VERSION "Version"

NS_ :

BS_:

BU_: Tester CCU ADC CCU_CCURT1 CCU_CCURT2 RLR RRR ZCUF ZCUL ZCUR ZCUT EMS IDM DCDC IPS NIDU DCUR OBC OPC LPC CPC EMCM GCU DCUF IPU BMS EOPR EVCC DCDC2 EDL SRS ECS EPS EPB RBM IBCS ICM IID IDC PHUDD AMP WHUD IMR INU IFC FAPA PAS PCS SCMR SCMRL SCMRR SCMRM MFS WSM DRM IDU FCP LBMSAD AVAS ATSS DLPFL FBLCM FLISD FLLCM FRLCM RLLCMA RLLCMB RRLCMA RRLCMB RLISD DLPML DLPMR TRM PSDL PSDR HVSPRL HVSPRR RFR SBM WCM ETC TBOX2 TBOX IDUR CBM PLGM TMC LPC2 SCMT RCP RRISD LBMS RLBMS CCURT1 CCURT2 RT1_C1 RT2_C3 RT1_C0 OTAWL RAS EBB RCICP WCMFR WCMRL SAS CD

BO_ 947 ADC_8: 64 ADC
 SG_ ADC_8_CRC : 7|16@0+ (1,0) [0|65535] ""  CCU,CCURT1,CCURT2,RT1_C1,RT2_C3,FAPA
 SG_ ADC_8_Counter : 23|8@0+ (1,0) [0|255] ""  CCU,CCURT1,CCURT2,RT1_C1,RT2_C3,FAPA
 SG_ ADC_LowBeamReq : 31|2@0+ (1,0) [0|3] ""  CCU,CCURT1,CCURT2,RT1_C1,RT2_C3,FAPA
 SG_ ADC_IHBC_HighBeamReq : 29|1@0+ (1,0) [0|1] ""  CCU,CCURT1,CCURT2,RT1_C1,RT2_C3,FAPA
 SG_ ADC_FlashReq : 28|2@0+ (1,0) [0|3] ""  CCU,CCURT1,CCURT2,RT1_C1,RT2_C3,FAPA
 SG_ ADC_PositionLampReq : 26|2@0+ (1,0) [0|3] ""  CCU,CCURT1,CCURT2,RT1_C1,RT2_C3,FAPA
 SG_ ADC_SunroofOpenCloseReq : 121|2@0+ (1,0) [0|3] ""  CCU
 SG_ ADC_SOCWakeupHVReq : 24|1@0+ (1,0) [0|1] ""  CCU,CCURT1,RT1_C1
 SG_ ADC_HVACCtrlReq : 39|1@0+ (1,0) [0|1] ""  CCU,CCURT1,RT1_C1,FAPA
 SG_ ADC_FFogLightReq : 38|2@0+ (1,0) [0|3] ""  CCU,CCURT1,CCURT2,RT1_C1,RT2_C3,FAPA
 SG_ ADC_RFogLightReq : 36|2@0+ (1,0) [0|3] ""  CCU,CCURT1,CCURT2,RT1_C1,RT2_C3,FAPA
 SG_ ADC_HornReq : 34|3@0+ (1,0) [0|7] ""  CCU,CCURT1,CCURT2,RT1_C1,RT2_C3,FAPA
 SG_ ADC_FWiperReq : 47|3@0+ (1,0) [0|7] ""  CCU,CCURT1,CCURT2,RT1_C0,RT1_C1,RT2_C3,FAPA
 SG_ ADC_RWiperReq : 44|3@0+ (1,0) [0|7] ""  CCU,CCURT1,CCURT2,RT1_C0,RT1_C1,RT2_C3,FAPA
 SG_ ADC_FWaterSprayReq : 41|2@0+ (1,0) [0|3] ""  CCU,CCURT1,CCURT2,RT1_C0,RT1_C1,RT2_C3,FAPA
 SG_ ADC_RWaterSprayReq : 55|2@0+ (1,0) [0|3] ""  CCU,CCURT1,CCURT2,RT1_C0,RT1_C1,RT2_C3,FAPA
 SG_ ADC_CCUReqVD : 53|1@0+ (1,0) [0|1] ""  CCU,CCURT1,CCURT2,RT1_C1,RT2_C3,FAPA
 SG_ ADC_WindowOpenReq : 50|1@0+ (1,0) [0|1] ""  CCU,CCURT1,CCURT2,RT1_C1,RT2_C3,FAPA
 SG_ ADC_WindowCloseReq : 49|1@0+ (1,0) [0|1] ""  CCU,CCURT1,CCURT2,RT1_C1,RT2_C3,FAPA
 SG_ ADC_PLGMOpenReq : 48|1@0+ (1,0) [0|1] ""  CCU,CCURT1,CCURT2,RT1_C1,RT2_C3,FAPA
 SG_ ADC_PLGMCloseReq : 63|1@0+ (1,0) [0|1] ""  CCU,CCURT1,CCURT2,RT1_C1,RT2_C3,FAPA
 SG_ ADC_FDemistReq : 60|2@0+ (1,0) [0|3] ""  CCU,CCURT1,RT1_C1,FAPA
 SG_ ADC_RDemistReq : 58|2@0+ (1,0) [0|3] ""  CCU,CCURT1,RT1_C1,FAPA
 SG_ ADC_ThmPostRun : 56|1@0+ (1,0) [0|1] ""  CCU,CCURT1,RT1_C1,FAPA
 SG_ ADC_DriverFaceWindReq : 71|2@0+ (1,0) [0|3] ""  CCU,CCURT1,RT1_C1,FAPA
 SG_ ADC_EcallReq : 69|1@0+ (1,0) [0|1] ""  CCU,CCURT1,RT1_C1,FAPA,TBOX
 SG_ ADC_FlowReq : 68|5@0+ (0.25,0) [0|7.75] "L/min"  CCU,CCURT1,RT1_C1,FAPA
 SG_ ADC_DriverSeatBeltPretightenReq : 79|1@0+ (1,0) [0|1] ""  CCU,CCURT1,RT1_C1,FAPA
 SG_ ADC_LockReq : 78|3@0+ (1,0) [0|7] ""  CCU,CCURT1,CCURT2,RT1_C1,RT2_C3,FAPA
 SG_ ADC_HoldLockReq : 75|2@0+ (1,0) [0|3] ""  CCU,CCURT1,CCURT2,RT1_C1,RT2_C3,FAPA
 SG_ ADC_RearMirrorReq : 73|2@0+ (1,0) [0|3] ""  CCU,CCURT1,CCURT2,RT1_C1,RT2_C3,FAPA
 SG_ ADC_HoldRearMirrorReq : 87|2@0+ (1,0) [0|3] ""  CCU,CCURT1,CCURT2,RT1_C1,RT2_C3,FAPA
 SG_ ADC_ADSLightReq : 90|3@0+ (1,0) [0|7] ""  CCU,CCURT1,CCURT2,RT1_C1,RT2_C3,FAPA
 SG_ ADC_DriverSeatBeltVibrWarnReq : 83|3@0+ (1,0) [0|7] ""  CCU,CCURT1,RT1_C1,FAPA
 SG_ ADC_FrtWindshildHeatReq : 92|2@0+ (1,0) [0|3] ""  CCU,CCURT1,RT1_C1,FAPA
 SG_ ADC_BeamSwReq : 94|2@0+ (1,0) [0|3] ""  CCU,CCURT1,CCURT2,RT1_C1,RT2_C3,FAPA
 SG_ IFC_SysCalibrationSt : 80|2@0+ (1,0) [0|3] ""  CCU,CCURT1,RT1_C1,FAPA
 SG_ ADC_ADBIHBCEnableReq : 99|2@0+ (1,0) [0|3] ""  CCU,CCURT1,CCURT2,RT1_C1,RT2_C3,FAPA
 SG_ ADC_LowPowerReqVD_A : 107|1@0+ (1,0) [0|1] ""  CCU,CCURT1,RT1_C1,INU,FAPA
 SG_ ADC_LowPowerReq_A : 106|2@0+ (1,0) [0|3] ""  CCU,CCURT1,RT1_C1,INU,FAPA
 SG_ ADC_MachineStatus : 124|3@0+ (1,0) [0|7] ""  CCU,CCURT1,RT1_C1,FAPA
 SG_ ADC_LowPowerFailReason : 127|3@0+ (1,0) [0|7] ""  CCU,CCURT1,RT1_C1,FAPA
 SG_ ADC_LightbarReq : 135|4@0+ (1,0) [0|15] "/"  CCU,CCURT1,RT1_C1,FAPA
 SG_ ADC_ChgPortControlReq : 129|2@0+ (1,0) [0|3] ""  CCU,CCURT1,RT1_C1,FAPA
 SG_ ADC_ChgPortHoldControlReq : 131|2@0+ (1,0) [0|3] ""  CCU,CCURT1,RT1_C1,FAPA
 SG_ ADC_ChargHoldReq : 137|2@0+ (1,0) [0|3] ""  CCU,CCURT1,RT1_C1,FAPA
 SG_ ADC_ChargReq : 139|2@0+ (1,0) [0|3] ""  CCU,CCURT1,RT1_C1,FAPA
 SG_ ADC_ChargGunHoldReq : 141|2@0+ (1,0) [0|3] ""  CCU,CCURT1,RT1_C1,FAPA
 SG_ ADC_ChargGunReq : 143|2@0+ (1,0) [0|3] ""  CCU,CCURT1,RT1_C1,FAPA
 SG_ ADC_MCURTTemp : 151|8@0+ (1,-40) [-40|215] "℃"  CCU,CCURT1,RT1_C1,FAPA
 SG_ ADC_SOCRTtemp : 159|8@0+ (1,-40) [-40|215] "℃"  CCU,CCURT1,RT1_C1,FAPA
 SG_ ADC_InteractLightReq : 167|5@0+ (1,0) [0|31] ""  CCU,CCURT1,RT1_C1,FAPA
 SG_ Reserved1 : 440|1@0+ (1,0) [0|1] ""  CCU,FAPA

BO_ 175 ADC_9: 64 ADC
 SG_ ADC_9_CRC : 7|16@0+ (1,0) [0|65535] ""  CCU
 SG_ ADC_9_Counter : 23|8@0+ (1,0) [0|255] ""  CCU
 SG_ ADC_PAAChallengeReceive : 29|1@0+ (1,0) [0|1] ""  CCU
 SG_ PAA_TimeStampYear : 28|5@0+ (1,2020) [2020|2051] "y"  CCU
 SG_ ADC_PAAChallenge1SBM : 39|8@0+ (1,0) [0|255] ""  CCU
 SG_ ADC_PAAChallenge2SBM : 47|8@0+ (1,0) [0|255] ""  CCU
 SG_ ADC_PAAChallenge1TEL : 55|8@0+ (1,0) [0|255] ""  CCU
 SG_ ADC_PAAChallenge2TEL : 63|8@0+ (1,0) [0|255] ""  CCU
 SG_ PAA_TimeStampMonth : 71|4@0+ (1,0) [1|12] "m"  CCU
 SG_ PAA_TimeStampDay : 67|5@0+ (1,0) [1|31] "h"  CCU
 SG_ PAA_TimeStampHour : 78|5@0+ (1,0) [0|23] "d"  CCU
 SG_ PAA_TimeStampMin : 73|6@0+ (1,0) [0|59] "min"  CCU
 SG_ PAA_TimeStampSec : 83|6@0+ (1,0) [0|59] "s"  CCU
 SG_ PAA_TimeStampMilliSec : 93|4@0+ (100,0) [0|900] "ms"  CCU
 SG_ ADC_APAActPushSt : 97|2@0+ (1,0) [0|3] ""  CCU
 SG_ PAA_DVRTriggerId : 89|5@0+ (1,0) [0|31] ""  CCU
 SG_ PAA_DVRTrigger : 100|1@0+ (1,0) [0|1] ""  CCU
 SG_ ADC_LCAEnableSt : 99|2@0+ (1,0) [0|3] ""  CCU
 SG_ ADC_HPALearningPathUniqueID : 111|64@0+ (1,0) [0|0] ""  CCU

BO_ 135 ADC_VIMCode: 16 ADC
 SG_ ADC_VIMCode : 7|128@0+ (1,0) [0|3.40282366920938E+38] ""  CCU,CCURT1,RT1_C0

BO_ 1234 RLR_DiagCode: 64 ADC
 SG_ RLR_DTCCode : 7|512@0+ (1,0) [0|0] ""  CCU

BO_ 1235 RRR_DiagCode: 64 ADC
 SG_ RRR_DTCCode : 7|512@0+ (1,0) [0|0] ""  CCU

BO_ 1785 ADC_MCU_Diag_Response: 64 ADC
 SG_ ADC_MCU_Diag_Response : 7|64@0+ (1,0) [0|0] ""  Tester

BO_ 127 ADC_IMMO: 1 ADC
 SG_ ADC_IMMO : 7|8@0+ (1,0) [0|255] ""  CCU,CCURT1,RT1_C0

BO_ 1934 ADC_Diag_Tx: 64 ADC
 SG_ ADC_Diag_Response : 7|512@0+ (1,0) [0|0] ""  Vector__XXX

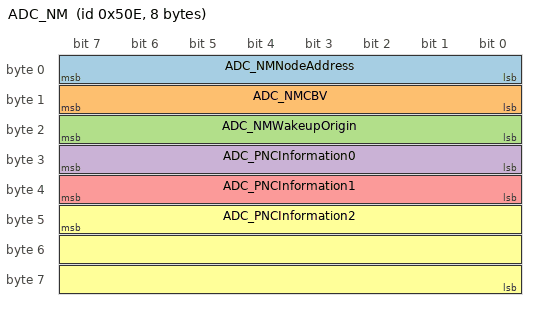
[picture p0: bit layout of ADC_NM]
BO_ 1294 ADC_NM: 8 ADC
 SG_ ADC_NMNodeAddress : 7|8@0+ (1,0) [0|255] ""  CCU,CCURT1
 SG_ ADC_NMCBV : 15|8@0+ (1,0) [0|0] ""  CCU,CCURT1
 SG_ ADC_NMWakeupOrigin : 23|8@0+ (1,0) [0|255] ""  CCU,CCURT1
 SG_ ADC_PNCInformation0 : 31|8@0+ (1,0) [0|255] ""  CCU,CCURT1
 SG_ ADC_PNCInformation1 : 39|8@0+ (1,0) [0|255] ""  CCU,CCURT1
 SG_ ADC_PNCInformation2 : 47|24@0+ (1,0) [0|0] ""  CCU,CCURT1

BO_ 1188 ADC_BigDataDTC: 64 ADC
 SG_ ADC_DTC : 7|512@0+ (1,0) [0|0] ""  CCU

BO_ 969 ADC_14: 64 ADC
 SG_ ADAS_RemoterParkingOnlineOrNot : 31|8@0+ (1,0) [0|255] ""  CCU,CCURT1,RT1_C0,RT1_C1
 SG_ ADC_RpaParkAuthn : 33|2@0+ (1,0) [0|3] ""  CCU,CCURT1,RT1_C1
 SG_ ADC_RemParkPatSel : 35|2@0+ (1,0) [0|2] ""  CCU,CCURT1,RT1_C1
 SG_ ADC_ParkDirCfm : 39|4@0+ (1,0) [0|8] ""  CCU,CCURT1,RT1_C1
 SG_ ADC_ParkStMac : 44|5@0+ (1,0) [0|31] ""  CCU,CCURT1,RT1_C1
 SG_ ADC_PwrOnOffReq : 47|3@0+ (1,0) [0|7] ""  CCU,CCURT1,RT1_C0,RT1_C1
 SG_ ADC_ParkOutDir_ParaLe : 48|1@0+ (1,0) [0|1] ""  CCU
 SG_ ADC_ParkOutDir_ParaRi : 49|1@0+ (1,0) [0|1] ""  CCU
 SG_ ADC_ParkOutDir_PerpFwd : 50|1@0+ (1,0) [0|1] ""  CCU
 SG_ ADC_ParkOutDir_PerpLeFwd : 51|1@0+ (1,0) [0|1] ""  CCU
 SG_ ADC_ParkOutDir_PerpRiFwd : 52|1@0+ (1,0) [0|1] ""  CCU
 SG_ ADC_ParkOutDir_PerpLeBack : 53|1@0+ (1,0) [0|1] ""  CCU
 SG_ ADC_ParkOutDir_PerpRiBack : 54|1@0+ (1,0) [0|1] ""  CCU
 SG_ ADC_ParkOutDir_PerpBack : 55|1@0+ (1,0) [0|1] ""  CCU
 SG_ ADC_APA_RPAFctUnavlMsg1 : 56|1@0+ (1,0) [0|1] ""  CCU
 SG_ ADC_APA_RPAFctUnavlMsg2 : 57|1@0+ (1,0) [0|1] ""  CCU
 SG_ ADC_APA_RPAFctUnavlMsg3 : 58|1@0+ (1,0) [0|1] ""  CCU
 SG_ ADC_APA_RPAFctUnavlMsg4 : 59|1@0+ (1,0) [0|1] ""  CCU
 SG_ ADC_APA_RPAFctUnavlMsg5 : 60|1@0+ (1,0) [0|1] ""  CCU
 SG_ ADC_APA_RPAFctUnavlMsg6 : 61|1@0+ (1,0) [0|1] ""  CCU
 SG_ ADC_APA_RPAFctUnavlMsg7 : 62|1@0+ (1,0) [0|1] ""  CCU
 SG_ ADC_APA_RPAFctUnavlMsg8 : 63|1@0+ (1,0) [0|1] ""  CCU
 SG_ ADC_APA_RPAFctUnavlMsg9 : 64|1@0+ (1,0) [0|1] ""  CCU
 SG_ ADC_APA_RPAFctUnavlMsg10 : 65|1@0+ (1,0) [0|1] ""  CCU
 SG_ ADC_APA_RPAFctUnavlMsg11 : 66|1@0+ (1,0) [0|1] ""  CCU
 SG_ ADC_APA_RPAFctUnavlMsg12 : 67|1@0+ (1,0) [0|1] ""  CCU
 SG_ ADC_APA_RPAFctUnavlMsg13 : 68|1@0+ (1,0) [0|1] ""  CCU
 SG_ ADC_APA_RPAFctUnavlMsg14 : 69|1@0+ (1,0) [0|1] ""  CCU
 SG_ ADC_APA_RPAFctUnavlMsg15 : 70|1@0+ (1,0) [0|1] ""  CCU
 SG_ ADC_APA_RPAFctUnavlMsg16 : 71|1@0+ (1,0) [0|1] ""  CCU
 SG_ ADC_APA_RPAFctUnavlMsg17 : 72|1@0+ (1,0) [0|1] ""  CCU
 SG_ ADC_APA_RPAFctUnavlMsg18 : 73|1@0+ (1,0) [0|1] ""  CCU
 SG_ ADC_APA_RPAFctUnavlMsg19 : 74|1@0+ (1,0) [0|1] ""  CCU
 SG_ ADC_APA_RPAFctUnavlMsg20 : 75|1@0+ (1,0) [0|1] ""  CCU
 SG_ ADC_APA_RPAFctUnavlMsg21 : 76|1@0+ (1,0) [0|1] ""  CCU
 SG_ ADC_APA_RPAFctUnavlMsg22 : 77|1@0+ (1,0) [0|1] ""  CCU
 SG_ ADC_APA_RPAFctUnavlMsg23 : 78|1@0+ (1,0) [0|1] ""  CCU
 SG_ ADC_APA_RPAFctUnavlMsg24 : 79|1@0+ (1,0) [0|1] ""  CCU
 SG_ ADC_APA_RPAFctUnavlMsg25 : 80|1@0+ (1,0) [0|1] ""  CCU
 SG_ ADC_APA_RPACnclMsg1 : 81|1@0+ (1,0) [0|1] ""  CCU
 SG_ ADC_APA_RPACnclMsg2 : 82|1@0+ (1,0) [0|1] ""  CCU
 SG_ ADC_APA_RPACnclMsg3 : 83|1@0+ (1,0) [0|1] ""  CCU
 SG_ ADC_APA_RPACnclMsg4 : 84|1@0+ (1,0) [0|1] ""  CCU
 SG_ ADC_APA_RPACnclMsg5 : 85|1@0+ (1,0) [0|1] ""  CCU
 SG_ ADC_APA_RPACnclMsg6 : 86|1@0+ (1,0) [0|1] ""  CCU
 SG_ ADC_APA_RPACnclMsg7 : 87|1@0+ (1,0) [0|1] ""  CCU
 SG_ ADC_APA_RPACnclMsg8 : 88|1@0+ (1,0) [0|1] ""  CCU
 SG_ ADC_APA_RPACnclMsg9 : 89|1@0+ (1,0) [0|1] ""  CCU
 SG_ ADC_APA_RPACnclMsg10 : 90|1@0+ (1,0) [0|1] ""  CCU
 SG_ ADC_APA_RPACnclMsg11 : 91|1@0+ (1,0) [0|1] ""  CCU
 SG_ ADC_APA_RPACnclMsg12 : 92|1@0+ (1,0) [0|1] ""  CCU
 SG_ ADC_APA_RPACnclMsg13 : 93|1@0+ (1,0) [0|1] ""  CCU
 SG_ ADC_APA_RPACnclMsg14 : 94|1@0+ (1,0) [0|1] ""  CCU
 SG_ ADC_APA_RPACnclMsg15 : 95|1@0+ (1,0) [0|1] ""  CCU
 SG_ ADC_APA_RPACnclMsg16 : 96|1@0+ (1,0) [0|1] ""  CCU
 SG_ ADC_APA_RPACnclMsg17 : 97|1@0+ (1,0) [0|1] ""  CCU
 SG_ ADC_APA_RPACnclMsg18 : 98|1@0+ (1,0) [0|1] ""  CCU
 SG_ ADC_APA_RPACnclMsg19 : 99|1@0+ (1,0) [0|1] ""  CCU
 SG_ ADC_APA_RPACnclMsg20 : 100|1@0+ (1,0) [0|1] ""  CCU
 SG_ ADC_APA_RPAPauseMsg1 : 101|1@0+ (1,0) [0|1] ""  CCU
 SG_ ADC_APA_RPAPauseMsg2 : 102|1@0+ (1,0) [0|1] ""  CCU
 SG_ ADC_APA_RPAPauseMsg3 : 103|1@0+ (1,0) [0|1] ""  CCU
 SG_ ADC_APA_RPAPauseMsg4 : 104|1@0+ (1,0) [0|1] ""  CCU
 SG_ ADC_APA_RPAPauseMsg5 : 105|1@0+ (1,0) [0|1] ""  CCU
 SG_ ADC_APA_RPAPauseMsg6 : 106|1@0+ (1,0) [0|1] ""  CCU
 SG_ ADC_APA_RPAPauseMsg7 : 107|1@0+ (1,0) [0|1] ""  CCU
 SG_ ADC_APA_RPAPauseMsg8 : 108|1@0+ (1,0) [0|1] ""  CCU
 SG_ ADC_APA_RPAPauseMsg9 : 109|1@0+ (1,0) [0|1] ""  CCU
 SG_ ADC_APA_RPAPauseMsg10 : 110|1@0+ (1,0) [0|1] ""  CCU
 SG_ ADC_PathPlanPos1X : 119|10@0+ (0.1,-50) [-50|50] "m"  CCU
 SG_ ADC_PathPlanPos1Y : 125|10@0+ (0.1,-50) [-50|50] "m"  CCU
 SG_ ADC_PathPlanPos2X : 131|10@0+ (0.1,-50) [-50|50] "m"  CCU
 SG_ ADC_PathPlanPos2Y : 137|10@0+ (0.1,-50) [-50|50] "m"  CCU
 SG_ ADC_PathPlanPos3X : 159|10@0+ (0.1,-50) [-50|50] "m"  CCU
 SG_ ADC_PathPlanPos3Y : 165|10@0+ (0.1,-50) [-50|50] "m"  CCU
 SG_ ADC_PathPlanPos4X : 171|10@0+ (0.1,-50) [-50|50] "m"  CCU
 SG_ ADC_PathPlanPos4Y : 177|10@0+ (0.1,-50) [-50|50] "m"  CCU
 SG_ ADC_PathPlanPos5X : 199|10@0+ (0.1,-50) [-50|50] "m"  CCU
 SG_ ADC_PathPlanPos5Y : 205|10@0+ (0.1,-50) [-50|50] "m"  CCU
 SG_ ADC_PathPlanPos6X : 211|10@0+ (0.1,-50) [-50|50] "m"  CCU
 SG_ ADC_PathPlanPos6Y : 217|10@0+ (0.1,-50) [-50|50] "m"  CCU
 SG_ ADC_PathPlanPos7X : 239|10@0+ (0.1,-50) [-50|50] "m"  CCU
 SG_ ADC_PathPlanPos7Y : 245|10@0+ (0.1,-50) [-50|50] "m"  CCU
 SG_ ADC_PathPlanPos8X : 251|10@0+ (0.1,-50) [-50|50] "m"  CCU
 SG_ ADC_PathPlanPos8Y : 257|10@0+ (0.1,-50) [-50|50] "m"  CCU
 SG_ ADC_PathPlanPos9X : 279|10@0+ (0.1,-50) [-50|50] "m"  CCU
 SG_ ADC_PathPlanPos9Y : 285|10@0+ (0.1,-50) [-50|50] "m"  CCU
 SG_ ADC_PathPlanPos10X : 291|10@0+ (0.1,-50) [-50|50] "m"  CCU
 SG_ ADC_PathPlanPos10Y : 297|10@0+ (0.1,-50) [-50|50] "m"  CCU
 SG_ ADC_PathPlanPos11X : 319|10@0+ (0.1,-50) [-50|50] "m"  CCU
 SG_ ADC_PathPlanPos11Y : 325|10@0+ (0.1,-50) [-50|50] "m"  CCU
 SG_ ADC_PathPlanPos12X : 331|10@0+ (0.1,-50) [-50|50] "m"  CCU
 SG_ ADC_PathPlanPos12Y : 337|10@0+ (0.1,-50) [-50|50] "m"  CCU
 SG_ ADC_PathPlanPos13X : 359|10@0+ (0.1,-50) [-50|50] "m"  CCU
 SG_ ADC_PathPlanPos13Y : 365|10@0+ (0.1,-50) [-50|50] "m"  CCU
 SG_ ADC_PathPlanPos14X : 371|10@0+ (0.1,-50) [-50|50] "m"  CCU
 SG_ ADC_PathPlanPos14Y : 377|10@0+ (0.1,-50) [-50|50] "m"  CCU
 SG_ ADC_PathPlanPos15X : 399|10@0+ (0.1,-50) [-50|50] "m"  CCU
 SG_ ADC_PathPlanPos15Y : 405|10@0+ (0.1,-50) [-50|50] "m"  CCU
 SG_ ADC_PathPlanPos16X : 411|10@0+ (0.1,-50) [-50|50] "m"  CCU
 SG_ ADC_PathPlanPos16Y : 417|10@0+ (0.1,-50) [-50|50] "m"  CCU
 SG_ ADC_PathPlanPos17X : 439|10@0+ (0.1,-50) [-50|50] "m"  CCU
 SG_ ADC_PathPlanPos17Y : 445|10@0+ (0.1,-50) [-50|50] "m"  CCU
 SG_ ADC_PathPlanPos18X : 451|10@0+ (0.1,-50) [-50|50] "m"  CCU
 SG_ ADC_PathPlanPos18Y : 457|10@0+ (0.1,-50) [-50|50] "m"  CCU
 SG_ ADC_PathPlanPos19X : 479|10@0+ (0.1,-50) [-50|50] "m"  CCU
 SG_ ADC_PathPlanPos19Y : 485|10@0+ (0.1,-50) [-50|50] "m"  CCU
 SG_ ADC_PathPlanPos20X : 491|10@0+ (0.1,-50) [-50|50] "m"  CCU
 SG_ ADC_PathPlanPos20Y : 497|10@0+ (0.1,-50) [-50|50] "m"  CCU

BO_ 970 ADC_15: 64 ADC
 SG_ ADC_AutEve : 27|4@0+ (1,0) [0|15] ""  CCU
 SG_ ADC_SeldParkID : 31|4@0+ (1,0) [0|10] ""  CCU
 SG_ ADC_VehParkMod : 39|3@0+ (1,0) [0|2] ""  CCU
 SG_ ADC_ParkProgs : 36|7@0+ (1,0) [0|100] "%"  CCU
 SG_ ADC_ParkRmngDst : 479|9@0+ (0.1,0) [0|50] "m"  CCU
 SG_ ADC_ObstclDst : 55|5@0+ (1,0) [0|31] ""  CCU
 SG_ ADC_parkInterruptDuration : 50|8@0+ (1,0) [0|255] "s"  CCU
 SG_ ADC_EPS_SteeringAngle : 58|16@0+ (0.1,-780) [-780|780] "deg"  CCU,CCURT2,RT2_C3
 SG_ ADC_FrontEndParkInAvl : 45|2@0+ (1,0) [0|3] ""  CCU
 SG_ ADC_RPAobscancelCfm : 96|1@0+ (1,0) [0|1] ""  CCU

CM_ SG_ 947 ADC_8_CRC "E2E Profile 5 CRC";
CM_ SG_ 947 ADC_8_Counter "E2E Profile 5 Counter";
CM_ SG_ 947 ADC_LowBeamReq "Low Beam Request?";
CM_ SG_ 947 ADC_IHBC_HighBeamReq "IHBC High Beam Request?";
CM_ SG_ 947 ADC_FlashReq "Flash High Beam Request?";
CM_ SG_ 947 ADC_PositionLampReq "Position Lamp Request?";
CM_ SG_ 947 ADC_SunroofOpenCloseReq "Sunroof control";
CM_ SG_ 947 ADC_SOCWakeupHVReq "ADC sends the signal to VCU when IGN is off, in order to request VCU to provide the DCDC for pre-start and post-run of ADC.";
CM_ SG_ 947 ADC_HVACCtrlReq "Air conditioner request";
CM_ SG_ 947 ADC_FFogLightReq "Front Fog Light Request?";
CM_ SG_ 947 ADC_RFogLightReq "Rear Fog Light Request?";
CM_ SG_ 947 ADC_HornReq "Horn Request";
CM_ SG_ 947 ADC_FWiperReq "Front Wiper Request";
CM_ SG_ 947 ADC_RWiperReq "Rear Wiper Request";
CM_ SG_ 947 ADC_FWaterSprayReq "Front Water Spray Request";
CM_ SG_ 947 ADC_RWaterSprayReq "Rear Water Spray Request";
CM_ SG_ 947 ADC_CCUReqVD "CCU Request valid";
CM_ SG_ 947 ADC_WindowOpenReq "Window Open Request";
CM_ SG_ 947 ADC_WindowCloseReq "Window Close Request";
CM_ SG_ 947 ADC_PLGMOpenReq "PLGM Open Request";
CM_ SG_ 947 ADC_PLGMCloseReq "PLGM Close Request";
CM_ SG_ 947 ADC_FDemistReq "Front window Demist Active Request";
CM_ SG_ 947 ADC_RDemistReq "Rear window Demist Active Request";
CM_ SG_ 947 ADC_ThmPostRun "ADC cooling demand flag request";
CM_ SG_ 947 ADC_DriverFaceWindReq "Driver Face Wind Request";
CM_ SG_ 947 ADC_EcallReq "ADAS E-call Request";
CM_ SG_ 947 ADC_FlowReq "ADC cooling liquid flow rate request";
CM_ SG_ 947 ADC_DriverSeatBeltPretightenReq "Driver Seat Belt Pretighten Request";
CM_ SG_ 947 ADC_LockReq "Doors Lock/Unlock Request";
CM_ SG_ 947 ADC_HoldLockReq "Hold Doors Lock/Unlock Request";
CM_ SG_ 947 ADC_RearMirrorReq "Rear Mirror Fold/Unfold Request";
CM_ SG_ 947 ADC_HoldRearMirrorReq "Hold Rear Mirror Fold/Unfold Request";
CM_ SG_ 947 ADC_ADSLightReq "ADS light request";
CM_ SG_ 947 ADC_DriverSeatBeltVibrWarnReq "ADAS active driver seat belt vibration warning request";
CM_ SG_ 947 ADC_FrtWindshildHeatReq "Front windshield heating wire control request";
CM_ SG_ 947 ADC_BeamSwReq "Head light switch control request（turn on automatic light）";
CM_ SG_ 947 IFC_SysCalibrationSt "IFC(Intelligent Front Camera) system calibration ststus";
CM_ SG_ 947 ADC_ADBIHBCEnableReq "ADB and IHBC enable request";
CM_ SG_ 947 ADC_MachineStatus "ADC Machine Status";
CM_ SG_ 947 ADC_LowPowerFailReason "The Reason why ADC  cannot change to LowPowerMode";
CM_ SG_ 947 ADC_LightbarReq "ADC’s Light bar request";
CM_ SG_ 947 ADC_ChgPortControlReq "Charging Port Close/Open Request";
CM_ SG_ 947 ADC_ChgPortHoldControlReq "Hold Charging Port Close/Open Request";
CM_ SG_ 947 ADC_ChargHoldReq "Hold Charging  Start/Stop Request";
CM_ SG_ 947 ADC_ChargReq "Charging  Start/Stop Request";
CM_ SG_ 947 ADC_ChargGunHoldReq "Hold Charging  Gun Close/Open Request";
CM_ SG_ 947 ADC_ChargGunReq "Charging  Gun Close/Open Request";
CM_ SG_ 947 ADC_MCURTTemp "Real-time Temperature of ADC MCU";
CM_ SG_ 947 ADC_SOCRTtemp "Real-time Temperature of ADC SOC";
CM_ SG_ 947 ADC_InteractLightReq "Interact light request";
CM_ SG_ 175 ADC_9_CRC "E2E Profile 5 CRC";
CM_ SG_ 175 ADC_9_Counter "E2E Profile 5 Counter";
CM_ SG_ 175 ADC_PAAChallengeReceive "PAA Receive Challenge Singal";
CM_ SG_ 175 PAA_TimeStampYear "Time Stamp Year number";
CM_ SG_ 175 ADC_PAAChallenge1SBM "RPA Challenge SBM Singal1";
CM_ SG_ 175 ADC_PAAChallenge2SBM "RPA Challenge SBM Singal2";
CM_ SG_ 175 ADC_PAAChallenge1TEL "Challenge SBM Singal1";
CM_ SG_ 175 ADC_PAAChallenge2TEL "Challenge SBM Singal2";
CM_ SG_ 175 PAA_TimeStampMonth "Time Stamp Month number";
CM_ SG_ 175 PAA_TimeStampDay "Time Stamp Day number";
CM_ SG_ 175 PAA_TimeStampHour "Time Stamp Hour number";
CM_ SG_ 175 PAA_TimeStampMin "Time Stamp Minute number";
CM_ SG_ 175 PAA_TimeStampSec "Time Stamp Second number";
CM_ SG_ 175 PAA_TimeStampMilliSec "Time Stamp Millisecond number";
CM_ SG_ 175 ADC_APAActPushSt "Push APA sensless entry parking";
CM_ SG_ 175 PAA_DVRTriggerId "Indicate PAA DVR  event type";
CM_ SG_ 175 PAA_DVRTrigger "PAA DVR Trigger Status";
CM_ SG_ 175 ADC_LCAEnableSt "LCA button Status";
CM_ SG_ 175 ADC_HPALearningPathUniqueID "The unique ID of the learning path";
CM_ SG_ 135 ADC_VIMCode "ADC Code return to VIM";
CM_ SG_ 1234 RLR_DTCCode "RLR DTC code and status";
CM_ SG_ 1235 RRR_DTCCode "RRR DTC code and status";
CM_ SG_ 1785 ADC_MCU_Diag_Response "Diagnostic physical of ADC_MCU request";
CM_ SG_ 127 ADC_IMMO "ADC feedback anti-theft results";
CM_ SG_ 1934 ADC_Diag_Response "ADC diagnostic response";
CM_ SG_ 1294 ADC_NMNodeAddress "ADC node address";
CM_ SG_ 1294 ADC_NMCBV "ADC Network management control bit vector";
CM_ SG_ 1294 ADC_NMWakeupOrigin "Origin of the wake up";
CM_ SG_ 1294 ADC_PNCInformation0 "PNC Information";
CM_ SG_ 1294 ADC_PNCInformation1 "PNC Information";
CM_ SG_ 1294 ADC_PNCInformation2 "PNC Information";
CM_ SG_ 1188 ADC_DTC "信号用于上报ADC的故障信息，信号长度64个字节，存储16个故障码?每个故障码由4个字节构成：DTCHighByte(Hex)DTCMiddleByte(Hex)DTCLowByte(Hex)StatusOfDTC";
CM_ SG_ 969 ADAS_RemoterParkingOnlineOrNot "Indicate RemoterParkingOnline Or Not";
CM_ SG_ 969 ADC_RpaParkAuthn "RPA phone authorized_confirm state";
CM_ SG_ 969 ADC_RemParkPatSel "Parkin or Parkout";
CM_ SG_ 969 ADC_ParkDirCfm "Parkout direction";
CM_ SG_ 969 ADC_ParkStMac "APA state machine";
CM_ SG_ 969 ADC_PwrOnOffReq "Vehicle power-on and power-off control request";
CM_ SG_ 969 ADC_ParkOutDir_ParaLe "Parallel Left parkout direction";
CM_ SG_ 969 ADC_ParkOutDir_ParaRi "Parallel right parkout direction";
CM_ SG_ 969 ADC_ParkOutDir_PerpFwd "Perpendicular Forward parkout direction";
CM_ SG_ 969 ADC_ParkOutDir_PerpLeFwd "Perpendicular left Forward parkout direction";
CM_ SG_ 969 ADC_ParkOutDir_PerpRiFwd "Perpendicular right Forward parkout direction";
CM_ SG_ 969 ADC_ParkOutDir_PerpLeBack "Perpendicular left backward parkout direction";
CM_ SG_ 969 ADC_ParkOutDir_PerpRiBack "Perpendicular right backward parkout direction";
CM_ SG_ 969 ADC_ParkOutDir_PerpBack "Perpendicular backward parkout direction";
CM_ SG_ 969 ADC_APA_RPAFctUnavlMsg1 "RPA unavailable reason 1";
CM_ SG_ 969 ADC_APA_RPAFctUnavlMsg2 "RPA unavailable reason 2";
CM_ SG_ 969 ADC_APA_RPAFctUnavlMsg3 "RPA unavailable reason 3";
CM_ SG_ 969 ADC_APA_RPAFctUnavlMsg4 "RPA unavailable reason 4";
CM_ SG_ 969 ADC_APA_RPAFctUnavlMsg5 "RPA unavailable reason 5";
CM_ SG_ 969 ADC_APA_RPAFctUnavlMsg6 "RPA unavailable reason 6";
CM_ SG_ 969 ADC_APA_RPAFctUnavlMsg7 "RPA unavailable reason 7";
CM_ SG_ 969 ADC_APA_RPAFctUnavlMsg8 "RPA unavailable reason 8";
CM_ SG_ 969 ADC_APA_RPAFctUnavlMsg9 "RPA unavailable reason 9";
CM_ SG_ 969 ADC_APA_RPAFctUnavlMsg10 "RPA unavailable reason 10";
CM_ SG_ 969 ADC_APA_RPAFctUnavlMsg11 "RPA unavailable reason 11";
CM_ SG_ 969 ADC_APA_RPAFctUnavlMsg12 "RPA unavailable reason 12";
CM_ SG_ 969 ADC_APA_RPAFctUnavlMsg13 "RPA unavailable reason 13";
CM_ SG_ 969 ADC_APA_RPAFctUnavlMsg14 "RPA unavailable reason 14";
CM_ SG_ 969 ADC_APA_RPAFctUnavlMsg15 "RPA unavailable reason 15";
CM_ SG_ 969 ADC_APA_RPAFctUnavlMsg16 "RPA unavailable reason 16";
CM_ SG_ 969 ADC_APA_RPAFctUnavlMsg17 "RPA unavailable reason 17";
CM_ SG_ 969 ADC_APA_RPAFctUnavlMsg18 "RPA unavailable reason 18";
CM_ SG_ 969 ADC_APA_RPAFctUnavlMsg19 "RPA unavailable reason 19";
CM_ SG_ 969 ADC_APA_RPAFctUnavlMsg20 "RPA unavailable reason 20";
CM_ SG_ 969 ADC_APA_RPAFctUnavlMsg21 "RPA unavailable reason 21";
CM_ SG_ 969 ADC_APA_RPAFctUnavlMsg22 "RPA unavailable reason 22";
CM_ SG_ 969 ADC_APA_RPAFctUnavlMsg23 "RPA unavailable reason 23";
CM_ SG_ 969 ADC_APA_RPAFctUnavlMsg24 "RPA unavailable reason 24";
CM_ SG_ 969 ADC_APA_RPAFctUnavlMsg25 "RPA unavailable reason 25";
CM_ SG_ 969 ADC_APA_RPACnclMsg1 "RPA cancel reason 1";
CM_ SG_ 969 ADC_APA_RPACnclMsg2 "RPA cancel reason 2";
CM_ SG_ 969 ADC_APA_RPACnclMsg3 "RPA cancel reason 3";
CM_ SG_ 969 ADC_APA_RPACnclMsg4 "RPA cancel reason 4";
CM_ SG_ 969 ADC_APA_RPACnclMsg5 "RPA cancel reason 5";
CM_ SG_ 969 ADC_APA_RPACnclMsg6 "RPA cancel reason 6";
CM_ SG_ 969 ADC_APA_RPACnclMsg7 "RPA cancel reason 7";
CM_ SG_ 969 ADC_APA_RPACnclMsg8 "RPA cancel reason 8";
CM_ SG_ 969 ADC_APA_RPACnclMsg9 "RPA cancel reason 9";
CM_ SG_ 969 ADC_APA_RPACnclMsg10 "RPA cancel reason 10";
CM_ SG_ 969 ADC_APA_RPACnclMsg11 "RPA cancel reason 11";
CM_ SG_ 969 ADC_APA_RPACnclMsg12 "RPA cancel reason 12";
CM_ SG_ 969 ADC_APA_RPACnclMsg13 "RPA cancel reason 13";
CM_ SG_ 969 ADC_APA_RPACnclMsg14 "RPA cancel reason 14";
CM_ SG_ 969 ADC_APA_RPACnclMsg15 "RPA cancel reason 15";
CM_ SG_ 969 ADC_APA_RPACnclMsg16 "RPA cancel reason 16";
CM_ SG_ 969 ADC_APA_RPACnclMsg17 "RPA cancel reason 17";
CM_ SG_ 969 ADC_APA_RPACnclMsg18 "RPA cancel reason 18";
CM_ SG_ 969 ADC_APA_RPACnclMsg19 "RPA cancel reason 19";
CM_ SG_ 969 ADC_APA_RPACnclMsg20 "RPA cancel reason 20";
CM_ SG_ 969 ADC_APA_RPAPauseMsg1 "RPA pause reason 1";
CM_ SG_ 969 ADC_APA_RPAPauseMsg2 "RPA pause reason 2";
CM_ SG_ 969 ADC_APA_RPAPauseMsg3 "RPA pause reason 3";
CM_ SG_ 969 ADC_APA_RPAPauseMsg4 "RPA pause reason 4";
CM_ SG_ 969 ADC_APA_RPAPauseMsg5 "RPA pause reason 5";
CM_ SG_ 969 ADC_APA_RPAPauseMsg6 "RPA pause reason 6";
CM_ SG_ 969 ADC_APA_RPAPauseMsg7 "RPA pause reason 7";
CM_ SG_ 969 ADC_APA_RPAPauseMsg8 "RPA pause reason 8";
CM_ SG_ 969 ADC_APA_RPAPauseMsg9 "RPA pause reason 9";
CM_ SG_ 969 ADC_APA_RPAPauseMsg10 "RPA pause reason 10";
CM_ SG_ 969 ADC_PathPlanPos1X "ADC_PathPlanPos1_x";
CM_ SG_ 969 ADC_PathPlanPos1Y "ADC_PathPlanPos1_y";
CM_ SG_ 969 ADC_PathPlanPos2X "ADC_PathPlanPos2_x";
CM_ SG_ 969 ADC_PathPlanPos2Y "ADC_PathPlanPos2_y";
CM_ SG_ 969 ADC_PathPlanPos3X "ADC_PathPlanPos3_x";
CM_ SG_ 969 ADC_PathPlanPos3Y "ADC_PathPlanPos3_y";
CM_ SG_ 969 ADC_PathPlanPos4X "ADC_PathPlanPos4_x";
CM_ SG_ 969 ADC_PathPlanPos4Y "ADC_PathPlanPos4_y";
CM_ SG_ 969 ADC_PathPlanPos5X "ADC_PathPlanPos5_x";
CM_ SG_ 969 ADC_PathPlanPos5Y "ADC_PathPlanPos5_y";
CM_ SG_ 969 ADC_PathPlanPos6X "ADC_PathPlanPos6_x";
CM_ SG_ 969 ADC_PathPlanPos6Y "ADC_PathPlanPos6_y";
CM_ SG_ 969 ADC_PathPlanPos7X "ADC_PathPlanPos7_x";
CM_ SG_ 969 ADC_PathPlanPos7Y "ADC_PathPlanPos7_y";
CM_ SG_ 969 ADC_PathPlanPos8X "ADC_PathPlanPos8_x";
CM_ SG_ 969 ADC_PathPlanPos8Y "ADC_PathPlanPos8_y";
CM_ SG_ 969 ADC_PathPlanPos9X "ADC_PathPlanPos9_x";
CM_ SG_ 969 ADC_PathPlanPos9Y "ADC_PathPlanPos9_y";
CM_ SG_ 969 ADC_PathPlanPos10X "ADC_PathPlanPos10_x";
CM_ SG_ 969 ADC_PathPlanPos10Y "ADC_PathPlanPos10_y";
CM_ SG_ 969 ADC_PathPlanPos11X "ADC_PathPlanPos11_x";
CM_ SG_ 969 ADC_PathPlanPos11Y "ADC_PathPlanPos11_y";
CM_ SG_ 969 ADC_PathPlanPos12X "ADC_PathPlanPos12_x";
CM_ SG_ 969 ADC_PathPlanPos12Y "ADC_PathPlanPos12_y";
CM_ SG_ 969 ADC_PathPlanPos13X "ADC_PathPlanPos13_x";
CM_ SG_ 969 ADC_PathPlanPos13Y "ADC_PathPlanPos13_y";
CM_ SG_ 969 ADC_PathPlanPos14X "ADC_PathPlanPos14_x";
CM_ SG_ 969 ADC_PathPlanPos14Y "ADC_PathPlanPos14_y";
CM_ SG_ 969 ADC_PathPlanPos15X "ADC_PathPlanPos15_x";
CM_ SG_ 969 ADC_PathPlanPos15Y "ADC_PathPlanPos15_y";
CM_ SG_ 969 ADC_PathPlanPos16X "ADC_PathPlanPos16_x";
CM_ SG_ 969 ADC_PathPlanPos16Y "ADC_PathPlanPos16_y";
CM_ SG_ 969 ADC_PathPlanPos17X "ADC_PathPlanPos17_x";
CM_ SG_ 969 ADC_PathPlanPos17Y "ADC_PathPlanPos17_y";
CM_ SG_ 969 ADC_PathPlanPos18X "ADC_PathPlanPos18_x";
CM_ SG_ 969 ADC_PathPlanPos18Y "ADC_PathPlanPos18_y";
CM_ SG_ 969 ADC_PathPlanPos19X "ADC_PathPlanPos19_x";
CM_ SG_ 969 ADC_PathPlanPos19Y "ADC_PathPlanPos19_y";
CM_ SG_ 969 ADC_PathPlanPos20X "ADC_PathPlanPos20_x";
CM_ SG_ 969 ADC_PathPlanPos20Y "ADC_PathPlanPos20_y";
CM_ SG_ 970 ADC_AutEve "Intelligent Driving Events (RPA indicators)";
CM_ SG_ 970 ADC_SeldParkID "RPA select Park ID";
CM_ SG_ 970 ADC_VehParkMod "Parkinin mode";
CM_ SG_ 970 ADC_ParkProgs "the progress of parking";
CM_ SG_ 970 ADC_ParkRmngDst "the remain distance of parking";
CM_ SG_ 970 ADC_ObstclDst "obstacle distance";
CM_ SG_ 970 ADC_parkInterruptDuration "the park Interrupt Duration";
CM_ SG_ 970 ADC_EPS_SteeringAngle "the vehicle steer angle";
CM_ SG_ 970 ADC_FrontEndParkInAvl "ADC_FrontEndParkInAvl";
CM_ SG_ 970 ADC_RPAobscancelCfm "ADS RPA obs cancel confirmstatus";

BA_DEF_ BO_  "GenMsgCycleTime" INT 0 0;
BA_DEF_ BO_  "GenMsgCycleTimeFast" INT 0 0;
BA_DEF_ BO_  "GenMsgSendType" ENUM  "Periodic","Event","IfActive","POE","PA","FixedPeriodic","Event","EnabledPeriodic","NotUsed","NotUsed","EventPeriodic","NotUsed","NotUsed","NoMsgSendType";
BA_DEF_ BO_  "VFrameFormat" ENUM  "StandardCAN","ExtendedCAN","reserved","reserved","reserved","reserved","reserved","reserved","reserved","reserved","reserved","reserved","reserved","reserved","StandardCAN_FD","ExtendedCAN_FD";
BA_DEF_ BO_  "CANFD_BRS" ENUM  "0","1";
BA_DEF_ SG_  "EventCommandSignal" ENUM  "No","Yes";
BA_DEF_ SG_  "GatewayedSignals" ENUM  "No","Yes";
BA_DEF_ SG_  "GenSigInactiveValue" HEX 0 0;
BA_DEF_ SG_  "GenSigInvalidValue" HEX 0 0;
BA_DEF_ SG_  "GenSigSendType" ENUM  "Trigger","Passive","Cyclic","OnWrite","OnWriteWithRepetition","OnChange","OnChangeWithRepetition","IfActive","IfActiveWithRepetition","NoSigSendType";
BA_DEF_ SG_  "GenSigStartValue" HEX 0 0;
BA_DEF_ SG_  "GenSigTimeoutValue" HEX 0 0;
BA_DEF_ SG_  "Remark" STRING ;
BA_ "GenMsgCycleTime" BO_ 947 100;
BA_ "GenMsgCycleTimeFast" BO_ 947 0;
BA_ "GenMsgSendType" BO_ 947 0;
BA_ "VFrameFormat" BO_ 947 14;
BA_ "CANFD_BRS" BO_ 947 1;
BA_ "GenMsgCycleTime" BO_ 947 100;
BA_ "GenMsgCycleTimeFast" BO_ 947 0;
BA_ "GenMsgSendType" BO_ 947 0;
BA_ "VFrameFormat" BO_ 947 14;
BA_ "CANFD_BRS" BO_ 947 1;
BA_ "GenMsgCycleTime" BO_ 947 100;
BA_ "GenMsgCycleTimeFast" BO_ 947 0;
BA_ "GenMsgSendType" BO_ 947 0;
BA_ "VFrameFormat" BO_ 947 14;
BA_ "CANFD_BRS" BO_ 947 1;
BA_ "GenMsgCycleTime" BO_ 947 100;
BA_ "GenMsgCycleTimeFast" BO_ 947 0;
BA_ "GenMsgSendType" BO_ 947 0;
BA_ "VFrameFormat" BO_ 947 14;
BA_ "CANFD_BRS" BO_ 947 1;
BA_ "GenMsgCycleTime" BO_ 947 100;
BA_ "GenMsgCycleTimeFast" BO_ 947 0;
BA_ "GenMsgSendType" BO_ 947 0;
BA_ "VFrameFormat" BO_ 947 14;
BA_ "CANFD_BRS" BO_ 947 1;
BA_ "GenMsgCycleTime" BO_ 947 100;
BA_ "GenMsgCycleTimeFast" BO_ 947 0;
BA_ "GenMsgSendType" BO_ 947 0;
BA_ "VFrameFormat" BO_ 947 14;
BA_ "CANFD_BRS" BO_ 947 1;
BA_ "GenMsgCycleTime" BO_ 947 100;
BA_ "GenMsgCycleTimeFast" BO_ 947 0;
BA_ "GenMsgSendType" BO_ 947 0;
BA_ "VFrameFormat" BO_ 947 14;
BA_ "CANFD_BRS" BO_ 947 1;
BA_ "GenMsgCycleTime" BO_ 947 100;
BA_ "GenMsgCycleTimeFast" BO_ 947 0;
BA_ "GenMsgSendType" BO_ 947 0;
BA_ "VFrameFormat" BO_ 947 14;
BA_ "CANFD_BRS" BO_ 947 1;
BA_ "GenMsgCycleTime" BO_ 947 100;
BA_ "GenMsgCycleTimeFast" BO_ 947 0;
BA_ "GenMsgSendType" BO_ 947 0;
BA_ "VFrameFormat" BO_ 947 14;
BA_ "CANFD_BRS" BO_ 947 1;
BA_ "GenMsgCycleTime" BO_ 947 100;
BA_ "GenMsgCycleTimeFast" BO_ 947 0;
BA_ "GenMsgSendType" BO_ 947 0;
BA_ "VFrameFormat" BO_ 947 14;
BA_ "CANFD_BRS" BO_ 947 1;
BA_ "GenMsgCycleTime" BO_ 947 100;
BA_ "GenMsgCycleTimeFast" BO_ 947 0;
BA_ "GenMsgSendType" BO_ 947 0;
BA_ "VFrameFormat" BO_ 947 14;
BA_ "CANFD_BRS" BO_ 947 1;
BA_ "GenMsgCycleTime" BO_ 947 100;
BA_ "GenMsgCycleTimeFast" BO_ 947 0;
BA_ "GenMsgSendType" BO_ 947 0;
BA_ "VFrameFormat" BO_ 947 14;
BA_ "CANFD_BRS" BO_ 947 1;
BA_ "GenMsgCycleTime" BO_ 947 100;
BA_ "GenMsgCycleTimeFast" BO_ 947 0;
BA_ "GenMsgSendType" BO_ 947 0;
BA_ "VFrameFormat" BO_ 947 14;
BA_ "CANFD_BRS" BO_ 947 1;
BA_ "GenMsgCycleTime" BO_ 947 100;
BA_ "GenMsgCycleTimeFast" BO_ 947 0;
BA_ "GenMsgSendType" BO_ 947 0;
BA_ "VFrameFormat" BO_ 947 14;
BA_ "CANFD_BRS" BO_ 947 1;
BA_ "GenMsgCycleTime" BO_ 947 100;
BA_ "GenMsgCycleTimeFast" BO_ 947 0;
BA_ "GenMsgSendType" BO_ 947 0;
BA_ "VFrameFormat" BO_ 947 14;
BA_ "CANFD_BRS" BO_ 947 1;
BA_ "GenMsgCycleTime" BO_ 947 100;
BA_ "GenMsgCycleTimeFast" BO_ 947 0;
BA_ "GenMsgSendType" BO_ 947 0;
BA_ "VFrameFormat" BO_ 947 14;
BA_ "CANFD_BRS" BO_ 947 1;
BA_ "GenMsgCycleTime" BO_ 947 100;
BA_ "GenMsgCycleTimeFast" BO_ 947 0;
BA_ "GenMsgSendType" BO_ 947 0;
BA_ "VFrameFormat" BO_ 947 14;
BA_ "CANFD_BRS" BO_ 947 1;
BA_ "GenMsgCycleTime" BO_ 947 100;
BA_ "GenMsgCycleTimeFast" BO_ 947 0;
BA_ "GenMsgSendType" BO_ 947 0;
BA_ "VFrameFormat" BO_ 947 14;
BA_ "CANFD_BRS" BO_ 947 1;
BA_ "GenMsgCycleTime" BO_ 947 100;
BA_ "GenMsgCycleTimeFast" BO_ 947 0;
BA_ "GenMsgSendType" BO_ 947 0;
BA_ "VFrameFormat" BO_ 947 14;
BA_ "CANFD_BRS" BO_ 947 1;
BA_ "GenMsgCycleTime" BO_ 947 100;
BA_ "GenMsgCycleTimeFast" BO_ 947 0;
BA_ "GenMsgSendType" BO_ 947 0;
BA_ "VFrameFormat" BO_ 947 14;
BA_ "CANFD_BRS" BO_ 947 1;
BA_ "GenMsgCycleTime" BO_ 947 100;
BA_ "GenMsgCycleTimeFast" BO_ 947 0;
BA_ "GenMsgSendType" BO_ 947 0;
BA_ "VFrameFormat" BO_ 947 14;
BA_ "CANFD_BRS" BO_ 947 1;
BA_ "GenMsgCycleTime" BO_ 947 100;
BA_ "GenMsgCycleTimeFast" BO_ 947 0;
BA_ "GenMsgSendType" BO_ 947 0;
BA_ "VFrameFormat" BO_ 947 14;
BA_ "CANFD_BRS" BO_ 947 1;
BA_ "GenMsgCycleTime" BO_ 947 100;
BA_ "GenMsgCycleTimeFast" BO_ 947 0;
BA_ "GenMsgSendType" BO_ 947 0;
BA_ "VFrameFormat" BO_ 947 14;
BA_ "CANFD_BRS" BO_ 947 1;
BA_ "GenMsgCycleTime" BO_ 947 100;
BA_ "GenMsgCycleTimeFast" BO_ 947 0;
BA_ "GenMsgSendType" BO_ 947 0;
BA_ "VFrameFormat" BO_ 947 14;
BA_ "CANFD_BRS" BO_ 947 1;
BA_ "GenMsgCycleTime" BO_ 947 100;
BA_ "GenMsgCycleTimeFast" BO_ 947 0;
BA_ "GenMsgSendType" BO_ 947 0;
BA_ "VFrameFormat" BO_ 947 14;
BA_ "CANFD_BRS" BO_ 947 1;
BA_ "GenMsgCycleTime" BO_ 947 100;
BA_ "GenMsgCycleTimeFast" BO_ 947 0;
BA_ "GenMsgSendType" BO_ 947 0;
BA_ "VFrameFormat" BO_ 947 14;
BA_ "CANFD_BRS" BO_ 947 1;
BA_ "GenMsgCycleTime" BO_ 947 100;
BA_ "GenMsgCycleTimeFast" BO_ 947 0;
BA_ "GenMsgSendType" BO_ 947 0;
BA_ "VFrameFormat" BO_ 947 14;
BA_ "CANFD_BRS" BO_ 947 1;
BA_ "GenMsgCycleTime" BO_ 947 100;
BA_ "GenMsgCycleTimeFast" BO_ 947 0;
BA_ "GenMsgSendType" BO_ 947 0;
BA_ "VFrameFormat" BO_ 947 14;
BA_ "CANFD_BRS" BO_ 947 1;
BA_ "GenMsgCycleTime" BO_ 947 100;
BA_ "GenMsgCycleTimeFast" BO_ 947 0;
BA_ "GenMsgSendType" BO_ 947 0;
BA_ "VFrameFormat" BO_ 947 14;
BA_ "CANFD_BRS" BO_ 947 1;
BA_ "GenMsgCycleTime" BO_ 947 100;
BA_ "GenMsgCycleTimeFast" BO_ 947 0;
BA_ "GenMsgSendType" BO_ 947 0;
BA_ "VFrameFormat" BO_ 947 14;
BA_ "CANFD_BRS" BO_ 947 1;
BA_ "GenMsgCycleTime" BO_ 947 100;
BA_ "GenMsgCycleTimeFast" BO_ 947 0;
BA_ "GenMsgSendType" BO_ 947 0;
BA_ "VFrameFormat" BO_ 947 14;
BA_ "CANFD_BRS" BO_ 947 1;
BA_ "GenMsgCycleTime" BO_ 947 100;
BA_ "GenMsgCycleTimeFast" BO_ 947 0;
BA_ "GenMsgSendType" BO_ 947 0;
BA_ "VFrameFormat" BO_ 947 14;
BA_ "CANFD_BRS" BO_ 947 1;
BA_ "GenMsgCycleTime" BO_ 947 100;
BA_ "GenMsgCycleTimeFast" BO_ 947 0;
BA_ "GenMsgSendType" BO_ 947 0;
BA_ "VFrameFormat" BO_ 947 14;
BA_ "CANFD_BRS" BO_ 947 1;
BA_ "GenMsgCycleTime" BO_ 947 100;
BA_ "GenMsgCycleTimeFast" BO_ 947 0;
BA_ "GenMsgSendType" BO_ 947 0;
BA_ "VFrameFormat" BO_ 947 14;
BA_ "CANFD_BRS" BO_ 947 1;
BA_ "GenMsgCycleTime" BO_ 947 100;
BA_ "GenMsgCycleTimeFast" BO_ 947 0;
BA_ "GenMsgSendType" BO_ 947 0;
BA_ "VFrameFormat" BO_ 947 14;
BA_ "CANFD_BRS" BO_ 947 1;
BA_ "GenMsgCycleTime" BO_ 947 100;
BA_ "GenMsgCycleTimeFast" BO_ 947 0;
BA_ "GenMsgSendType" BO_ 947 0;
BA_ "VFrameFormat" BO_ 947 14;
BA_ "CANFD_BRS" BO_ 947 1;
BA_ "GenMsgCycleTime" BO_ 947 100;
BA_ "GenMsgCycleTimeFast" BO_ 947 0;
BA_ "GenMsgSendType" BO_ 947 0;
BA_ "VFrameFormat" BO_ 947 14;
BA_ "CANFD_BRS" BO_ 947 1;
BA_ "GenMsgCycleTime" BO_ 947 100;
BA_ "GenMsgCycleTimeFast" BO_ 947 0;
BA_ "GenMsgSendType" BO_ 947 0;
BA_ "VFrameFormat" BO_ 947 14;
BA_ "CANFD_BRS" BO_ 947 1;
BA_ "GenMsgCycleTime" BO_ 947 100;
BA_ "GenMsgCycleTimeFast" BO_ 947 0;
BA_ "GenMsgSendType" BO_ 947 0;
BA_ "VFrameFormat" BO_ 947 14;
BA_ "CANFD_BRS" BO_ 947 1;
BA_ "GenMsgCycleTime" BO_ 947 100;
BA_ "GenMsgCycleTimeFast" BO_ 947 0;
BA_ "GenMsgSendType" BO_ 947 0;
BA_ "VFrameFormat" BO_ 947 14;
BA_ "CANFD_BRS" BO_ 947 1;
BA_ "GenMsgCycleTime" BO_ 947 100;
BA_ "GenMsgCycleTimeFast" BO_ 947 0;
BA_ "GenMsgSendType" BO_ 947 0;
BA_ "VFrameFormat" BO_ 947 14;
BA_ "CANFD_BRS" BO_ 947 1;
BA_ "GenMsgCycleTime" BO_ 947 100;
BA_ "GenMsgCycleTimeFast" BO_ 947 0;
BA_ "GenMsgSendType" BO_ 947 0;
BA_ "VFrameFormat" BO_ 947 14;
BA_ "CANFD_BRS" BO_ 947 1;
BA_ "GenMsgCycleTime" BO_ 947 100;
BA_ "GenMsgCycleTimeFast" BO_ 947 0;
BA_ "GenMsgSendType" BO_ 947 0;
BA_ "VFrameFormat" BO_ 947 14;
BA_ "CANFD_BRS" BO_ 947 1;
BA_ "GenMsgCycleTime" BO_ 947 100;
BA_ "GenMsgCycleTimeFast" BO_ 947 0;
BA_ "GenMsgSendType" BO_ 947 0;
BA_ "VFrameFormat" BO_ 947 14;
BA_ "CANFD_BRS" BO_ 947 1;
BA_ "GenMsgCycleTime" BO_ 947 100;
BA_ "GenMsgCycleTimeFast" BO_ 947 0;
BA_ "GenMsgSendType" BO_ 947 0;
BA_ "VFrameFormat" BO_ 947 14;
BA_ "CANFD_BRS" BO_ 947 1;
BA_ "GenMsgCycleTime" BO_ 947 100;
BA_ "GenMsgCycleTimeFast" BO_ 947 0;
BA_ "GenMsgSendType" BO_ 947 0;
BA_ "VFrameFormat" BO_ 947 14;
BA_ "CANFD_BRS" BO_ 947 1;
BA_ "GenMsgCycleTime" BO_ 947 100;
BA_ "GenMsgCycleTimeFast" BO_ 947 0;
BA_ "GenMsgSendType" BO_ 947 0;
BA_ "VFrameFormat" BO_ 947 14;
BA_ "CANFD_BRS" BO_ 947 1;
BA_ "GenMsgCycleTime" BO_ 947 100;
BA_ "GenMsgCycleTimeFast" BO_ 947 0;
BA_ "GenMsgSendType" BO_ 947 0;
BA_ "VFrameFormat" BO_ 947 14;
BA_ "CANFD_BRS" BO_ 947 1;
BA_ "GenMsgCycleTime" BO_ 947 100;
BA_ "GenMsgCycleTimeFast" BO_ 947 0;
BA_ "GenMsgSendType" BO_ 947 0;
BA_ "VFrameFormat" BO_ 947 14;
BA_ "CANFD_BRS" BO_ 947 1;
BA_ "GenMsgCycleTime" BO_ 947 100;
BA_ "GenMsgCycleTimeFast" BO_ 947 0;
BA_ "GenMsgSendType" BO_ 947 0;
BA_ "VFrameFormat" BO_ 947 14;
BA_ "CANFD_BRS" BO_ 947 1;
BA_ "GenMsgCycleTime" BO_ 947 100;
BA_ "GenMsgCycleTimeFast" BO_ 947 0;
BA_ "GenMsgSendType" BO_ 947 0;
BA_ "VFrameFormat" BO_ 947 14;
BA_ "CANFD_BRS" BO_ 947 1;
BA_ "GenMsgCycleTime" BO_ 947 100;
BA_ "GenMsgCycleTimeFast" BO_ 947 0;
BA_ "GenMsgSendType" BO_ 947 0;
BA_ "VFrameFormat" BO_ 947 14;
BA_ "CANFD_BRS" BO_ 947 1;
BA_ "GenMsgCycleTime" BO_ 947 100;
BA_ "GenMsgCycleTimeFast" BO_ 947 0;
BA_ "GenMsgSendType" BO_ 947 0;
BA_ "VFrameFormat" BO_ 947 14;
BA_ "CANFD_BRS" BO_ 947 1;
BA_ "GenMsgCycleTime" BO_ 175 0;
BA_ "GenMsgCycleTimeFast" BO_ 175 0;
BA_ "GenMsgSendType" BO_ 175 1;
BA_ "VFrameFormat" BO_ 175 14;
BA_ "CANFD_BRS" BO_ 175 1;
BA_ "GenMsgCycleTime" BO_ 175 0;
BA_ "GenMsgCycleTimeFast" BO_ 175 0;
BA_ "GenMsgSendType" BO_ 175 1;
BA_ "VFrameFormat" BO_ 175 14;
BA_ "CANFD_BRS" BO_ 175 1;
BA_ "GenMsgCycleTime" BO_ 175 0;
BA_ "GenMsgCycleTimeFast" BO_ 175 0;
BA_ "GenMsgSendType" BO_ 175 1;
BA_ "VFrameFormat" BO_ 175 14;
BA_ "CANFD_BRS" BO_ 175 1;
BA_ "GenMsgCycleTime" BO_ 175 0;
BA_ "GenMsgCycleTimeFast" BO_ 175 0;
BA_ "GenMsgSendType" BO_ 175 1;
BA_ "VFrameFormat" BO_ 175 14;
BA_ "CANFD_BRS" BO_ 175 1;
BA_ "GenMsgCycleTime" BO_ 175 0;
BA_ "GenMsgCycleTimeFast" BO_ 175 0;
BA_ "GenMsgSendType" BO_ 175 1;
BA_ "VFrameFormat" BO_ 175 14;
BA_ "CANFD_BRS" BO_ 175 1;
BA_ "GenMsgCycleTime" BO_ 175 0;
BA_ "GenMsgCycleTimeFast" BO_ 175 0;
BA_ "GenMsgSendType" BO_ 175 1;
BA_ "VFrameFormat" BO_ 175 14;
BA_ "CANFD_BRS" BO_ 175 1;
BA_ "GenMsgCycleTime" BO_ 175 0;
BA_ "GenMsgCycleTimeFast" BO_ 175 0;
BA_ "GenMsgSendType" BO_ 175 1;
BA_ "VFrameFormat" BO_ 175 14;
BA_ "CANFD_BRS" BO_ 175 1;
BA_ "GenMsgCycleTime" BO_ 175 0;
BA_ "GenMsgCycleTimeFast" BO_ 175 0;
BA_ "GenMsgSendType" BO_ 175 1;
BA_ "VFrameFormat" BO_ 175 14;
BA_ "CANFD_BRS" BO_ 175 1;
BA_ "GenMsgCycleTime" BO_ 175 0;
BA_ "GenMsgCycleTimeFast" BO_ 175 0;
BA_ "GenMsgSendType" BO_ 175 1;
BA_ "VFrameFormat" BO_ 175 14;
BA_ "CANFD_BRS" BO_ 175 1;
BA_ "GenMsgCycleTime" BO_ 175 0;
BA_ "GenMsgCycleTimeFast" BO_ 175 0;
BA_ "GenMsgSendType" BO_ 175 1;
BA_ "VFrameFormat" BO_ 175 14;
BA_ "CANFD_BRS" BO_ 175 1;
BA_ "GenMsgCycleTime" BO_ 175 0;
BA_ "GenMsgCycleTimeFast" BO_ 175 0;
BA_ "GenMsgSendType" BO_ 175 1;
BA_ "VFrameFormat" BO_ 175 14;
BA_ "CANFD_BRS" BO_ 175 1;
BA_ "GenMsgCycleTime" BO_ 175 0;
BA_ "GenMsgCycleTimeFast" BO_ 175 0;
BA_ "GenMsgSendType" BO_ 175 1;
BA_ "VFrameFormat" BO_ 175 14;
BA_ "CANFD_BRS" BO_ 175 1;
BA_ "GenMsgCycleTime" BO_ 175 0;
BA_ "GenMsgCycleTimeFast" BO_ 175 0;
BA_ "GenMsgSendType" BO_ 175 1;
BA_ "VFrameFormat" BO_ 175 14;
BA_ "CANFD_BRS" BO_ 175 1;
BA_ "GenMsgCycleTime" BO_ 175 0;
BA_ "GenMsgCycleTimeFast" BO_ 175 0;
BA_ "GenMsgSendType" BO_ 175 1;
BA_ "VFrameFormat" BO_ 175 14;
BA_ "CANFD_BRS" BO_ 175 1;
BA_ "GenMsgCycleTime" BO_ 175 0;
BA_ "GenMsgCycleTimeFast" BO_ 175 0;
BA_ "GenMsgSendType" BO_ 175 1;
BA_ "VFrameFormat" BO_ 175 14;
BA_ "CANFD_BRS" BO_ 175 1;
BA_ "GenMsgCycleTime" BO_ 175 0;
BA_ "GenMsgCycleTimeFast" BO_ 175 0;
BA_ "GenMsgSendType" BO_ 175 1;
BA_ "VFrameFormat" BO_ 175 14;
BA_ "CANFD_BRS" BO_ 175 1;
BA_ "GenMsgCycleTime" BO_ 175 0;
BA_ "GenMsgCycleTimeFast" BO_ 175 0;
BA_ "GenMsgSendType" BO_ 175 1;
BA_ "VFrameFormat" BO_ 175 14;
BA_ "CANFD_BRS" BO_ 175 1;
BA_ "GenMsgCycleTime" BO_ 175 0;
BA_ "GenMsgCycleTimeFast" BO_ 175 0;
BA_ "GenMsgSendType" BO_ 175 1;
BA_ "VFrameFormat" BO_ 175 14;
BA_ "CANFD_BRS" BO_ 175 1;
BA_ "GenMsgCycleTime" BO_ 175 0;
BA_ "GenMsgCycleTimeFast" BO_ 175 0;
BA_ "GenMsgSendType" BO_ 175 1;
BA_ "VFrameFormat" BO_ 175 14;
BA_ "CANFD_BRS" BO_ 175 1;
BA_ "GenMsgCycleTime" BO_ 135 0;
BA_ "GenMsgCycleTimeFast" BO_ 135 0;
BA_ "GenMsgSendType" BO_ 135 1;
BA_ "VFrameFormat" BO_ 135 14;
BA_ "CANFD_BRS" BO_ 135 1;
BA_ "GenMsgCycleTime" BO_ 1234 0;
BA_ "GenMsgCycleTimeFast" BO_ 1234 0;
BA_ "GenMsgSendType" BO_ 1234 1;
BA_ "VFrameFormat" BO_ 1234 14;
BA_ "CANFD_BRS" BO_ 1234 1;
BA_ "GenMsgCycleTime" BO_ 1235 0;
BA_ "GenMsgCycleTimeFast" BO_ 1235 0;
BA_ "GenMsgSendType" BO_ 1235 1;
BA_ "VFrameFormat" BO_ 1235 14;
BA_ "CANFD_BRS" BO_ 1235 1;
BA_ "GenMsgCycleTime" BO_ 1785 0;
BA_ "GenMsgCycleTimeFast" BO_ 1785 0;
BA_ "GenMsgSendType" BO_ 1785 1;
BA_ "VFrameFormat" BO_ 1785 14;
BA_ "CANFD_BRS" BO_ 1785 1;
BA_ "GenMsgCycleTime" BO_ 127 0;
BA_ "GenMsgCycleTimeFast" BO_ 127 0;
BA_ "GenMsgSendType" BO_ 127 1;
BA_ "VFrameFormat" BO_ 127 14;
BA_ "CANFD_BRS" BO_ 127 1;
BA_ "GenMsgCycleTime" BO_ 1934 0;
BA_ "GenMsgCycleTimeFast" BO_ 1934 0;
BA_ "GenMsgSendType" BO_ 1934 1;
BA_ "VFrameFormat" BO_ 1934 14;
BA_ "CANFD_BRS" BO_ 1934 1;
BA_ "GenMsgCycleTime" BO_ 1294 200;
BA_ "GenMsgCycleTimeFast" BO_ 1294 0;
BA_ "GenMsgSendType" BO_ 1294 0;
BA_ "VFrameFormat" BO_ 1294 0;
BA_ "CANFD_BRS" BO_ 1294 1;
BA_ "GenMsgCycleTime" BO_ 1294 200;
BA_ "GenMsgCycleTimeFast" BO_ 1294 0;
BA_ "GenMsgSendType" BO_ 1294 0;
BA_ "VFrameFormat" BO_ 1294 0;
BA_ "CANFD_BRS" BO_ 1294 1;
BA_ "GenMsgCycleTime" BO_ 1294 200;
BA_ "GenMsgCycleTimeFast" BO_ 1294 0;
BA_ "GenMsgSendType" BO_ 1294 0;
BA_ "VFrameFormat" BO_ 1294 0;
BA_ "CANFD_BRS" BO_ 1294 1;
BA_ "GenMsgCycleTime" BO_ 1294 200;
BA_ "GenMsgCycleTimeFast" BO_ 1294 0;
BA_ "GenMsgSendType" BO_ 1294 0;
BA_ "VFrameFormat" BO_ 1294 0;
BA_ "CANFD_BRS" BO_ 1294 1;
BA_ "GenMsgCycleTime" BO_ 1294 200;
BA_ "GenMsgCycleTimeFast" BO_ 1294 0;
BA_ "GenMsgSendType" BO_ 1294 0;
BA_ "VFrameFormat" BO_ 1294 0;
BA_ "CANFD_BRS" BO_ 1294 1;
BA_ "GenMsgCycleTime" BO_ 1294 200;
BA_ "GenMsgCycleTimeFast" BO_ 1294 0;
BA_ "GenMsgSendType" BO_ 1294 0;
BA_ "VFrameFormat" BO_ 1294 0;
BA_ "CANFD_BRS" BO_ 1294 1;
BA_ "GenMsgCycleTime" BO_ 1188 0;
BA_ "GenMsgCycleTimeFast" BO_ 1188 0;
BA_ "GenMsgSendType" BO_ 1188 1;
BA_ "VFrameFormat" BO_ 1188 14;
BA_ "CANFD_BRS" BO_ 1188 1;
BA_ "GenMsgCycleTime" BO_ 969 100;
BA_ "GenMsgCycleTimeFast" BO_ 969 0;
BA_ "GenMsgSendType" BO_ 969 0;
BA_ "VFrameFormat" BO_ 969 14;
BA_ "CANFD_BRS" BO_ 969 1;
BA_ "GenMsgCycleTime" BO_ 969 100;
BA_ "GenMsgCycleTimeFast" BO_ 969 0;
BA_ "GenMsgSendType" BO_ 969 0;
BA_ "VFrameFormat" BO_ 969 14;
BA_ "CANFD_BRS" BO_ 969 1;
BA_ "GenMsgCycleTime" BO_ 969 100;
BA_ "GenMsgCycleTimeFast" BO_ 969 0;
BA_ "GenMsgSendType" BO_ 969 0;
BA_ "VFrameFormat" BO_ 969 14;
BA_ "CANFD_BRS" BO_ 969 1;
BA_ "GenMsgCycleTime" BO_ 969 100;
BA_ "GenMsgCycleTimeFast" BO_ 969 0;
BA_ "GenMsgSendType" BO_ 969 0;
BA_ "VFrameFormat" BO_ 969 14;
BA_ "CANFD_BRS" BO_ 969 1;
BA_ "GenMsgCycleTime" BO_ 969 100;
BA_ "GenMsgCycleTimeFast" BO_ 969 0;
BA_ "GenMsgSendType" BO_ 969 0;
BA_ "VFrameFormat" BO_ 969 14;
BA_ "CANFD_BRS" BO_ 969 1;
BA_ "GenMsgCycleTime" BO_ 969 100;
BA_ "GenMsgCycleTimeFast" BO_ 969 0;
BA_ "GenMsgSendType" BO_ 969 0;
BA_ "VFrameFormat" BO_ 969 14;
BA_ "CANFD_BRS" BO_ 969 1;
BA_ "GenMsgCycleTime" BO_ 969 100;
BA_ "GenMsgCycleTimeFast" BO_ 969 0;
BA_ "GenMsgSendType" BO_ 969 0;
BA_ "VFrameFormat" BO_ 969 14;
BA_ "CANFD_BRS" BO_ 969 1;
BA_ "GenMsgCycleTime" BO_ 969 100;
BA_ "GenMsgCycleTimeFast" BO_ 969 0;
BA_ "GenMsgSendType" BO_ 969 0;
BA_ "VFrameFormat" BO_ 969 14;
BA_ "CANFD_BRS" BO_ 969 1;
BA_ "GenMsgCycleTime" BO_ 969 100;
BA_ "GenMsgCycleTimeFast" BO_ 969 0;
BA_ "GenMsgSendType" BO_ 969 0;
BA_ "VFrameFormat" BO_ 969 14;
BA_ "CANFD_BRS" BO_ 969 1;
BA_ "GenMsgCycleTime" BO_ 969 100;
BA_ "GenMsgCycleTimeFast" BO_ 969 0;
BA_ "GenMsgSendType" BO_ 969 0;
BA_ "VFrameFormat" BO_ 969 14;
BA_ "CANFD_BRS" BO_ 969 1;
BA_ "GenMsgCycleTime" BO_ 969 100;
BA_ "GenMsgCycleTimeFast" BO_ 969 0;
BA_ "GenMsgSendType" BO_ 969 0;
BA_ "VFrameFormat" BO_ 969 14;
BA_ "CANFD_BRS" BO_ 969 1;
BA_ "GenMsgCycleTime" BO_ 969 100;
BA_ "GenMsgCycleTimeFast" BO_ 969 0;
BA_ "GenMsgSendType" BO_ 969 0;
BA_ "VFrameFormat" BO_ 969 14;
BA_ "CANFD_BRS" BO_ 969 1;
BA_ "GenMsgCycleTime" BO_ 969 100;
BA_ "GenMsgCycleTimeFast" BO_ 969 0;
BA_ "GenMsgSendType" BO_ 969 0;
BA_ "VFrameFormat" BO_ 969 14;
BA_ "CANFD_BRS" BO_ 969 1;
BA_ "GenMsgCycleTime" BO_ 969 100;
BA_ "GenMsgCycleTimeFast" BO_ 969 0;
BA_ "GenMsgSendType" BO_ 969 0;
BA_ "VFrameFormat" BO_ 969 14;
BA_ "CANFD_BRS" BO_ 969 1;
BA_ "GenMsgCycleTime" BO_ 969 100;
BA_ "GenMsgCycleTimeFast" BO_ 969 0;
BA_ "GenMsgSendType" BO_ 969 0;
BA_ "VFrameFormat" BO_ 969 14;
BA_ "CANFD_BRS" BO_ 969 1;
BA_ "GenMsgCycleTime" BO_ 969 100;
BA_ "GenMsgCycleTimeFast" BO_ 969 0;
BA_ "GenMsgSendType" BO_ 969 0;
BA_ "VFrameFormat" BO_ 969 14;
BA_ "CANFD_BRS" BO_ 969 1;
BA_ "GenMsgCycleTime" BO_ 969 100;
BA_ "GenMsgCycleTimeFast" BO_ 969 0;
BA_ "GenMsgSendType" BO_ 969 0;
BA_ "VFrameFormat" BO_ 969 14;
BA_ "CANFD_BRS" BO_ 969 1;
BA_ "GenMsgCycleTime" BO_ 969 100;
BA_ "GenMsgCycleTimeFast" BO_ 969 0;
BA_ "GenMsgSendType" BO_ 969 0;
BA_ "VFrameFormat" BO_ 969 14;
BA_ "CANFD_BRS" BO_ 969 1;
BA_ "GenMsgCycleTime" BO_ 969 100;
BA_ "GenMsgCycleTimeFast" BO_ 969 0;
BA_ "GenMsgSendType" BO_ 969 0;
BA_ "VFrameFormat" BO_ 969 14;
BA_ "CANFD_BRS" BO_ 969 1;
BA_ "GenMsgCycleTime" BO_ 969 100;
BA_ "GenMsgCycleTimeFast" BO_ 969 0;
BA_ "GenMsgSendType" BO_ 969 0;
BA_ "VFrameFormat" BO_ 969 14;
BA_ "CANFD_BRS" BO_ 969 1;
BA_ "GenMsgCycleTime" BO_ 969 100;
BA_ "GenMsgCycleTimeFast" BO_ 969 0;
BA_ "GenMsgSendType" BO_ 969 0;
BA_ "VFrameFormat" BO_ 969 14;
BA_ "CANFD_BRS" BO_ 969 1;
BA_ "GenMsgCycleTime" BO_ 969 100;
BA_ "GenMsgCycleTimeFast" BO_ 969 0;
BA_ "GenMsgSendType" BO_ 969 0;
BA_ "VFrameFormat" BO_ 969 14;
BA_ "CANFD_BRS" BO_ 969 1;
BA_ "GenMsgCycleTime" BO_ 969 100;
BA_ "GenMsgCycleTimeFast" BO_ 969 0;
BA_ "GenMsgSendType" BO_ 969 0;
BA_ "VFrameFormat" BO_ 969 14;
BA_ "CANFD_BRS" BO_ 969 1;
BA_ "GenMsgCycleTime" BO_ 969 100;
BA_ "GenMsgCycleTimeFast" BO_ 969 0;
BA_ "GenMsgSendType" BO_ 969 0;
BA_ "VFrameFormat" BO_ 969 14;
BA_ "CANFD_BRS" BO_ 969 1;
BA_ "GenMsgCycleTime" BO_ 969 100;
BA_ "GenMsgCycleTimeFast" BO_ 969 0;
BA_ "GenMsgSendType" BO_ 969 0;
BA_ "VFrameFormat" BO_ 969 14;
BA_ "CANFD_BRS" BO_ 969 1;
BA_ "GenMsgCycleTime" BO_ 969 100;
BA_ "GenMsgCycleTimeFast" BO_ 969 0;
BA_ "GenMsgSendType" BO_ 969 0;
BA_ "VFrameFormat" BO_ 969 14;
BA_ "CANFD_BRS" BO_ 969 1;
BA_ "GenMsgCycleTime" BO_ 969 100;
BA_ "GenMsgCycleTimeFast" BO_ 969 0;
BA_ "GenMsgSendType" BO_ 969 0;
BA_ "VFrameFormat" BO_ 969 14;
BA_ "CANFD_BRS" BO_ 969 1;
BA_ "GenMsgCycleTime" BO_ 969 100;
BA_ "GenMsgCycleTimeFast" BO_ 969 0;
BA_ "GenMsgSendType" BO_ 969 0;
BA_ "VFrameFormat" BO_ 969 14;
BA_ "CANFD_BRS" BO_ 969 1;
BA_ "GenMsgCycleTime" BO_ 969 100;
BA_ "GenMsgCycleTimeFast" BO_ 969 0;
BA_ "GenMsgSendType" BO_ 969 0;
BA_ "VFrameFormat" BO_ 969 14;
BA_ "CANFD_BRS" BO_ 969 1;
BA_ "GenMsgCycleTime" BO_ 969 100;
BA_ "GenMsgCycleTimeFast" BO_ 969 0;
BA_ "GenMsgSendType" BO_ 969 0;
BA_ "VFrameFormat" BO_ 969 14;
BA_ "CANFD_BRS" BO_ 969 1;
BA_ "GenMsgCycleTime" BO_ 969 100;
BA_ "GenMsgCycleTimeFast" BO_ 969 0;
BA_ "GenMsgSendType" BO_ 969 0;
BA_ "VFrameFormat" BO_ 969 14;
BA_ "CANFD_BRS" BO_ 969 1;
BA_ "GenMsgCycleTime" BO_ 969 100;
BA_ "GenMsgCycleTimeFast" BO_ 969 0;
BA_ "GenMsgSendType" BO_ 969 0;
BA_ "VFrameFormat" BO_ 969 14;
BA_ "CANFD_BRS" BO_ 969 1;
BA_ "GenMsgCycleTime" BO_ 969 100;
BA_ "GenMsgCycleTimeFast" BO_ 969 0;
BA_ "GenMsgSendType" BO_ 969 0;
BA_ "VFrameFormat" BO_ 969 14;
BA_ "CANFD_BRS" BO_ 969 1;
BA_ "GenMsgCycleTime" BO_ 969 100;
BA_ "GenMsgCycleTimeFast" BO_ 969 0;
BA_ "GenMsgSendType" BO_ 969 0;
BA_ "VFrameFormat" BO_ 969 14;
BA_ "CANFD_BRS" BO_ 969 1;
BA_ "GenMsgCycleTime" BO_ 969 100;
BA_ "GenMsgCycleTimeFast" BO_ 969 0;
BA_ "GenMsgSendType" BO_ 969 0;
BA_ "VFrameFormat" BO_ 969 14;
BA_ "CANFD_BRS" BO_ 969 1;
BA_ "GenMsgCycleTime" BO_ 969 100;
BA_ "GenMsgCycleTimeFast" BO_ 969 0;
BA_ "GenMsgSendType" BO_ 969 0;
BA_ "VFrameFormat" BO_ 969 14;
BA_ "CANFD_BRS" BO_ 969 1;
BA_ "GenMsgCycleTime" BO_ 969 100;
BA_ "GenMsgCycleTimeFast" BO_ 969 0;
BA_ "GenMsgSendType" BO_ 969 0;
BA_ "VFrameFormat" BO_ 969 14;
BA_ "CANFD_BRS" BO_ 969 1;
BA_ "GenMsgCycleTime" BO_ 969 100;
BA_ "GenMsgCycleTimeFast" BO_ 969 0;
BA_ "GenMsgSendType" BO_ 969 0;
BA_ "VFrameFormat" BO_ 969 14;
BA_ "CANFD_BRS" BO_ 969 1;
BA_ "GenMsgCycleTime" BO_ 969 100;
BA_ "GenMsgCycleTimeFast" BO_ 969 0;
BA_ "GenMsgSendType" BO_ 969 0;
BA_ "VFrameFormat" BO_ 969 14;
BA_ "CANFD_BRS" BO_ 969 1;
BA_ "GenMsgCycleTime" BO_ 969 100;
BA_ "GenMsgCycleTimeFast" BO_ 969 0;
BA_ "GenMsgSendType" BO_ 969 0;
BA_ "VFrameFormat" BO_ 969 14;
BA_ "CANFD_BRS" BO_ 969 1;
BA_ "GenMsgCycleTime" BO_ 969 100;
BA_ "GenMsgCycleTimeFast" BO_ 969 0;
BA_ "GenMsgSendType" BO_ 969 0;
BA_ "VFrameFormat" BO_ 969 14;
BA_ "CANFD_BRS" BO_ 969 1;
BA_ "GenMsgCycleTime" BO_ 969 100;
BA_ "GenMsgCycleTimeFast" BO_ 969 0;
BA_ "GenMsgSendType" BO_ 969 0;
BA_ "VFrameFormat" BO_ 969 14;
BA_ "CANFD_BRS" BO_ 969 1;
BA_ "GenMsgCycleTime" BO_ 969 100;
BA_ "GenMsgCycleTimeFast" BO_ 969 0;
BA_ "GenMsgSendType" BO_ 969 0;
BA_ "VFrameFormat" BO_ 969 14;
BA_ "CANFD_BRS" BO_ 969 1;
BA_ "GenMsgCycleTime" BO_ 969 100;
BA_ "GenMsgCycleTimeFast" BO_ 969 0;
BA_ "GenMsgSendType" BO_ 969 0;
BA_ "VFrameFormat" BO_ 969 14;
BA_ "CANFD_BRS" BO_ 969 1;
BA_ "GenMsgCycleTime" BO_ 969 100;
BA_ "GenMsgCycleTimeFast" BO_ 969 0;
BA_ "GenMsgSendType" BO_ 969 0;
BA_ "VFrameFormat" BO_ 969 14;
BA_ "CANFD_BRS" BO_ 969 1;
BA_ "GenMsgCycleTime" BO_ 969 100;
BA_ "GenMsgCycleTimeFast" BO_ 969 0;
BA_ "GenMsgSendType" BO_ 969 0;
BA_ "VFrameFormat" BO_ 969 14;
BA_ "CANFD_BRS" BO_ 969 1;
BA_ "GenMsgCycleTime" BO_ 969 100;
BA_ "GenMsgCycleTimeFast" BO_ 969 0;
BA_ "GenMsgSendType" BO_ 969 0;
BA_ "VFrameFormat" BO_ 969 14;
BA_ "CANFD_BRS" BO_ 969 1;
BA_ "GenMsgCycleTime" BO_ 969 100;
BA_ "GenMsgCycleTimeFast" BO_ 969 0;
BA_ "GenMsgSendType" BO_ 969 0;
BA_ "VFrameFormat" BO_ 969 14;
BA_ "CANFD_BRS" BO_ 969 1;
BA_ "GenMsgCycleTime" BO_ 969 100;
BA_ "GenMsgCycleTimeFast" BO_ 969 0;
BA_ "GenMsgSendType" BO_ 969 0;
BA_ "VFrameFormat" BO_ 969 14;
BA_ "CANFD_BRS" BO_ 969 1;
BA_ "GenMsgCycleTime" BO_ 969 100;
BA_ "GenMsgCycleTimeFast" BO_ 969 0;
BA_ "GenMsgSendType" BO_ 969 0;
BA_ "VFrameFormat" BO_ 969 14;
BA_ "CANFD_BRS" BO_ 969 1;
BA_ "GenMsgCycleTime" BO_ 969 100;
BA_ "GenMsgCycleTimeFast" BO_ 969 0;
BA_ "GenMsgSendType" BO_ 969 0;
BA_ "VFrameFormat" BO_ 969 14;
BA_ "CANFD_BRS" BO_ 969 1;
BA_ "GenMsgCycleTime" BO_ 969 100;
BA_ "GenMsgCycleTimeFast" BO_ 969 0;
BA_ "GenMsgSendType" BO_ 969 0;
BA_ "VFrameFormat" BO_ 969 14;
BA_ "CANFD_BRS" BO_ 969 1;
BA_ "GenMsgCycleTime" BO_ 969 100;
BA_ "GenMsgCycleTimeFast" BO_ 969 0;
BA_ "GenMsgSendType" BO_ 969 0;
BA_ "VFrameFormat" BO_ 969 14;
BA_ "CANFD_BRS" BO_ 969 1;
BA_ "GenMsgCycleTime" BO_ 969 100;
BA_ "GenMsgCycleTimeFast" BO_ 969 0;
BA_ "GenMsgSendType" BO_ 969 0;
BA_ "VFrameFormat" BO_ 969 14;
BA_ "CANFD_BRS" BO_ 969 1;
BA_ "GenMsgCycleTime" BO_ 969 100;
BA_ "GenMsgCycleTimeFast" BO_ 969 0;
BA_ "GenMsgSendType" BO_ 969 0;
BA_ "VFrameFormat" BO_ 969 14;
BA_ "CANFD_BRS" BO_ 969 1;
BA_ "GenMsgCycleTime" BO_ 969 100;
BA_ "GenMsgCycleTimeFast" BO_ 969 0;
BA_ "GenMsgSendType" BO_ 969 0;
BA_ "VFrameFormat" BO_ 969 14;
BA_ "CANFD_BRS" BO_ 969 1;
BA_ "GenMsgCycleTime" BO_ 969 100;
BA_ "GenMsgCycleTimeFast" BO_ 969 0;
BA_ "GenMsgSendType" BO_ 969 0;
BA_ "VFrameFormat" BO_ 969 14;
BA_ "CANFD_BRS" BO_ 969 1;
BA_ "GenMsgCycleTime" BO_ 969 100;
BA_ "GenMsgCycleTimeFast" BO_ 969 0;
BA_ "GenMsgSendType" BO_ 969 0;
BA_ "VFrameFormat" BO_ 969 14;
BA_ "CANFD_BRS" BO_ 969 1;
BA_ "GenMsgCycleTime" BO_ 969 100;
BA_ "GenMsgCycleTimeFast" BO_ 969 0;
BA_ "GenMsgSendType" BO_ 969 0;
BA_ "VFrameFormat" BO_ 969 14;
BA_ "CANFD_BRS" BO_ 969 1;
BA_ "GenMsgCycleTime" BO_ 969 100;
BA_ "GenMsgCycleTimeFast" BO_ 969 0;
BA_ "GenMsgSendType" BO_ 969 0;
BA_ "VFrameFormat" BO_ 969 14;
BA_ "CANFD_BRS" BO_ 969 1;
BA_ "GenMsgCycleTime" BO_ 969 100;
BA_ "GenMsgCycleTimeFast" BO_ 969 0;
BA_ "GenMsgSendType" BO_ 969 0;
BA_ "VFrameFormat" BO_ 969 14;
BA_ "CANFD_BRS" BO_ 969 1;
BA_ "GenMsgCycleTime" BO_ 969 100;
BA_ "GenMsgCycleTimeFast" BO_ 969 0;
BA_ "GenMsgSendType" BO_ 969 0;
BA_ "VFrameFormat" BO_ 969 14;
BA_ "CANFD_BRS" BO_ 969 1;
BA_ "GenMsgCycleTime" BO_ 969 100;
BA_ "GenMsgCycleTimeFast" BO_ 969 0;
BA_ "GenMsgSendType" BO_ 969 0;
BA_ "VFrameFormat" BO_ 969 14;
BA_ "CANFD_BRS" BO_ 969 1;
BA_ "GenMsgCycleTime" BO_ 969 100;
BA_ "GenMsgCycleTimeFast" BO_ 969 0;
BA_ "GenMsgSendType" BO_ 969 0;
BA_ "VFrameFormat" BO_ 969 14;
BA_ "CANFD_BRS" BO_ 969 1;
BA_ "GenMsgCycleTime" BO_ 969 100;
BA_ "GenMsgCycleTimeFast" BO_ 969 0;
BA_ "GenMsgSendType" BO_ 969 0;
BA_ "VFrameFormat" BO_ 969 14;
BA_ "CANFD_BRS" BO_ 969 1;
BA_ "GenMsgCycleTime" BO_ 969 100;
BA_ "GenMsgCycleTimeFast" BO_ 969 0;
BA_ "GenMsgSendType" BO_ 969 0;
BA_ "VFrameFormat" BO_ 969 14;
BA_ "CANFD_BRS" BO_ 969 1;
BA_ "GenMsgCycleTime" BO_ 969 100;
BA_ "GenMsgCycleTimeFast" BO_ 969 0;
BA_ "GenMsgSendType" BO_ 969 0;
BA_ "VFrameFormat" BO_ 969 14;
BA_ "CANFD_BRS" BO_ 969 1;
BA_ "GenMsgCycleTime" BO_ 969 100;
BA_ "GenMsgCycleTimeFast" BO_ 969 0;
BA_ "GenMsgSendType" BO_ 969 0;
BA_ "VFrameFormat" BO_ 969 14;
BA_ "CANFD_BRS" BO_ 969 1;
BA_ "GenMsgCycleTime" BO_ 969 100;
BA_ "GenMsgCycleTimeFast" BO_ 969 0;
BA_ "GenMsgSendType" BO_ 969 0;
BA_ "VFrameFormat" BO_ 969 14;
BA_ "CANFD_BRS" BO_ 969 1;
BA_ "GenMsgCycleTime" BO_ 969 100;
BA_ "GenMsgCycleTimeFast" BO_ 969 0;
BA_ "GenMsgSendType" BO_ 969 0;
BA_ "VFrameFormat" BO_ 969 14;
BA_ "CANFD_BRS" BO_ 969 1;
BA_ "GenMsgCycleTime" BO_ 969 100;
BA_ "GenMsgCycleTimeFast" BO_ 969 0;
BA_ "GenMsgSendType" BO_ 969 0;
BA_ "VFrameFormat" BO_ 969 14;
BA_ "CANFD_BRS" BO_ 969 1;
BA_ "GenMsgCycleTime" BO_ 969 100;
BA_ "GenMsgCycleTimeFast" BO_ 969 0;
BA_ "GenMsgSendType" BO_ 969 0;
BA_ "VFrameFormat" BO_ 969 14;
BA_ "CANFD_BRS" BO_ 969 1;
BA_ "GenMsgCycleTime" BO_ 969 100;
BA_ "GenMsgCycleTimeFast" BO_ 969 0;
BA_ "GenMsgSendType" BO_ 969 0;
BA_ "VFrameFormat" BO_ 969 14;
BA_ "CANFD_BRS" BO_ 969 1;
BA_ "GenMsgCycleTime" BO_ 969 100;
BA_ "GenMsgCycleTimeFast" BO_ 969 0;
BA_ "GenMsgSendType" BO_ 969 0;
BA_ "VFrameFormat" BO_ 969 14;
BA_ "CANFD_BRS" BO_ 969 1;
BA_ "GenMsgCycleTime" BO_ 969 100;
BA_ "GenMsgCycleTimeFast" BO_ 969 0;
BA_ "GenMsgSendType" BO_ 969 0;
BA_ "VFrameFormat" BO_ 969 14;
BA_ "CANFD_BRS" BO_ 969 1;
BA_ "GenMsgCycleTime" BO_ 969 100;
BA_ "GenMsgCycleTimeFast" BO_ 969 0;
BA_ "GenMsgSendType" BO_ 969 0;
BA_ "VFrameFormat" BO_ 969 14;
BA_ "CANFD_BRS" BO_ 969 1;
BA_ "GenMsgCycleTime" BO_ 969 100;
BA_ "GenMsgCycleTimeFast" BO_ 969 0;
BA_ "GenMsgSendType" BO_ 969 0;
BA_ "VFrameFormat" BO_ 969 14;
BA_ "CANFD_BRS" BO_ 969 1;
BA_ "GenMsgCycleTime" BO_ 969 100;
BA_ "GenMsgCycleTimeFast" BO_ 969 0;
BA_ "GenMsgSendType" BO_ 969 0;
BA_ "VFrameFormat" BO_ 969 14;
BA_ "CANFD_BRS" BO_ 969 1;
BA_ "GenMsgCycleTime" BO_ 969 100;
BA_ "GenMsgCycleTimeFast" BO_ 969 0;
BA_ "GenMsgSendType" BO_ 969 0;
BA_ "VFrameFormat" BO_ 969 14;
BA_ "CANFD_BRS" BO_ 969 1;
BA_ "GenMsgCycleTime" BO_ 969 100;
BA_ "GenMsgCycleTimeFast" BO_ 969 0;
BA_ "GenMsgSendType" BO_ 969 0;
BA_ "VFrameFormat" BO_ 969 14;
BA_ "CANFD_BRS" BO_ 969 1;
BA_ "GenMsgCycleTime" BO_ 969 100;
BA_ "GenMsgCycleTimeFast" BO_ 969 0;
BA_ "GenMsgSendType" BO_ 969 0;
BA_ "VFrameFormat" BO_ 969 14;
BA_ "CANFD_BRS" BO_ 969 1;
BA_ "GenMsgCycleTime" BO_ 969 100;
BA_ "GenMsgCycleTimeFast" BO_ 969 0;
BA_ "GenMsgSendType" BO_ 969 0;
BA_ "VFrameFormat" BO_ 969 14;
BA_ "CANFD_BRS" BO_ 969 1;
BA_ "GenMsgCycleTime" BO_ 969 100;
BA_ "GenMsgCycleTimeFast" BO_ 969 0;
BA_ "GenMsgSendType" BO_ 969 0;
BA_ "VFrameFormat" BO_ 969 14;
BA_ "CANFD_BRS" BO_ 969 1;
BA_ "GenMsgCycleTime" BO_ 969 100;
BA_ "GenMsgCycleTimeFast" BO_ 969 0;
BA_ "GenMsgSendType" BO_ 969 0;
BA_ "VFrameFormat" BO_ 969 14;
BA_ "CANFD_BRS" BO_ 969 1;
BA_ "GenMsgCycleTime" BO_ 969 100;
BA_ "GenMsgCycleTimeFast" BO_ 969 0;
BA_ "GenMsgSendType" BO_ 969 0;
BA_ "VFrameFormat" BO_ 969 14;
BA_ "CANFD_BRS" BO_ 969 1;
BA_ "GenMsgCycleTime" BO_ 969 100;
BA_ "GenMsgCycleTimeFast" BO_ 969 0;
BA_ "GenMsgSendType" BO_ 969 0;
BA_ "VFrameFormat" BO_ 969 14;
BA_ "CANFD_BRS" BO_ 969 1;
BA_ "GenMsgCycleTime" BO_ 969 100;
BA_ "GenMsgCycleTimeFast" BO_ 969 0;
BA_ "GenMsgSendType" BO_ 969 0;
BA_ "VFrameFormat" BO_ 969 14;
BA_ "CANFD_BRS" BO_ 969 1;
BA_ "GenMsgCycleTime" BO_ 969 100;
BA_ "GenMsgCycleTimeFast" BO_ 969 0;
BA_ "GenMsgSendType" BO_ 969 0;
BA_ "VFrameFormat" BO_ 969 14;
BA_ "CANFD_BRS" BO_ 969 1;
BA_ "GenMsgCycleTime" BO_ 969 100;
BA_ "GenMsgCycleTimeFast" BO_ 969 0;
BA_ "GenMsgSendType" BO_ 969 0;
BA_ "VFrameFormat" BO_ 969 14;
BA_ "CANFD_BRS" BO_ 969 1;
BA_ "GenMsgCycleTime" BO_ 969 100;
BA_ "GenMsgCycleTimeFast" BO_ 969 0;
BA_ "GenMsgSendType" BO_ 969 0;
BA_ "VFrameFormat" BO_ 969 14;
BA_ "CANFD_BRS" BO_ 969 1;
BA_ "GenMsgCycleTime" BO_ 969 100;
BA_ "GenMsgCycleTimeFast" BO_ 969 0;
BA_ "GenMsgSendType" BO_ 969 0;
BA_ "VFrameFormat" BO_ 969 14;
BA_ "CANFD_BRS" BO_ 969 1;
BA_ "GenMsgCycleTime" BO_ 969 100;
BA_ "GenMsgCycleTimeFast" BO_ 969 0;
BA_ "GenMsgSendType" BO_ 969 0;
BA_ "VFrameFormat" BO_ 969 14;
BA_ "CANFD_BRS" BO_ 969 1;
BA_ "GenMsgCycleTime" BO_ 969 100;
BA_ "GenMsgCycleTimeFast" BO_ 969 0;
BA_ "GenMsgSendType" BO_ 969 0;
BA_ "VFrameFormat" BO_ 969 14;
BA_ "CANFD_BRS" BO_ 969 1;
BA_ "GenMsgCycleTime" BO_ 969 100;
BA_ "GenMsgCycleTimeFast" BO_ 969 0;
BA_ "GenMsgSendType" BO_ 969 0;
BA_ "VFrameFormat" BO_ 969 14;
BA_ "CANFD_BRS" BO_ 969 1;
BA_ "GenMsgCycleTime" BO_ 969 100;
BA_ "GenMsgCycleTimeFast" BO_ 969 0;
BA_ "GenMsgSendType" BO_ 969 0;
BA_ "VFrameFormat" BO_ 969 14;
BA_ "CANFD_BRS" BO_ 969 1;
BA_ "GenMsgCycleTime" BO_ 969 100;
BA_ "GenMsgCycleTimeFast" BO_ 969 0;
BA_ "GenMsgSendType" BO_ 969 0;
BA_ "VFrameFormat" BO_ 969 14;
BA_ "CANFD_BRS" BO_ 969 1;
BA_ "GenMsgCycleTime" BO_ 969 100;
BA_ "GenMsgCycleTimeFast" BO_ 969 0;
BA_ "GenMsgSendType" BO_ 969 0;
BA_ "VFrameFormat" BO_ 969 14;
BA_ "CANFD_BRS" BO_ 969 1;
BA_ "GenMsgCycleTime" BO_ 969 100;
BA_ "GenMsgCycleTimeFast" BO_ 969 0;
BA_ "GenMsgSendType" BO_ 969 0;
BA_ "VFrameFormat" BO_ 969 14;
BA_ "CANFD_BRS" BO_ 969 1;
BA_ "GenMsgCycleTime" BO_ 969 100;
BA_ "GenMsgCycleTimeFast" BO_ 969 0;
BA_ "GenMsgSendType" BO_ 969 0;
BA_ "VFrameFormat" BO_ 969 14;
BA_ "CANFD_BRS" BO_ 969 1;
BA_ "GenMsgCycleTime" BO_ 969 100;
BA_ "GenMsgCycleTimeFast" BO_ 969 0;
BA_ "GenMsgSendType" BO_ 969 0;
BA_ "VFrameFormat" BO_ 969 14;
BA_ "CANFD_BRS" BO_ 969 1;
BA_ "GenMsgCycleTime" BO_ 969 100;
BA_ "GenMsgCycleTimeFast" BO_ 969 0;
BA_ "GenMsgSendType" BO_ 969 0;
BA_ "VFrameFormat" BO_ 969 14;
BA_ "CANFD_BRS" BO_ 969 1;
BA_ "GenMsgCycleTime" BO_ 969 100;
BA_ "GenMsgCycleTimeFast" BO_ 969 0;
BA_ "GenMsgSendType" BO_ 969 0;
BA_ "VFrameFormat" BO_ 969 14;
BA_ "CANFD_BRS" BO_ 969 1;
BA_ "GenMsgCycleTime" BO_ 969 100;
BA_ "GenMsgCycleTimeFast" BO_ 969 0;
BA_ "GenMsgSendType" BO_ 969 0;
BA_ "VFrameFormat" BO_ 969 14;
BA_ "CANFD_BRS" BO_ 969 1;
BA_ "GenMsgCycleTime" BO_ 969 100;
BA_ "GenMsgCycleTimeFast" BO_ 969 0;
BA_ "GenMsgSendType" BO_ 969 0;
BA_ "VFrameFormat" BO_ 969 14;
BA_ "CANFD_BRS" BO_ 969 1;
BA_ "GenMsgCycleTime" BO_ 969 100;
BA_ "GenMsgCycleTimeFast" BO_ 969 0;
BA_ "GenMsgSendType" BO_ 969 0;
BA_ "VFrameFormat" BO_ 969 14;
BA_ "CANFD_BRS" BO_ 969 1;
BA_ "GenMsgCycleTime" BO_ 969 100;
BA_ "GenMsgCycleTimeFast" BO_ 969 0;
BA_ "GenMsgSendType" BO_ 969 0;
BA_ "VFrameFormat" BO_ 969 14;
BA_ "CANFD_BRS" BO_ 969 1;
BA_ "GenMsgCycleTime" BO_ 969 100;
BA_ "GenMsgCycleTimeFast" BO_ 969 0;
BA_ "GenMsgSendType" BO_ 969 0;
BA_ "VFrameFormat" BO_ 969 14;
BA_ "CANFD_BRS" BO_ 969 1;
BA_ "GenMsgCycleTime" BO_ 969 100;
BA_ "GenMsgCycleTimeFast" BO_ 969 0;
BA_ "GenMsgSendType" BO_ 969 0;
BA_ "VFrameFormat" BO_ 969 14;
BA_ "CANFD_BRS" BO_ 969 1;
BA_ "GenMsgCycleTime" BO_ 969 100;
BA_ "GenMsgCycleTimeFast" BO_ 969 0;
BA_ "GenMsgSendType" BO_ 969 0;
BA_ "VFrameFormat" BO_ 969 14;
BA_ "CANFD_BRS" BO_ 969 1;
BA_ "GenMsgCycleTime" BO_ 970 100;
BA_ "GenMsgCycleTimeFast" BO_ 970 0;
BA_ "GenMsgSendType" BO_ 970 0;
BA_ "VFrameFormat" BO_ 970 14;
BA_ "CANFD_BRS" BO_ 970 1;
BA_ "GenMsgCycleTime" BO_ 970 100;
BA_ "GenMsgCycleTimeFast" BO_ 970 0;
BA_ "GenMsgSendType" BO_ 970 0;
BA_ "VFrameFormat" BO_ 970 14;
BA_ "CANFD_BRS" BO_ 970 1;
BA_ "GenMsgCycleTime" BO_ 970 100;
BA_ "GenMsgCycleTimeFast" BO_ 970 0;
BA_ "GenMsgSendType" BO_ 970 0;
BA_ "VFrameFormat" BO_ 970 14;
BA_ "CANFD_BRS" BO_ 970 1;
BA_ "GenMsgCycleTime" BO_ 970 100;
BA_ "GenMsgCycleTimeFast" BO_ 970 0;
BA_ "GenMsgSendType" BO_ 970 0;
BA_ "VFrameFormat" BO_ 970 14;
BA_ "CANFD_BRS" BO_ 970 1;
BA_ "GenMsgCycleTime" BO_ 970 100;
BA_ "GenMsgCycleTimeFast" BO_ 970 0;
BA_ "GenMsgSendType" BO_ 970 0;
BA_ "VFrameFormat" BO_ 970 14;
BA_ "CANFD_BRS" BO_ 970 1;
BA_ "GenMsgCycleTime" BO_ 970 100;
BA_ "GenMsgCycleTimeFast" BO_ 970 0;
BA_ "GenMsgSendType" BO_ 970 0;
BA_ "VFrameFormat" BO_ 970 14;
BA_ "CANFD_BRS" BO_ 970 1;
BA_ "GenMsgCycleTime" BO_ 970 100;
BA_ "GenMsgCycleTimeFast" BO_ 970 0;
BA_ "GenMsgSendType" BO_ 970 0;
BA_ "VFrameFormat" BO_ 970 14;
BA_ "CANFD_BRS" BO_ 970 1;
BA_ "GenMsgCycleTime" BO_ 970 100;
BA_ "GenMsgCycleTimeFast" BO_ 970 0;
BA_ "GenMsgSendType" BO_ 970 0;
BA_ "VFrameFormat" BO_ 970 14;
BA_ "CANFD_BRS" BO_ 970 1;
BA_ "GenMsgCycleTime" BO_ 970 100;
BA_ "GenMsgCycleTimeFast" BO_ 970 0;
BA_ "GenMsgSendType" BO_ 970 0;
BA_ "VFrameFormat" BO_ 970 14;
BA_ "CANFD_BRS" BO_ 970 1;
BA_ "GenMsgCycleTime" BO_ 970 100;
BA_ "GenMsgCycleTimeFast" BO_ 970 0;
BA_ "GenMsgSendType" BO_ 970 0;
BA_ "VFrameFormat" BO_ 970 14;
BA_ "CANFD_BRS" BO_ 970 1;
BA_ "GenMsgCycleTime" BO_ 970 100;
BA_ "GenMsgCycleTimeFast" BO_ 970 0;
BA_ "GenMsgSendType" BO_ 970 0;
BA_ "VFrameFormat" BO_ 970 14;
BA_ "CANFD_BRS" BO_ 970 1;
BA_ "GenMsgCycleTime" BO_ 970 100;
BA_ "GenMsgCycleTimeFast" BO_ 970 0;
BA_ "GenMsgSendType" BO_ 970 0;
BA_ "VFrameFormat" BO_ 970 14;
BA_ "CANFD_BRS" BO_ 970 1;
BA_ "GenMsgCycleTime" BO_ 970 100;
BA_ "GenMsgCycleTimeFast" BO_ 970 0;
BA_ "GenMsgSendType" BO_ 970 0;
BA_ "VFrameFormat" BO_ 970 14;
BA_ "CANFD_BRS" BO_ 970 1;
BA_ "GenMsgCycleTime" BO_ 970 100;
BA_ "GenMsgCycleTimeFast" BO_ 970 0;
BA_ "GenMsgSendType" BO_ 970 0;
BA_ "VFrameFormat" BO_ 970 14;
BA_ "CANFD_BRS" BO_ 970 1;
BA_ "GenMsgCycleTime" BO_ 970 100;
BA_ "GenMsgCycleTimeFast" BO_ 970 0;
BA_ "GenMsgSendType" BO_ 970 0;
BA_ "VFrameFormat" BO_ 970 14;
BA_ "CANFD_BRS" BO_ 970 1;
BA_ "GenMsgCycleTime" BO_ 970 100;
BA_ "GenMsgCycleTimeFast" BO_ 970 0;
BA_ "GenMsgSendType" BO_ 970 0;
BA_ "VFrameFormat" BO_ 970 14;
BA_ "CANFD_BRS" BO_ 970 1;
BA_ "GenMsgCycleTime" BO_ 970 100;
BA_ "GenMsgCycleTimeFast" BO_ 970 0;
BA_ "GenMsgSendType" BO_ 970 0;
BA_ "VFrameFormat" BO_ 970 14;
BA_ "CANFD_BRS" BO_ 970 1;
BA_ "GenMsgCycleTime" BO_ 970 100;
BA_ "GenMsgCycleTimeFast" BO_ 970 0;
BA_ "GenMsgSendType" BO_ 970 0;
BA_ "VFrameFormat" BO_ 970 14;
BA_ "CANFD_BRS" BO_ 970 1;
BA_ "GenMsgCycleTime" BO_ 970 100;
BA_ "GenMsgCycleTimeFast" BO_ 970 0;
BA_ "GenMsgSendType" BO_ 970 0;
BA_ "VFrameFormat" BO_ 970 14;
BA_ "CANFD_BRS" BO_ 970 1;
BA_ "GenMsgCycleTime" BO_ 970 100;
BA_ "GenMsgCycleTimeFast" BO_ 970 0;
BA_ "GenMsgSendType" BO_ 970 0;
BA_ "VFrameFormat" BO_ 970 14;
BA_ "CANFD_BRS" BO_ 970 1;
BA_ "GenMsgCycleTime" BO_ 970 100;
BA_ "GenMsgCycleTimeFast" BO_ 970 0;
BA_ "GenMsgSendType" BO_ 970 0;
BA_ "VFrameFormat" BO_ 970 14;
BA_ "CANFD_BRS" BO_ 970 1;
BA_ "GenMsgCycleTime" BO_ 970 100;
BA_ "GenMsgCycleTimeFast" BO_ 970 0;
BA_ "GenMsgSendType" BO_ 970 0;
BA_ "VFrameFormat" BO_ 970 14;
BA_ "CANFD_BRS" BO_ 970 1;
BA_ "GenMsgCycleTime" BO_ 970 100;
BA_ "GenMsgCycleTimeFast" BO_ 970 0;
BA_ "GenMsgSendType" BO_ 970 0;
BA_ "VFrameFormat" BO_ 970 14;
BA_ "CANFD_BRS" BO_ 970 1;
BA_ "GenMsgCycleTime" BO_ 970 100;
BA_ "GenMsgCycleTimeFast" BO_ 970 0;
BA_ "GenMsgSendType" BO_ 970 0;
BA_ "VFrameFormat" BO_ 970 14;
BA_ "CANFD_BRS" BO_ 970 1;
BA_ "GenMsgCycleTime" BO_ 970 100;
BA_ "GenMsgCycleTimeFast" BO_ 970 0;
BA_ "GenMsgSendType" BO_ 970 0;
BA_ "VFrameFormat" BO_ 970 14;
BA_ "CANFD_BRS" BO_ 970 1;
BA_ "GenMsgCycleTime" BO_ 970 100;
BA_ "GenMsgCycleTimeFast" BO_ 970 0;
BA_ "GenMsgSendType" BO_ 970 0;
BA_ "VFrameFormat" BO_ 970 14;
BA_ "CANFD_BRS" BO_ 970 1;
BA_ "GenMsgCycleTime" BO_ 970 100;
BA_ "GenMsgCycleTimeFast" BO_ 970 0;
BA_ "GenMsgSendType" BO_ 970 0;
BA_ "VFrameFormat" BO_ 970 14;
BA_ "CANFD_BRS" BO_ 970 1;
BA_ "GenMsgCycleTime" BO_ 970 100;
BA_ "GenMsgCycleTimeFast" BO_ 970 0;
BA_ "GenMsgSendType" BO_ 970 0;
BA_ "VFrameFormat" BO_ 970 14;
BA_ "CANFD_BRS" BO_ 970 1;
BA_ "GenMsgCycleTime" BO_ 970 100;
BA_ "GenMsgCycleTimeFast" BO_ 970 0;
BA_ "GenMsgSendType" BO_ 970 0;
BA_ "VFrameFormat" BO_ 970 14;
BA_ "CANFD_BRS" BO_ 970 1;
BA_ "GenMsgCycleTime" BO_ 970 100;
BA_ "GenMsgCycleTimeFast" BO_ 970 0;
BA_ "GenMsgSendType" BO_ 970 0;
BA_ "VFrameFormat" BO_ 970 14;
BA_ "CANFD_BRS" BO_ 970 1;
BA_ "GenMsgCycleTime" BO_ 970 100;
BA_ "GenMsgCycleTimeFast" BO_ 970 0;
BA_ "GenMsgSendType" BO_ 970 0;
BA_ "VFrameFormat" BO_ 970 14;
BA_ "CANFD_BRS" BO_ 970 1;
BA_ "GenMsgCycleTime" BO_ 970 100;
BA_ "GenMsgCycleTimeFast" BO_ 970 0;
BA_ "GenMsgSendType" BO_ 970 0;
BA_ "VFrameFormat" BO_ 970 14;
BA_ "CANFD_BRS" BO_ 970 1;
BA_ "GenMsgCycleTime" BO_ 970 100;
BA_ "GenMsgCycleTimeFast" BO_ 970 0;
BA_ "GenMsgSendType" BO_ 970 0;
BA_ "VFrameFormat" BO_ 970 14;
BA_ "CANFD_BRS" BO_ 970 1;
BA_ "GenMsgCycleTime" BO_ 970 100;
BA_ "GenMsgCycleTimeFast" BO_ 970 0;
BA_ "GenMsgSendType" BO_ 970 0;
BA_ "VFrameFormat" BO_ 970 14;
BA_ "CANFD_BRS" BO_ 970 1;
BA_ "GenMsgCycleTime" BO_ 970 100;
BA_ "GenMsgCycleTimeFast" BO_ 970 0;
BA_ "GenMsgSendType" BO_ 970 0;
BA_ "VFrameFormat" BO_ 970 14;
BA_ "CANFD_BRS" BO_ 970 1;
BA_ "GenMsgCycleTime" BO_ 970 100;
BA_ "GenMsgCycleTimeFast" BO_ 970 0;
BA_ "GenMsgSendType" BO_ 970 0;
BA_ "VFrameFormat" BO_ 970 14;
BA_ "CANFD_BRS" BO_ 970 1;
BA_ "GenMsgCycleTime" BO_ 970 100;
BA_ "GenMsgCycleTimeFast" BO_ 970 0;
BA_ "GenMsgSendType" BO_ 970 0;
BA_ "VFrameFormat" BO_ 970 14;
BA_ "CANFD_BRS" BO_ 970 1;
BA_ "GenMsgCycleTime" BO_ 970 100;
BA_ "GenMsgCycleTimeFast" BO_ 970 0;
BA_ "GenMsgSendType" BO_ 970 0;
BA_ "VFrameFormat" BO_ 970 14;
BA_ "CANFD_BRS" BO_ 970 1;
BA_ "GenMsgCycleTime" BO_ 970 100;
BA_ "GenMsgCycleTimeFast" BO_ 970 0;
BA_ "GenMsgSendType" BO_ 970 0;
BA_ "VFrameFormat" BO_ 970 14;
BA_ "CANFD_BRS" BO_ 970 1;
BA_ "GenMsgCycleTime" BO_ 970 100;
BA_ "GenMsgCycleTimeFast" BO_ 970 0;
BA_ "GenMsgSendType" BO_ 970 0;
BA_ "VFrameFormat" BO_ 970 14;
BA_ "CANFD_BRS" BO_ 970 1;
BA_ "GenMsgCycleTime" BO_ 970 100;
BA_ "GenMsgCycleTimeFast" BO_ 970 0;
BA_ "GenMsgSendType" BO_ 970 0;
BA_ "VFrameFormat" BO_ 970 14;
BA_ "CANFD_BRS" BO_ 970 1;
BA_ "GenMsgCycleTime" BO_ 970 100;
BA_ "GenMsgCycleTimeFast" BO_ 970 0;
BA_ "GenMsgSendType" BO_ 970 0;
BA_ "VFrameFormat" BO_ 970 14;
BA_ "CANFD_BRS" BO_ 970 1;
BA_ "GenMsgCycleTime" BO_ 970 100;
BA_ "GenMsgCycleTimeFast" BO_ 970 0;
BA_ "GenMsgSendType" BO_ 970 0;
BA_ "VFrameFormat" BO_ 970 14;
BA_ "CANFD_BRS" BO_ 970 1;
BA_ "GenMsgCycleTime" BO_ 970 100;
BA_ "GenMsgCycleTimeFast" BO_ 970 0;
BA_ "GenMsgSendType" BO_ 970 0;
BA_ "VFrameFormat" BO_ 970 14;
BA_ "CANFD_BRS" BO_ 970 1;
BA_ "GenMsgCycleTime" BO_ 970 100;
BA_ "GenMsgCycleTimeFast" BO_ 970 0;
BA_ "GenMsgSendType" BO_ 970 0;
BA_ "VFrameFormat" BO_ 970 14;
BA_ "CANFD_BRS" BO_ 970 1;
BA_ "GenMsgCycleTime" BO_ 970 100;
BA_ "GenMsgCycleTimeFast" BO_ 970 0;
BA_ "GenMsgSendType" BO_ 970 0;
BA_ "VFrameFormat" BO_ 970 14;
BA_ "CANFD_BRS" BO_ 970 1;
BA_ "GenMsgCycleTime" BO_ 970 100;
BA_ "GenMsgCycleTimeFast" BO_ 970 0;
BA_ "GenMsgSendType" BO_ 970 0;
BA_ "VFrameFormat" BO_ 970 14;
BA_ "CANFD_BRS" BO_ 970 1;
BA_ "GenMsgCycleTime" BO_ 970 100;
BA_ "GenMsgCycleTimeFast" BO_ 970 0;
BA_ "GenMsgSendType" BO_ 970 0;
BA_ "VFrameFormat" BO_ 970 14;
BA_ "CANFD_BRS" BO_ 970 1;
BA_ "GenMsgCycleTime" BO_ 970 100;
BA_ "GenMsgCycleTimeFast" BO_ 970 0;
BA_ "GenMsgSendType" BO_ 970 0;
BA_ "VFrameFormat" BO_ 970 14;
BA_ "CANFD_BRS" BO_ 970 1;
BA_ "GenMsgCycleTime" BO_ 970 100;
BA_ "GenMsgCycleTimeFast" BO_ 970 0;
BA_ "GenMsgSendType" BO_ 970 0;
BA_ "VFrameFormat" BO_ 970 14;
BA_ "CANFD_BRS" BO_ 970 1;
BA_ "GenMsgCycleTime" BO_ 970 100;
BA_ "GenMsgCycleTimeFast" BO_ 970 0;
BA_ "GenMsgSendType" BO_ 970 0;
BA_ "VFrameFormat" BO_ 970 14;
BA_ "CANFD_BRS" BO_ 970 1;
BA_ "GenMsgCycleTime" BO_ 970 100;
BA_ "GenMsgCycleTimeFast" BO_ 970 0;
BA_ "GenMsgSendType" BO_ 970 0;
BA_ "VFrameFormat" BO_ 970 14;
BA_ "CANFD_BRS" BO_ 970 1;
BA_ "GenMsgCycleTime" BO_ 970 100;
BA_ "GenMsgCycleTimeFast" BO_ 970 0;
BA_ "GenMsgSendType" BO_ 970 0;
BA_ "VFrameFormat" BO_ 970 14;
BA_ "CANFD_BRS" BO_ 970 1;
BA_ "GenMsgCycleTime" BO_ 970 100;
BA_ "GenMsgCycleTimeFast" BO_ 970 0;
BA_ "GenMsgSendType" BO_ 970 0;
BA_ "VFrameFormat" BO_ 970 14;
BA_ "CANFD_BRS" BO_ 970 1;
BA_ "GenMsgCycleTime" BO_ 970 100;
BA_ "GenMsgCycleTimeFast" BO_ 970 0;
BA_ "GenMsgSendType" BO_ 970 0;
BA_ "VFrameFormat" BO_ 970 14;
BA_ "CANFD_BRS" BO_ 970 1;
BA_ "GenMsgCycleTime" BO_ 970 100;
BA_ "GenMsgCycleTimeFast" BO_ 970 0;
BA_ "GenMsgSendType" BO_ 970 0;
BA_ "VFrameFormat" BO_ 970 14;
BA_ "CANFD_BRS" BO_ 970 1;
BA_ "GenMsgCycleTime" BO_ 970 100;
BA_ "GenMsgCycleTimeFast" BO_ 970 0;
BA_ "GenMsgSendType" BO_ 970 0;
BA_ "VFrameFormat" BO_ 970 14;
BA_ "CANFD_BRS" BO_ 970 1;
BA_ "GenMsgCycleTime" BO_ 970 100;
BA_ "GenMsgCycleTimeFast" BO_ 970 0;
BA_ "GenMsgSendType" BO_ 970 0;
BA_ "VFrameFormat" BO_ 970 14;
BA_ "CANFD_BRS" BO_ 970 1;
BA_ "GenMsgCycleTime" BO_ 970 100;
BA_ "GenMsgCycleTimeFast" BO_ 970 0;
BA_ "GenMsgSendType" BO_ 970 0;
BA_ "VFrameFormat" BO_ 970 14;
BA_ "CANFD_BRS" BO_ 970 1;
BA_ "GenMsgCycleTime" BO_ 970 100;
BA_ "GenMsgCycleTimeFast" BO_ 970 0;
BA_ "GenMsgSendType" BO_ 970 0;
BA_ "VFrameFormat" BO_ 970 14;
BA_ "CANFD_BRS" BO_ 970 1;
BA_ "GenMsgCycleTime" BO_ 970 100;
BA_ "GenMsgCycleTimeFast" BO_ 970 0;
BA_ "GenMsgSendType" BO_ 970 0;
BA_ "VFrameFormat" BO_ 970 14;
BA_ "CANFD_BRS" BO_ 970 1;
BA_ "EventCommandSignal" SG_ 947 ADC_8_CRC 0;
BA_ "GatewayedSignals" SG_ 947 ADC_8_CRC 0;
BA_ "GenSigInactiveValue" SG_ 947 ADC_8_CRC 0;
BA_ "GenSigInvalidValue" SG_ 947 ADC_8_CRC 0;
BA_ "GenSigSendType" SG_ 947 ADC_8_CRC 1;
BA_ "GenSigStartValue" SG_ 947 ADC_8_CRC 0;
BA_ "GenSigTimeoutValue" SG_ 947 ADC_8_CRC 0;
BA_ "Remark" SG_ 947 ADC_8_CRC "";
BA_ "EventCommandSignal" SG_ 947 ADC_8_Counter 0;
BA_ "GatewayedSignals" SG_ 947 ADC_8_Counter 0;
BA_ "GenSigInactiveValue" SG_ 947 ADC_8_Counter 0;
BA_ "GenSigInvalidValue" SG_ 947 ADC_8_Counter 0;
BA_ "GenSigSendType" SG_ 947 ADC_8_Counter 1;
BA_ "GenSigStartValue" SG_ 947 ADC_8_Counter 0;
BA_ "GenSigTimeoutValue" SG_ 947 ADC_8_Counter 0;
BA_ "Remark" SG_ 947 ADC_8_Counter "";
BA_ "EventCommandSignal" SG_ 947 ADC_LowBeamReq 0;
BA_ "GatewayedSignals" SG_ 947 ADC_LowBeamReq 0;
BA_ "GenSigInactiveValue" SG_ 947 ADC_LowBeamReq 0;
BA_ "GenSigInvalidValue" SG_ 947 ADC_LowBeamReq 0;
BA_ "GenSigSendType" SG_ 947 ADC_LowBeamReq 1;
BA_ "GenSigStartValue" SG_ 947 ADC_LowBeamReq 0;
BA_ "GenSigTimeoutValue" SG_ 947 ADC_LowBeamReq 0;
BA_ "Remark" SG_ 947 ADC_LowBeamReq "";
BA_ "EventCommandSignal" SG_ 947 ADC_IHBC_HighBeamReq 0;
BA_ "GatewayedSignals" SG_ 947 ADC_IHBC_HighBeamReq 0;
BA_ "GenSigInactiveValue" SG_ 947 ADC_IHBC_HighBeamReq 0;
BA_ "GenSigInvalidValue" SG_ 947 ADC_IHBC_HighBeamReq 0;
BA_ "GenSigSendType" SG_ 947 ADC_IHBC_HighBeamReq 1;
BA_ "GenSigStartValue" SG_ 947 ADC_IHBC_HighBeamReq 0;
BA_ "GenSigTimeoutValue" SG_ 947 ADC_IHBC_HighBeamReq 0;
BA_ "Remark" SG_ 947 ADC_IHBC_HighBeamReq "";
BA_ "EventCommandSignal" SG_ 947 ADC_FlashReq 0;
BA_ "GatewayedSignals" SG_ 947 ADC_FlashReq 0;
BA_ "GenSigInactiveValue" SG_ 947 ADC_FlashReq 0;
BA_ "GenSigInvalidValue" SG_ 947 ADC_FlashReq 0;
BA_ "GenSigSendType" SG_ 947 ADC_FlashReq 1;
BA_ "GenSigStartValue" SG_ 947 ADC_FlashReq 0;
BA_ "GenSigTimeoutValue" SG_ 947 ADC_FlashReq 0;
BA_ "Remark" SG_ 947 ADC_FlashReq "";
BA_ "EventCommandSignal" SG_ 947 ADC_PositionLampReq 0;
BA_ "GatewayedSignals" SG_ 947 ADC_PositionLampReq 0;
BA_ "GenSigInactiveValue" SG_ 947 ADC_PositionLampReq 0;
BA_ "GenSigInvalidValue" SG_ 947 ADC_PositionLampReq 0;
BA_ "GenSigSendType" SG_ 947 ADC_PositionLampReq 1;
BA_ "GenSigStartValue" SG_ 947 ADC_PositionLampReq 0;
BA_ "GenSigTimeoutValue" SG_ 947 ADC_PositionLampReq 0;
BA_ "Remark" SG_ 947 ADC_PositionLampReq "";
BA_ "EventCommandSignal" SG_ 947 ADC_SunroofOpenCloseReq 0;
BA_ "GatewayedSignals" SG_ 947 ADC_SunroofOpenCloseReq 0;
BA_ "GenSigInactiveValue" SG_ 947 ADC_SunroofOpenCloseReq 0;
BA_ "GenSigInvalidValue" SG_ 947 ADC_SunroofOpenCloseReq 0;
BA_ "GenSigSendType" SG_ 947 ADC_SunroofOpenCloseReq 1;
BA_ "GenSigStartValue" SG_ 947 ADC_SunroofOpenCloseReq 0;
BA_ "GenSigTimeoutValue" SG_ 947 ADC_SunroofOpenCloseReq 0;
BA_ "Remark" SG_ 947 ADC_SunroofOpenCloseReq "";
BA_ "EventCommandSignal" SG_ 947 ADC_SOCWakeupHVReq 0;
BA_ "GatewayedSignals" SG_ 947 ADC_SOCWakeupHVReq 0;
BA_ "GenSigInactiveValue" SG_ 947 ADC_SOCWakeupHVReq 0;
BA_ "GenSigInvalidValue" SG_ 947 ADC_SOCWakeupHVReq 0;
BA_ "GenSigSendType" SG_ 947 ADC_SOCWakeupHVReq 1;
BA_ "GenSigStartValue" SG_ 947 ADC_SOCWakeupHVReq 0;
BA_ "GenSigTimeoutValue" SG_ 947 ADC_SOCWakeupHVReq 0;
BA_ "Remark" SG_ 947 ADC_SOCWakeupHVReq "";
BA_ "EventCommandSignal" SG_ 947 ADC_HVACCtrlReq 0;
BA_ "GatewayedSignals" SG_ 947 ADC_HVACCtrlReq 0;
BA_ "GenSigInactiveValue" SG_ 947 ADC_HVACCtrlReq 0;
BA_ "GenSigInvalidValue" SG_ 947 ADC_HVACCtrlReq 0;
BA_ "GenSigSendType" SG_ 947 ADC_HVACCtrlReq 1;
BA_ "GenSigStartValue" SG_ 947 ADC_HVACCtrlReq 0;
BA_ "GenSigTimeoutValue" SG_ 947 ADC_HVACCtrlReq 0;
BA_ "Remark" SG_ 947 ADC_HVACCtrlReq "";
BA_ "EventCommandSignal" SG_ 947 ADC_FFogLightReq 0;
BA_ "GatewayedSignals" SG_ 947 ADC_FFogLightReq 0;
BA_ "GenSigInactiveValue" SG_ 947 ADC_FFogLightReq 0;
BA_ "GenSigInvalidValue" SG_ 947 ADC_FFogLightReq 0;
BA_ "GenSigSendType" SG_ 947 ADC_FFogLightReq 1;
BA_ "GenSigStartValue" SG_ 947 ADC_FFogLightReq 0;
BA_ "GenSigTimeoutValue" SG_ 947 ADC_FFogLightReq 0;
BA_ "Remark" SG_ 947 ADC_FFogLightReq "";
BA_ "EventCommandSignal" SG_ 947 ADC_RFogLightReq 0;
BA_ "GatewayedSignals" SG_ 947 ADC_RFogLightReq 0;
BA_ "GenSigInactiveValue" SG_ 947 ADC_RFogLightReq 0;
BA_ "GenSigInvalidValue" SG_ 947 ADC_RFogLightReq 0;
BA_ "GenSigSendType" SG_ 947 ADC_RFogLightReq 1;
BA_ "GenSigStartValue" SG_ 947 ADC_RFogLightReq 0;
BA_ "GenSigTimeoutValue" SG_ 947 ADC_RFogLightReq 0;
BA_ "Remark" SG_ 947 ADC_RFogLightReq "";
BA_ "EventCommandSignal" SG_ 947 ADC_HornReq 0;
BA_ "GatewayedSignals" SG_ 947 ADC_HornReq 0;
BA_ "GenSigInactiveValue" SG_ 947 ADC_HornReq 0;
BA_ "GenSigInvalidValue" SG_ 947 ADC_HornReq 0;
BA_ "GenSigSendType" SG_ 947 ADC_HornReq 1;
BA_ "GenSigStartValue" SG_ 947 ADC_HornReq 0;
BA_ "GenSigTimeoutValue" SG_ 947 ADC_HornReq 0;
BA_ "Remark" SG_ 947 ADC_HornReq "";
BA_ "EventCommandSignal" SG_ 947 ADC_FWiperReq 0;
BA_ "GatewayedSignals" SG_ 947 ADC_FWiperReq 0;
BA_ "GenSigInactiveValue" SG_ 947 ADC_FWiperReq 0;
BA_ "GenSigInvalidValue" SG_ 947 ADC_FWiperReq 0;
BA_ "GenSigSendType" SG_ 947 ADC_FWiperReq 1;
BA_ "GenSigStartValue" SG_ 947 ADC_FWiperReq 0;
BA_ "GenSigTimeoutValue" SG_ 947 ADC_FWiperReq 0;
BA_ "Remark" SG_ 947 ADC_FWiperReq "";
BA_ "EventCommandSignal" SG_ 947 ADC_RWiperReq 0;
BA_ "GatewayedSignals" SG_ 947 ADC_RWiperReq 0;
BA_ "GenSigInactiveValue" SG_ 947 ADC_RWiperReq 0;
BA_ "GenSigInvalidValue" SG_ 947 ADC_RWiperReq 0;
BA_ "GenSigSendType" SG_ 947 ADC_RWiperReq 1;
BA_ "GenSigStartValue" SG_ 947 ADC_RWiperReq 0;
BA_ "GenSigTimeoutValue" SG_ 947 ADC_RWiperReq 0;
BA_ "Remark" SG_ 947 ADC_RWiperReq "";
BA_ "EventCommandSignal" SG_ 947 ADC_FWaterSprayReq 0;
BA_ "GatewayedSignals" SG_ 947 ADC_FWaterSprayReq 0;
BA_ "GenSigInactiveValue" SG_ 947 ADC_FWaterSprayReq 0;
BA_ "GenSigInvalidValue" SG_ 947 ADC_FWaterSprayReq 0;
BA_ "GenSigSendType" SG_ 947 ADC_FWaterSprayReq 1;
BA_ "GenSigStartValue" SG_ 947 ADC_FWaterSprayReq 0;
BA_ "GenSigTimeoutValue" SG_ 947 ADC_FWaterSprayReq 0;
BA_ "Remark" SG_ 947 ADC_FWaterSprayReq "";
BA_ "EventCommandSignal" SG_ 947 ADC_RWaterSprayReq 0;
BA_ "GatewayedSignals" SG_ 947 ADC_RWaterSprayReq 0;
BA_ "GenSigInactiveValue" SG_ 947 ADC_RWaterSprayReq 0;
BA_ "GenSigInvalidValue" SG_ 947 ADC_RWaterSprayReq 0;
BA_ "GenSigSendType" SG_ 947 ADC_RWaterSprayReq 1;
BA_ "GenSigStartValue" SG_ 947 ADC_RWaterSprayReq 0;
BA_ "GenSigTimeoutValue" SG_ 947 ADC_RWaterSprayReq 0;
BA_ "Remark" SG_ 947 ADC_RWaterSprayReq "";
BA_ "EventCommandSignal" SG_ 947 ADC_CCUReqVD 0;
BA_ "GatewayedSignals" SG_ 947 ADC_CCUReqVD 0;
BA_ "GenSigInactiveValue" SG_ 947 ADC_CCUReqVD 0;
BA_ "GenSigInvalidValue" SG_ 947 ADC_CCUReqVD 0;
BA_ "GenSigSendType" SG_ 947 ADC_CCUReqVD 1;
BA_ "GenSigStartValue" SG_ 947 ADC_CCUReqVD 0;
BA_ "GenSigTimeoutValue" SG_ 947 ADC_CCUReqVD 0;
BA_ "Remark" SG_ 947 ADC_CCUReqVD "";
BA_ "EventCommandSignal" SG_ 947 ADC_WindowOpenReq 0;
BA_ "GatewayedSignals" SG_ 947 ADC_WindowOpenReq 0;
BA_ "GenSigInactiveValue" SG_ 947 ADC_WindowOpenReq 0;
BA_ "GenSigInvalidValue" SG_ 947 ADC_WindowOpenReq 0;
BA_ "GenSigSendType" SG_ 947 ADC_WindowOpenReq 1;
BA_ "GenSigStartValue" SG_ 947 ADC_WindowOpenReq 0;
BA_ "GenSigTimeoutValue" SG_ 947 ADC_WindowOpenReq 0;
BA_ "Remark" SG_ 947 ADC_WindowOpenReq "";
BA_ "EventCommandSignal" SG_ 947 ADC_WindowCloseReq 0;
BA_ "GatewayedSignals" SG_ 947 ADC_WindowCloseReq 0;
BA_ "GenSigInactiveValue" SG_ 947 ADC_WindowCloseReq 0;
BA_ "GenSigInvalidValue" SG_ 947 ADC_WindowCloseReq 0;
BA_ "GenSigSendType" SG_ 947 ADC_WindowCloseReq 1;
BA_ "GenSigStartValue" SG_ 947 ADC_WindowCloseReq 0;
BA_ "GenSigTimeoutValue" SG_ 947 ADC_WindowCloseReq 0;
BA_ "Remark" SG_ 947 ADC_WindowCloseReq "";
BA_ "EventCommandSignal" SG_ 947 ADC_PLGMOpenReq 0;
BA_ "GatewayedSignals" SG_ 947 ADC_PLGMOpenReq 0;
BA_ "GenSigInactiveValue" SG_ 947 ADC_PLGMOpenReq 0;
BA_ "GenSigInvalidValue" SG_ 947 ADC_PLGMOpenReq 0;
BA_ "GenSigSendType" SG_ 947 ADC_PLGMOpenReq 1;
BA_ "GenSigStartValue" SG_ 947 ADC_PLGMOpenReq 0;
BA_ "GenSigTimeoutValue" SG_ 947 ADC_PLGMOpenReq 0;
BA_ "Remark" SG_ 947 ADC_PLGMOpenReq "";
BA_ "EventCommandSignal" SG_ 947 ADC_PLGMCloseReq 0;
BA_ "GatewayedSignals" SG_ 947 ADC_PLGMCloseReq 0;
BA_ "GenSigInactiveValue" SG_ 947 ADC_PLGMCloseReq 0;
BA_ "GenSigInvalidValue" SG_ 947 ADC_PLGMCloseReq 0;
BA_ "GenSigSendType" SG_ 947 ADC_PLGMCloseReq 1;
BA_ "GenSigStartValue" SG_ 947 ADC_PLGMCloseReq 0;
BA_ "GenSigTimeoutValue" SG_ 947 ADC_PLGMCloseReq 0;
BA_ "Remark" SG_ 947 ADC_PLGMCloseReq "";
BA_ "EventCommandSignal" SG_ 947 ADC_FDemistReq 0;
BA_ "GatewayedSignals" SG_ 947 ADC_FDemistReq 0;
BA_ "GenSigInactiveValue" SG_ 947 ADC_FDemistReq 0;
BA_ "GenSigInvalidValue" SG_ 947 ADC_FDemistReq 0;
BA_ "GenSigSendType" SG_ 947 ADC_FDemistReq 1;
BA_ "GenSigStartValue" SG_ 947 ADC_FDemistReq 0;
BA_ "GenSigTimeoutValue" SG_ 947 ADC_FDemistReq 0;
BA_ "Remark" SG_ 947 ADC_FDemistReq "";
BA_ "EventCommandSignal" SG_ 947 ADC_RDemistReq 0;
BA_ "GatewayedSignals" SG_ 947 ADC_RDemistReq 0;
BA_ "GenSigInactiveValue" SG_ 947 ADC_RDemistReq 0;
BA_ "GenSigInvalidValue" SG_ 947 ADC_RDemistReq 0;
BA_ "GenSigSendType" SG_ 947 ADC_RDemistReq 1;
BA_ "GenSigStartValue" SG_ 947 ADC_RDemistReq 0;
BA_ "GenSigTimeoutValue" SG_ 947 ADC_RDemistReq 0;
BA_ "Remark" SG_ 947 ADC_RDemistReq "";
BA_ "EventCommandSignal" SG_ 947 ADC_ThmPostRun 0;
BA_ "GatewayedSignals" SG_ 947 ADC_ThmPostRun 0;
BA_ "GenSigInactiveValue" SG_ 947 ADC_ThmPostRun 0;
BA_ "GenSigInvalidValue" SG_ 947 ADC_ThmPostRun 0;
BA_ "GenSigSendType" SG_ 947 ADC_ThmPostRun 1;
BA_ "GenSigStartValue" SG_ 947 ADC_ThmPostRun 0;
BA_ "GenSigTimeoutValue" SG_ 947 ADC_ThmPostRun 1;
BA_ "Remark" SG_ 947 ADC_ThmPostRun "";
BA_ "EventCommandSignal" SG_ 947 ADC_DriverFaceWindReq 0;
BA_ "GatewayedSignals" SG_ 947 ADC_DriverFaceWindReq 0;
BA_ "GenSigInactiveValue" SG_ 947 ADC_DriverFaceWindReq 0;
BA_ "GenSigInvalidValue" SG_ 947 ADC_DriverFaceWindReq 0;
BA_ "GenSigSendType" SG_ 947 ADC_DriverFaceWindReq 1;
BA_ "GenSigStartValue" SG_ 947 ADC_DriverFaceWindReq 0;
BA_ "GenSigTimeoutValue" SG_ 947 ADC_DriverFaceWindReq 0;
BA_ "Remark" SG_ 947 ADC_DriverFaceWindReq "";
BA_ "EventCommandSignal" SG_ 947 ADC_EcallReq 0;
BA_ "GatewayedSignals" SG_ 947 ADC_EcallReq 0;
BA_ "GenSigInactiveValue" SG_ 947 ADC_EcallReq 0;
BA_ "GenSigInvalidValue" SG_ 947 ADC_EcallReq 0;
BA_ "GenSigSendType" SG_ 947 ADC_EcallReq 1;
BA_ "GenSigStartValue" SG_ 947 ADC_EcallReq 0;
BA_ "GenSigTimeoutValue" SG_ 947 ADC_EcallReq 0;
BA_ "Remark" SG_ 947 ADC_EcallReq "";
BA_ "EventCommandSignal" SG_ 947 ADC_FlowReq 0;
BA_ "GatewayedSignals" SG_ 947 ADC_FlowReq 0;
BA_ "GenSigInactiveValue" SG_ 947 ADC_FlowReq 0;
BA_ "GenSigInvalidValue" SG_ 947 ADC_FlowReq 255;
BA_ "GenSigSendType" SG_ 947 ADC_FlowReq 1;
BA_ "GenSigStartValue" SG_ 947 ADC_FlowReq 0;
BA_ "GenSigTimeoutValue" SG_ 947 ADC_FlowReq 12;
BA_ "Remark" SG_ 947 ADC_FlowReq "";
BA_ "EventCommandSignal" SG_ 947 ADC_DriverSeatBeltPretightenReq 0;
BA_ "GatewayedSignals" SG_ 947 ADC_DriverSeatBeltPretightenReq 0;
BA_ "GenSigInactiveValue" SG_ 947 ADC_DriverSeatBeltPretightenReq 0;
BA_ "GenSigInvalidValue" SG_ 947 ADC_DriverSeatBeltPretightenReq 0;
BA_ "GenSigSendType" SG_ 947 ADC_DriverSeatBeltPretightenReq 1;
BA_ "GenSigStartValue" SG_ 947 ADC_DriverSeatBeltPretightenReq 0;
BA_ "GenSigTimeoutValue" SG_ 947 ADC_DriverSeatBeltPretightenReq 0;
BA_ "Remark" SG_ 947 ADC_DriverSeatBeltPretightenReq "";
BA_ "EventCommandSignal" SG_ 947 ADC_LockReq 0;
BA_ "GatewayedSignals" SG_ 947 ADC_LockReq 0;
BA_ "GenSigInactiveValue" SG_ 947 ADC_LockReq 0;
BA_ "GenSigInvalidValue" SG_ 947 ADC_LockReq 0;
BA_ "GenSigSendType" SG_ 947 ADC_LockReq 1;
BA_ "GenSigStartValue" SG_ 947 ADC_LockReq 0;
BA_ "GenSigTimeoutValue" SG_ 947 ADC_LockReq 0;
BA_ "Remark" SG_ 947 ADC_LockReq "";
BA_ "EventCommandSignal" SG_ 947 ADC_HoldLockReq 0;
BA_ "GatewayedSignals" SG_ 947 ADC_HoldLockReq 0;
BA_ "GenSigInactiveValue" SG_ 947 ADC_HoldLockReq 0;
BA_ "GenSigInvalidValue" SG_ 947 ADC_HoldLockReq 0;
BA_ "GenSigSendType" SG_ 947 ADC_HoldLockReq 1;
BA_ "GenSigStartValue" SG_ 947 ADC_HoldLockReq 0;
BA_ "GenSigTimeoutValue" SG_ 947 ADC_HoldLockReq 0;
BA_ "Remark" SG_ 947 ADC_HoldLockReq "";
BA_ "EventCommandSignal" SG_ 947 ADC_RearMirrorReq 0;
BA_ "GatewayedSignals" SG_ 947 ADC_RearMirrorReq 0;
BA_ "GenSigInactiveValue" SG_ 947 ADC_RearMirrorReq 0;
BA_ "GenSigInvalidValue" SG_ 947 ADC_RearMirrorReq 0;
BA_ "GenSigSendType" SG_ 947 ADC_RearMirrorReq 1;
BA_ "GenSigStartValue" SG_ 947 ADC_RearMirrorReq 0;
BA_ "GenSigTimeoutValue" SG_ 947 ADC_RearMirrorReq 0;
BA_ "Remark" SG_ 947 ADC_RearMirrorReq "";
BA_ "EventCommandSignal" SG_ 947 ADC_HoldRearMirrorReq 0;
BA_ "GatewayedSignals" SG_ 947 ADC_HoldRearMirrorReq 0;
BA_ "GenSigInactiveValue" SG_ 947 ADC_HoldRearMirrorReq 0;
BA_ "GenSigInvalidValue" SG_ 947 ADC_HoldRearMirrorReq 0;
BA_ "GenSigSendType" SG_ 947 ADC_HoldRearMirrorReq 1;
BA_ "GenSigStartValue" SG_ 947 ADC_HoldRearMirrorReq 0;
BA_ "GenSigTimeoutValue" SG_ 947 ADC_HoldRearMirrorReq 0;
BA_ "Remark" SG_ 947 ADC_HoldRearMirrorReq "";
BA_ "EventCommandSignal" SG_ 947 ADC_ADSLightReq 0;
BA_ "GatewayedSignals" SG_ 947 ADC_ADSLightReq 0;
BA_ "GenSigInactiveValue" SG_ 947 ADC_ADSLightReq 0;
BA_ "GenSigInvalidValue" SG_ 947 ADC_ADSLightReq 0;
BA_ "GenSigSendType" SG_ 947 ADC_ADSLightReq 1;
BA_ "GenSigStartValue" SG_ 947 ADC_ADSLightReq 0;
BA_ "GenSigTimeoutValue" SG_ 947 ADC_ADSLightReq 0;
BA_ "Remark" SG_ 947 ADC_ADSLightReq "";
BA_ "EventCommandSignal" SG_ 947 ADC_DriverSeatBeltVibrWarnReq 0;
BA_ "GatewayedSignals" SG_ 947 ADC_DriverSeatBeltVibrWarnReq 0;
BA_ "GenSigInactiveValue" SG_ 947 ADC_DriverSeatBeltVibrWarnReq 0;
BA_ "GenSigInvalidValue" SG_ 947 ADC_DriverSeatBeltVibrWarnReq 0;
BA_ "GenSigSendType" SG_ 947 ADC_DriverSeatBeltVibrWarnReq 0;
BA_ "GenSigStartValue" SG_ 947 ADC_DriverSeatBeltVibrWarnReq 0;
BA_ "GenSigTimeoutValue" SG_ 947 ADC_DriverSeatBeltVibrWarnReq 0;
BA_ "Remark" SG_ 947 ADC_DriverSeatBeltVibrWarnReq "";
BA_ "EventCommandSignal" SG_ 947 ADC_FrtWindshildHeatReq 0;
BA_ "GatewayedSignals" SG_ 947 ADC_FrtWindshildHeatReq 0;
BA_ "GenSigInactiveValue" SG_ 947 ADC_FrtWindshildHeatReq 0;
BA_ "GenSigInvalidValue" SG_ 947 ADC_FrtWindshildHeatReq 0;
BA_ "GenSigSendType" SG_ 947 ADC_FrtWindshildHeatReq 1;
BA_ "GenSigStartValue" SG_ 947 ADC_FrtWindshildHeatReq 0;
BA_ "GenSigTimeoutValue" SG_ 947 ADC_FrtWindshildHeatReq 0;
BA_ "Remark" SG_ 947 ADC_FrtWindshildHeatReq "";
BA_ "EventCommandSignal" SG_ 947 ADC_BeamSwReq 0;
BA_ "GatewayedSignals" SG_ 947 ADC_BeamSwReq 0;
BA_ "GenSigInactiveValue" SG_ 947 ADC_BeamSwReq 0;
BA_ "GenSigInvalidValue" SG_ 947 ADC_BeamSwReq 0;
BA_ "GenSigSendType" SG_ 947 ADC_BeamSwReq 0;
BA_ "GenSigStartValue" SG_ 947 ADC_BeamSwReq 0;
BA_ "GenSigTimeoutValue" SG_ 947 ADC_BeamSwReq 0;
BA_ "Remark" SG_ 947 ADC_BeamSwReq "";
BA_ "EventCommandSignal" SG_ 947 IFC_SysCalibrationSt 0;
BA_ "GatewayedSignals" SG_ 947 IFC_SysCalibrationSt 0;
BA_ "GenSigInactiveValue" SG_ 947 IFC_SysCalibrationSt 0;
BA_ "GenSigInvalidValue" SG_ 947 IFC_SysCalibrationSt 0;
BA_ "GenSigSendType" SG_ 947 IFC_SysCalibrationSt 1;
BA_ "GenSigStartValue" SG_ 947 IFC_SysCalibrationSt 0;
BA_ "GenSigTimeoutValue" SG_ 947 IFC_SysCalibrationSt 0;
BA_ "Remark" SG_ 947 IFC_SysCalibrationSt "";
BA_ "EventCommandSignal" SG_ 947 ADC_ADBIHBCEnableReq 0;
BA_ "GatewayedSignals" SG_ 947 ADC_ADBIHBCEnableReq 0;
BA_ "GenSigInactiveValue" SG_ 947 ADC_ADBIHBCEnableReq 0;
BA_ "GenSigInvalidValue" SG_ 947 ADC_ADBIHBCEnableReq 0;
BA_ "GenSigSendType" SG_ 947 ADC_ADBIHBCEnableReq 1;
BA_ "GenSigStartValue" SG_ 947 ADC_ADBIHBCEnableReq 0;
BA_ "GenSigTimeoutValue" SG_ 947 ADC_ADBIHBCEnableReq 0;
BA_ "Remark" SG_ 947 ADC_ADBIHBCEnableReq "";
BA_ "EventCommandSignal" SG_ 947 ADC_LowPowerReqVD_A 0;
BA_ "GatewayedSignals" SG_ 947 ADC_LowPowerReqVD_A 0;
BA_ "GenSigInactiveValue" SG_ 947 ADC_LowPowerReqVD_A 0;
BA_ "GenSigInvalidValue" SG_ 947 ADC_LowPowerReqVD_A 0;
BA_ "GenSigSendType" SG_ 947 ADC_LowPowerReqVD_A 1;
BA_ "GenSigStartValue" SG_ 947 ADC_LowPowerReqVD_A 0;
BA_ "GenSigTimeoutValue" SG_ 947 ADC_LowPowerReqVD_A 0;
BA_ "Remark" SG_ 947 ADC_LowPowerReqVD_A "";
BA_ "EventCommandSignal" SG_ 947 ADC_LowPowerReq_A 0;
BA_ "GatewayedSignals" SG_ 947 ADC_LowPowerReq_A 0;
BA_ "GenSigInactiveValue" SG_ 947 ADC_LowPowerReq_A 0;
BA_ "GenSigInvalidValue" SG_ 947 ADC_LowPowerReq_A 0;
BA_ "GenSigSendType" SG_ 947 ADC_LowPowerReq_A 1;
BA_ "GenSigStartValue" SG_ 947 ADC_LowPowerReq_A 0;
BA_ "GenSigTimeoutValue" SG_ 947 ADC_LowPowerReq_A 0;
BA_ "Remark" SG_ 947 ADC_LowPowerReq_A "";
BA_ "EventCommandSignal" SG_ 947 ADC_MachineStatus 0;
BA_ "GatewayedSignals" SG_ 947 ADC_MachineStatus 0;
BA_ "GenSigInactiveValue" SG_ 947 ADC_MachineStatus 0;
BA_ "GenSigInvalidValue" SG_ 947 ADC_MachineStatus 0;
BA_ "GenSigSendType" SG_ 947 ADC_MachineStatus 1;
BA_ "GenSigStartValue" SG_ 947 ADC_MachineStatus 0;
BA_ "GenSigTimeoutValue" SG_ 947 ADC_MachineStatus 0;
BA_ "Remark" SG_ 947 ADC_MachineStatus "";
BA_ "EventCommandSignal" SG_ 947 ADC_LowPowerFailReason 0;
BA_ "GatewayedSignals" SG_ 947 ADC_LowPowerFailReason 0;
BA_ "GenSigInactiveValue" SG_ 947 ADC_LowPowerFailReason 0;
BA_ "GenSigInvalidValue" SG_ 947 ADC_LowPowerFailReason 0;
BA_ "GenSigSendType" SG_ 947 ADC_LowPowerFailReason 1;
BA_ "GenSigStartValue" SG_ 947 ADC_LowPowerFailReason 0;
BA_ "GenSigTimeoutValue" SG_ 947 ADC_LowPowerFailReason 0;
BA_ "Remark" SG_ 947 ADC_LowPowerFailReason "";
BA_ "EventCommandSignal" SG_ 947 ADC_LightbarReq 0;
BA_ "GatewayedSignals" SG_ 947 ADC_LightbarReq 0;
BA_ "GenSigInactiveValue" SG_ 947 ADC_LightbarReq 0;
BA_ "GenSigInvalidValue" SG_ 947 ADC_LightbarReq 0;
BA_ "GenSigSendType" SG_ 947 ADC_LightbarReq 1;
BA_ "GenSigStartValue" SG_ 947 ADC_LightbarReq 0;
BA_ "GenSigTimeoutValue" SG_ 947 ADC_LightbarReq 15;
BA_ "Remark" SG_ 947 ADC_LightbarReq "";
BA_ "EventCommandSignal" SG_ 947 ADC_ChgPortControlReq 0;
BA_ "GatewayedSignals" SG_ 947 ADC_ChgPortControlReq 0;
BA_ "GenSigInactiveValue" SG_ 947 ADC_ChgPortControlReq 0;
BA_ "GenSigInvalidValue" SG_ 947 ADC_ChgPortControlReq 0;
BA_ "GenSigSendType" SG_ 947 ADC_ChgPortControlReq 1;
BA_ "GenSigStartValue" SG_ 947 ADC_ChgPortControlReq 0;
BA_ "GenSigTimeoutValue" SG_ 947 ADC_ChgPortControlReq 0;
BA_ "Remark" SG_ 947 ADC_ChgPortControlReq "";
BA_ "EventCommandSignal" SG_ 947 ADC_ChgPortHoldControlReq 0;
BA_ "GatewayedSignals" SG_ 947 ADC_ChgPortHoldControlReq 0;
BA_ "GenSigInactiveValue" SG_ 947 ADC_ChgPortHoldControlReq 0;
BA_ "GenSigInvalidValue" SG_ 947 ADC_ChgPortHoldControlReq 0;
BA_ "GenSigSendType" SG_ 947 ADC_ChgPortHoldControlReq 1;
BA_ "GenSigStartValue" SG_ 947 ADC_ChgPortHoldControlReq 0;
BA_ "GenSigTimeoutValue" SG_ 947 ADC_ChgPortHoldControlReq 0;
BA_ "Remark" SG_ 947 ADC_ChgPortHoldControlReq "";
BA_ "EventCommandSignal" SG_ 947 ADC_ChargHoldReq 0;
BA_ "GatewayedSignals" SG_ 947 ADC_ChargHoldReq 0;
BA_ "GenSigInactiveValue" SG_ 947 ADC_ChargHoldReq 0;
BA_ "GenSigInvalidValue" SG_ 947 ADC_ChargHoldReq 0;
BA_ "GenSigSendType" SG_ 947 ADC_ChargHoldReq 1;
BA_ "GenSigStartValue" SG_ 947 ADC_ChargHoldReq 0;
BA_ "GenSigTimeoutValue" SG_ 947 ADC_ChargHoldReq 0;
BA_ "Remark" SG_ 947 ADC_ChargHoldReq "";
BA_ "EventCommandSignal" SG_ 947 ADC_ChargReq 0;
BA_ "GatewayedSignals" SG_ 947 ADC_ChargReq 0;
BA_ "GenSigInactiveValue" SG_ 947 ADC_ChargReq 0;
BA_ "GenSigInvalidValue" SG_ 947 ADC_ChargReq 0;
BA_ "GenSigSendType" SG_ 947 ADC_ChargReq 1;
BA_ "GenSigStartValue" SG_ 947 ADC_ChargReq 0;
BA_ "GenSigTimeoutValue" SG_ 947 ADC_ChargReq 0;
BA_ "Remark" SG_ 947 ADC_ChargReq "";
BA_ "EventCommandSignal" SG_ 947 ADC_ChargGunHoldReq 0;
BA_ "GatewayedSignals" SG_ 947 ADC_ChargGunHoldReq 0;
BA_ "GenSigInactiveValue" SG_ 947 ADC_ChargGunHoldReq 0;
BA_ "GenSigInvalidValue" SG_ 947 ADC_ChargGunHoldReq 0;
BA_ "GenSigSendType" SG_ 947 ADC_ChargGunHoldReq 1;
BA_ "GenSigStartValue" SG_ 947 ADC_ChargGunHoldReq 0;
BA_ "GenSigTimeoutValue" SG_ 947 ADC_ChargGunHoldReq 0;
BA_ "Remark" SG_ 947 ADC_ChargGunHoldReq "";
BA_ "EventCommandSignal" SG_ 947 ADC_ChargGunReq 0;
BA_ "GatewayedSignals" SG_ 947 ADC_ChargGunReq 0;
BA_ "GenSigInactiveValue" SG_ 947 ADC_ChargGunReq 0;
BA_ "GenSigInvalidValue" SG_ 947 ADC_ChargGunReq 0;
BA_ "GenSigSendType" SG_ 947 ADC_ChargGunReq 1;
BA_ "GenSigStartValue" SG_ 947 ADC_ChargGunReq 0;
BA_ "GenSigTimeoutValue" SG_ 947 ADC_ChargGunReq 0;
BA_ "Remark" SG_ 947 ADC_ChargGunReq "";
BA_ "EventCommandSignal" SG_ 947 ADC_MCURTTemp 0;
BA_ "GatewayedSignals" SG_ 947 ADC_MCURTTemp 0;
BA_ "GenSigInactiveValue" SG_ 947 ADC_MCURTTemp 0;
BA_ "GenSigInvalidValue" SG_ 947 ADC_MCURTTemp 0;
BA_ "GenSigSendType" SG_ 947 ADC_MCURTTemp 1;
BA_ "GenSigStartValue" SG_ 947 ADC_MCURTTemp 0;
BA_ "GenSigTimeoutValue" SG_ 947 ADC_MCURTTemp 0;
BA_ "Remark" SG_ 947 ADC_MCURTTemp "";
BA_ "EventCommandSignal" SG_ 947 ADC_SOCRTtemp 0;
BA_ "GatewayedSignals" SG_ 947 ADC_SOCRTtemp 0;
BA_ "GenSigInactiveValue" SG_ 947 ADC_SOCRTtemp 0;
BA_ "GenSigInvalidValue" SG_ 947 ADC_SOCRTtemp 0;
BA_ "GenSigSendType" SG_ 947 ADC_SOCRTtemp 1;
BA_ "GenSigStartValue" SG_ 947 ADC_SOCRTtemp 0;
BA_ "GenSigTimeoutValue" SG_ 947 ADC_SOCRTtemp 0;
BA_ "Remark" SG_ 947 ADC_SOCRTtemp "";
BA_ "EventCommandSignal" SG_ 947 ADC_InteractLightReq 0;
BA_ "GatewayedSignals" SG_ 947 ADC_InteractLightReq 0;
BA_ "GenSigInactiveValue" SG_ 947 ADC_InteractLightReq 0;
BA_ "GenSigInvalidValue" SG_ 947 ADC_InteractLightReq 0;
BA_ "GenSigSendType" SG_ 947 ADC_InteractLightReq 1;
BA_ "GenSigStartValue" SG_ 947 ADC_InteractLightReq 0;
BA_ "GenSigTimeoutValue" SG_ 947 ADC_InteractLightReq 0;
BA_ "Remark" SG_ 947 ADC_InteractLightReq "";
BA_ "EventCommandSignal" SG_ 947 Reserved1 0;
BA_ "GatewayedSignals" SG_ 947 Reserved1 0;
BA_ "GenSigInactiveValue" SG_ 947 Reserved1 0;
BA_ "GenSigInvalidValue" SG_ 947 Reserved1 0;
BA_ "GenSigSendType" SG_ 947 Reserved1 1;
BA_ "GenSigStartValue" SG_ 947 Reserved1 0;
BA_ "GenSigTimeoutValue" SG_ 947 Reserved1 0;
BA_ "Remark" SG_ 947 Reserved1 "";
BA_ "EventCommandSignal" SG_ 175 ADC_9_CRC 0;
BA_ "GatewayedSignals" SG_ 175 ADC_9_CRC 0;
BA_ "GenSigInactiveValue" SG_ 175 ADC_9_CRC 0;
BA_ "GenSigInvalidValue" SG_ 175 ADC_9_CRC 0;
BA_ "GenSigSendType" SG_ 175 ADC_9_CRC 1;
BA_ "GenSigStartValue" SG_ 175 ADC_9_CRC 0;
BA_ "GenSigTimeoutValue" SG_ 175 ADC_9_CRC 0;
BA_ "Remark" SG_ 175 ADC_9_CRC "";
BA_ "EventCommandSignal" SG_ 175 ADC_9_Counter 0;
BA_ "GatewayedSignals" SG_ 175 ADC_9_Counter 0;
BA_ "GenSigInactiveValue" SG_ 175 ADC_9_Counter 0;
BA_ "GenSigInvalidValue" SG_ 175 ADC_9_Counter 0;
BA_ "GenSigSendType" SG_ 175 ADC_9_Counter 1;
BA_ "GenSigStartValue" SG_ 175 ADC_9_Counter 0;
BA_ "GenSigTimeoutValue" SG_ 175 ADC_9_Counter 0;
BA_ "Remark" SG_ 175 ADC_9_Counter "";
BA_ "EventCommandSignal" SG_ 175 ADC_PAAChallengeReceive 1;
BA_ "GatewayedSignals" SG_ 175 ADC_PAAChallengeReceive 0;
BA_ "GenSigInactiveValue" SG_ 175 ADC_PAAChallengeReceive 0;
BA_ "GenSigInvalidValue" SG_ 175 ADC_PAAChallengeReceive 0;
BA_ "GenSigSendType" SG_ 175 ADC_PAAChallengeReceive 0;
BA_ "GenSigStartValue" SG_ 175 ADC_PAAChallengeReceive 0;
BA_ "GenSigTimeoutValue" SG_ 175 ADC_PAAChallengeReceive 0;
BA_ "Remark" SG_ 175 ADC_PAAChallengeReceive "";
BA_ "EventCommandSignal" SG_ 175 PAA_TimeStampYear 1;
BA_ "GatewayedSignals" SG_ 175 PAA_TimeStampYear 0;
BA_ "GenSigInactiveValue" SG_ 175 PAA_TimeStampYear 0;
BA_ "GenSigInvalidValue" SG_ 175 PAA_TimeStampYear 0;
BA_ "GenSigSendType" SG_ 175 PAA_TimeStampYear 0;
BA_ "GenSigStartValue" SG_ 175 PAA_TimeStampYear 0;
BA_ "GenSigTimeoutValue" SG_ 175 PAA_TimeStampYear 0;
BA_ "Remark" SG_ 175 PAA_TimeStampYear "";
BA_ "EventCommandSignal" SG_ 175 ADC_PAAChallenge1SBM 1;
BA_ "GatewayedSignals" SG_ 175 ADC_PAAChallenge1SBM 0;
BA_ "GenSigInactiveValue" SG_ 175 ADC_PAAChallenge1SBM 0;
BA_ "GenSigInvalidValue" SG_ 175 ADC_PAAChallenge1SBM 0;
BA_ "GenSigSendType" SG_ 175 ADC_PAAChallenge1SBM 0;
BA_ "GenSigStartValue" SG_ 175 ADC_PAAChallenge1SBM 0;
BA_ "GenSigTimeoutValue" SG_ 175 ADC_PAAChallenge1SBM 0;
BA_ "Remark" SG_ 175 ADC_PAAChallenge1SBM "";
BA_ "EventCommandSignal" SG_ 175 ADC_PAAChallenge2SBM 1;
BA_ "GatewayedSignals" SG_ 175 ADC_PAAChallenge2SBM 0;
BA_ "GenSigInactiveValue" SG_ 175 ADC_PAAChallenge2SBM 0;
BA_ "GenSigInvalidValue" SG_ 175 ADC_PAAChallenge2SBM 0;
BA_ "GenSigSendType" SG_ 175 ADC_PAAChallenge2SBM 0;
BA_ "GenSigStartValue" SG_ 175 ADC_PAAChallenge2SBM 0;
BA_ "GenSigTimeoutValue" SG_ 175 ADC_PAAChallenge2SBM 0;
BA_ "Remark" SG_ 175 ADC_PAAChallenge2SBM "";
BA_ "EventCommandSignal" SG_ 175 ADC_PAAChallenge1TEL 1;
BA_ "GatewayedSignals" SG_ 175 ADC_PAAChallenge1TEL 0;
BA_ "GenSigInactiveValue" SG_ 175 ADC_PAAChallenge1TEL 0;
BA_ "GenSigInvalidValue" SG_ 175 ADC_PAAChallenge1TEL 0;
BA_ "GenSigSendType" SG_ 175 ADC_PAAChallenge1TEL 0;
BA_ "GenSigStartValue" SG_ 175 ADC_PAAChallenge1TEL 0;
BA_ "GenSigTimeoutValue" SG_ 175 ADC_PAAChallenge1TEL 0;
BA_ "Remark" SG_ 175 ADC_PAAChallenge1TEL "";
BA_ "EventCommandSignal" SG_ 175 ADC_PAAChallenge2TEL 1;
BA_ "GatewayedSignals" SG_ 175 ADC_PAAChallenge2TEL 0;
BA_ "GenSigInactiveValue" SG_ 175 ADC_PAAChallenge2TEL 0;
BA_ "GenSigInvalidValue" SG_ 175 ADC_PAAChallenge2TEL 0;
BA_ "GenSigSendType" SG_ 175 ADC_PAAChallenge2TEL 0;
BA_ "GenSigStartValue" SG_ 175 ADC_PAAChallenge2TEL 0;
BA_ "GenSigTimeoutValue" SG_ 175 ADC_PAAChallenge2TEL 0;
BA_ "Remark" SG_ 175 ADC_PAAChallenge2TEL "";
BA_ "EventCommandSignal" SG_ 175 PAA_TimeStampMonth 1;
BA_ "GatewayedSignals" SG_ 175 PAA_TimeStampMonth 0;
BA_ "GenSigInactiveValue" SG_ 175 PAA_TimeStampMonth 0;
BA_ "GenSigInvalidValue" SG_ 175 PAA_TimeStampMonth 0;
BA_ "GenSigSendType" SG_ 175 PAA_TimeStampMonth 0;
BA_ "GenSigStartValue" SG_ 175 PAA_TimeStampMonth 1;
BA_ "GenSigTimeoutValue" SG_ 175 PAA_TimeStampMonth 0;
BA_ "Remark" SG_ 175 PAA_TimeStampMonth "";
BA_ "EventCommandSignal" SG_ 175 PAA_TimeStampDay 1;
BA_ "GatewayedSignals" SG_ 175 PAA_TimeStampDay 0;
BA_ "GenSigInactiveValue" SG_ 175 PAA_TimeStampDay 0;
BA_ "GenSigInvalidValue" SG_ 175 PAA_TimeStampDay 0;
BA_ "GenSigSendType" SG_ 175 PAA_TimeStampDay 0;
BA_ "GenSigStartValue" SG_ 175 PAA_TimeStampDay 1;
BA_ "GenSigTimeoutValue" SG_ 175 PAA_TimeStampDay 0;
BA_ "Remark" SG_ 175 PAA_TimeStampDay "";
BA_ "EventCommandSignal" SG_ 175 PAA_TimeStampHour 1;
BA_ "GatewayedSignals" SG_ 175 PAA_TimeStampHour 0;
BA_ "GenSigInactiveValue" SG_ 175 PAA_TimeStampHour 0;
BA_ "GenSigInvalidValue" SG_ 175 PAA_TimeStampHour 0;
BA_ "GenSigSendType" SG_ 175 PAA_TimeStampHour 0;
BA_ "GenSigStartValue" SG_ 175 PAA_TimeStampHour 0;
BA_ "GenSigTimeoutValue" SG_ 175 PAA_TimeStampHour 0;
BA_ "Remark" SG_ 175 PAA_TimeStampHour "";
BA_ "EventCommandSignal" SG_ 175 PAA_TimeStampMin 1;
BA_ "GatewayedSignals" SG_ 175 PAA_TimeStampMin 0;
BA_ "GenSigInactiveValue" SG_ 175 PAA_TimeStampMin 0;
BA_ "GenSigInvalidValue" SG_ 175 PAA_TimeStampMin 0;
BA_ "GenSigSendType" SG_ 175 PAA_TimeStampMin 0;
BA_ "GenSigStartValue" SG_ 175 PAA_TimeStampMin 0;
BA_ "GenSigTimeoutValue" SG_ 175 PAA_TimeStampMin 0;
BA_ "Remark" SG_ 175 PAA_TimeStampMin "";
BA_ "EventCommandSignal" SG_ 175 PAA_TimeStampSec 1;
BA_ "GatewayedSignals" SG_ 175 PAA_TimeStampSec 0;
BA_ "GenSigInactiveValue" SG_ 175 PAA_TimeStampSec 0;
BA_ "GenSigInvalidValue" SG_ 175 PAA_TimeStampSec 0;
BA_ "GenSigSendType" SG_ 175 PAA_TimeStampSec 0;
BA_ "GenSigStartValue" SG_ 175 PAA_TimeStampSec 0;
BA_ "GenSigTimeoutValue" SG_ 175 PAA_TimeStampSec 0;
BA_ "Remark" SG_ 175 PAA_TimeStampSec "";
BA_ "EventCommandSignal" SG_ 175 PAA_TimeStampMilliSec 1;
BA_ "GatewayedSignals" SG_ 175 PAA_TimeStampMilliSec 0;
BA_ "GenSigInactiveValue" SG_ 175 PAA_TimeStampMilliSec 0;
BA_ "GenSigInvalidValue" SG_ 175 PAA_TimeStampMilliSec 0;
BA_ "GenSigSendType" SG_ 175 PAA_TimeStampMilliSec 0;
BA_ "GenSigStartValue" SG_ 175 PAA_TimeStampMilliSec 0;
BA_ "GenSigTimeoutValue" SG_ 175 PAA_TimeStampMilliSec 0;
BA_ "Remark" SG_ 175 PAA_TimeStampMilliSec "";
BA_ "EventCommandSignal" SG_ 175 ADC_APAActPushSt 1;
BA_ "GatewayedSignals" SG_ 175 ADC_APAActPushSt 0;
BA_ "GenSigInactiveValue" SG_ 175 ADC_APAActPushSt 0;
BA_ "GenSigInvalidValue" SG_ 175 ADC_APAActPushSt 0;
BA_ "GenSigSendType" SG_ 175 ADC_APAActPushSt 0;
BA_ "GenSigStartValue" SG_ 175 ADC_APAActPushSt 0;
BA_ "GenSigTimeoutValue" SG_ 175 ADC_APAActPushSt 0;
BA_ "Remark" SG_ 175 ADC_APAActPushSt "";
BA_ "EventCommandSignal" SG_ 175 PAA_DVRTriggerId 1;
BA_ "GatewayedSignals" SG_ 175 PAA_DVRTriggerId 0;
BA_ "GenSigInactiveValue" SG_ 175 PAA_DVRTriggerId 0;
BA_ "GenSigInvalidValue" SG_ 175 PAA_DVRTriggerId 0;
BA_ "GenSigSendType" SG_ 175 PAA_DVRTriggerId 0;
BA_ "GenSigStartValue" SG_ 175 PAA_DVRTriggerId 0;
BA_ "GenSigTimeoutValue" SG_ 175 PAA_DVRTriggerId 0;
BA_ "Remark" SG_ 175 PAA_DVRTriggerId "";
BA_ "EventCommandSignal" SG_ 175 PAA_DVRTrigger 1;
BA_ "GatewayedSignals" SG_ 175 PAA_DVRTrigger 0;
BA_ "GenSigInactiveValue" SG_ 175 PAA_DVRTrigger 0;
BA_ "GenSigInvalidValue" SG_ 175 PAA_DVRTrigger 0;
BA_ "GenSigSendType" SG_ 175 PAA_DVRTrigger 0;
BA_ "GenSigStartValue" SG_ 175 PAA_DVRTrigger 0;
BA_ "GenSigTimeoutValue" SG_ 175 PAA_DVRTrigger 0;
BA_ "Remark" SG_ 175 PAA_DVRTrigger "";
BA_ "EventCommandSignal" SG_ 175 ADC_LCAEnableSt 0;
BA_ "GatewayedSignals" SG_ 175 ADC_LCAEnableSt 0;
BA_ "GenSigInactiveValue" SG_ 175 ADC_LCAEnableSt 0;
BA_ "GenSigInvalidValue" SG_ 175 ADC_LCAEnableSt 0;
BA_ "GenSigSendType" SG_ 175 ADC_LCAEnableSt 1;
BA_ "GenSigStartValue" SG_ 175 ADC_LCAEnableSt 0;
BA_ "GenSigTimeoutValue" SG_ 175 ADC_LCAEnableSt 3;
BA_ "Remark" SG_ 175 ADC_LCAEnableSt "";
BA_ "EventCommandSignal" SG_ 175 ADC_HPALearningPathUniqueID 1;
BA_ "GatewayedSignals" SG_ 175 ADC_HPALearningPathUniqueID 0;
BA_ "GenSigInactiveValue" SG_ 175 ADC_HPALearningPathUniqueID 0;
BA_ "GenSigInvalidValue" SG_ 175 ADC_HPALearningPathUniqueID 0;
BA_ "GenSigSendType" SG_ 175 ADC_HPALearningPathUniqueID 0;
BA_ "GenSigStartValue" SG_ 175 ADC_HPALearningPathUniqueID 0;
BA_ "GenSigTimeoutValue" SG_ 175 ADC_HPALearningPathUniqueID 0;
BA_ "Remark" SG_ 175 ADC_HPALearningPathUniqueID "";
BA_ "EventCommandSignal" SG_ 135 ADC_VIMCode 1;
BA_ "GatewayedSignals" SG_ 135 ADC_VIMCode 0;
BA_ "GenSigInactiveValue" SG_ 135 ADC_VIMCode 0;
BA_ "GenSigInvalidValue" SG_ 135 ADC_VIMCode 0;
BA_ "GenSigSendType" SG_ 135 ADC_VIMCode 0;
BA_ "GenSigStartValue" SG_ 135 ADC_VIMCode 0;
BA_ "GenSigTimeoutValue" SG_ 135 ADC_VIMCode 0;
BA_ "Remark" SG_ 135 ADC_VIMCode "";
BA_ "EventCommandSignal" SG_ 1234 RLR_DTCCode 1;
BA_ "GatewayedSignals" SG_ 1234 RLR_DTCCode 0;
BA_ "GenSigInactiveValue" SG_ 1234 RLR_DTCCode 0;
BA_ "GenSigInvalidValue" SG_ 1234 RLR_DTCCode 0;
BA_ "GenSigSendType" SG_ 1234 RLR_DTCCode 0;
BA_ "GenSigStartValue" SG_ 1234 RLR_DTCCode 0;
BA_ "GenSigTimeoutValue" SG_ 1234 RLR_DTCCode 0;
BA_ "Remark" SG_ 1234 RLR_DTCCode "";
BA_ "EventCommandSignal" SG_ 1235 RRR_DTCCode 1;
BA_ "GatewayedSignals" SG_ 1235 RRR_DTCCode 0;
BA_ "GenSigInactiveValue" SG_ 1235 RRR_DTCCode 0;
BA_ "GenSigInvalidValue" SG_ 1235 RRR_DTCCode 0;
BA_ "GenSigSendType" SG_ 1235 RRR_DTCCode 0;
BA_ "GenSigStartValue" SG_ 1235 RRR_DTCCode 0;
BA_ "GenSigTimeoutValue" SG_ 1235 RRR_DTCCode 0;
BA_ "Remark" SG_ 1235 RRR_DTCCode "";
BA_ "EventCommandSignal" SG_ 1785 ADC_MCU_Diag_Response 0;
BA_ "GatewayedSignals" SG_ 1785 ADC_MCU_Diag_Response 0;
BA_ "GenSigInactiveValue" SG_ 1785 ADC_MCU_Diag_Response 0;
BA_ "GenSigInvalidValue" SG_ 1785 ADC_MCU_Diag_Response 0;
BA_ "GenSigSendType" SG_ 1785 ADC_MCU_Diag_Response 1;
BA_ "GenSigStartValue" SG_ 1785 ADC_MCU_Diag_Response 0;
BA_ "GenSigTimeoutValue" SG_ 1785 ADC_MCU_Diag_Response 0;
BA_ "Remark" SG_ 1785 ADC_MCU_Diag_Response "";
BA_ "EventCommandSignal" SG_ 127 ADC_IMMO 1;
BA_ "GatewayedSignals" SG_ 127 ADC_IMMO 0;
BA_ "GenSigInactiveValue" SG_ 127 ADC_IMMO 0;
BA_ "GenSigInvalidValue" SG_ 127 ADC_IMMO 0;
BA_ "GenSigSendType" SG_ 127 ADC_IMMO 0;
BA_ "GenSigStartValue" SG_ 127 ADC_IMMO 0;
BA_ "GenSigTimeoutValue" SG_ 127 ADC_IMMO 0;
BA_ "Remark" SG_ 127 ADC_IMMO "";
BA_ "EventCommandSignal" SG_ 1934 ADC_Diag_Response 1;
BA_ "GatewayedSignals" SG_ 1934 ADC_Diag_Response 0;
BA_ "GenSigInactiveValue" SG_ 1934 ADC_Diag_Response 0;
BA_ "GenSigInvalidValue" SG_ 1934 ADC_Diag_Response 0;
BA_ "GenSigSendType" SG_ 1934 ADC_Diag_Response 0;
BA_ "GenSigStartValue" SG_ 1934 ADC_Diag_Response 0;
BA_ "GenSigTimeoutValue" SG_ 1934 ADC_Diag_Response 0;
BA_ "Remark" SG_ 1934 ADC_Diag_Response "";
BA_ "EventCommandSignal" SG_ 1294 ADC_NMNodeAddress 0;
BA_ "GatewayedSignals" SG_ 1294 ADC_NMNodeAddress 0;
BA_ "GenSigInactiveValue" SG_ 1294 ADC_NMNodeAddress 0;
BA_ "GenSigInvalidValue" SG_ 1294 ADC_NMNodeAddress 0;
BA_ "GenSigSendType" SG_ 1294 ADC_NMNodeAddress 1;
BA_ "GenSigStartValue" SG_ 1294 ADC_NMNodeAddress 14;
BA_ "GenSigTimeoutValue" SG_ 1294 ADC_NMNodeAddress 0;
BA_ "Remark" SG_ 1294 ADC_NMNodeAddress "";
BA_ "EventCommandSignal" SG_ 1294 ADC_NMCBV 0;
BA_ "GatewayedSignals" SG_ 1294 ADC_NMCBV 0;
BA_ "GenSigInactiveValue" SG_ 1294 ADC_NMCBV 0;
BA_ "GenSigInvalidValue" SG_ 1294 ADC_NMCBV 0;
BA_ "GenSigSendType" SG_ 1294 ADC_NMCBV 1;
BA_ "GenSigStartValue" SG_ 1294 ADC_NMCBV 0;
BA_ "GenSigTimeoutValue" SG_ 1294 ADC_NMCBV 0;
BA_ "Remark" SG_ 1294 ADC_NMCBV "";
BA_ "EventCommandSignal" SG_ 1294 ADC_NMWakeupOrigin 0;
BA_ "GatewayedSignals" SG_ 1294 ADC_NMWakeupOrigin 0;
BA_ "GenSigInactiveValue" SG_ 1294 ADC_NMWakeupOrigin 0;
BA_ "GenSigInvalidValue" SG_ 1294 ADC_NMWakeupOrigin 0;
BA_ "GenSigSendType" SG_ 1294 ADC_NMWakeupOrigin 1;
BA_ "GenSigStartValue" SG_ 1294 ADC_NMWakeupOrigin 0;
BA_ "GenSigTimeoutValue" SG_ 1294 ADC_NMWakeupOrigin 0;
BA_ "Remark" SG_ 1294 ADC_NMWakeupOrigin "";
BA_ "EventCommandSignal" SG_ 1294 ADC_PNCInformation0 0;
BA_ "GatewayedSignals" SG_ 1294 ADC_PNCInformation0 0;
BA_ "GenSigInactiveValue" SG_ 1294 ADC_PNCInformation0 0;
BA_ "GenSigInvalidValue" SG_ 1294 ADC_PNCInformation0 0;
BA_ "GenSigSendType" SG_ 1294 ADC_PNCInformation0 1;
BA_ "GenSigStartValue" SG_ 1294 ADC_PNCInformation0 0;
BA_ "GenSigTimeoutValue" SG_ 1294 ADC_PNCInformation0 0;
BA_ "Remark" SG_ 1294 ADC_PNCInformation0 "";
BA_ "EventCommandSignal" SG_ 1294 ADC_PNCInformation1 0;
BA_ "GatewayedSignals" SG_ 1294 ADC_PNCInformation1 0;
BA_ "GenSigInactiveValue" SG_ 1294 ADC_PNCInformation1 0;
BA_ "GenSigInvalidValue" SG_ 1294 ADC_PNCInformation1 0;
BA_ "GenSigSendType" SG_ 1294 ADC_PNCInformation1 1;
BA_ "GenSigStartValue" SG_ 1294 ADC_PNCInformation1 0;
BA_ "GenSigTimeoutValue" SG_ 1294 ADC_PNCInformation1 0;
BA_ "Remark" SG_ 1294 ADC_PNCInformation1 "";
BA_ "EventCommandSignal" SG_ 1294 ADC_PNCInformation2 0;
BA_ "GatewayedSignals" SG_ 1294 ADC_PNCInformation2 0;
BA_ "GenSigInactiveValue" SG_ 1294 ADC_PNCInformation2 0;
BA_ "GenSigInvalidValue" SG_ 1294 ADC_PNCInformation2 0;
BA_ "GenSigSendType" SG_ 1294 ADC_PNCInformation2 1;
BA_ "GenSigStartValue" SG_ 1294 ADC_PNCInformation2 0;
BA_ "GenSigTimeoutValue" SG_ 1294 ADC_PNCInformation2 0;
BA_ "Remark" SG_ 1294 ADC_PNCInformation2 "";
BA_ "EventCommandSignal" SG_ 1188 ADC_DTC 1;
BA_ "GatewayedSignals" SG_ 1188 ADC_DTC 0;
BA_ "GenSigInactiveValue" SG_ 1188 ADC_DTC 0;
BA_ "GenSigInvalidValue" SG_ 1188 ADC_DTC 0;
BA_ "GenSigSendType" SG_ 1188 ADC_DTC 0;
BA_ "GenSigStartValue" SG_ 1188 ADC_DTC 0;
BA_ "GenSigTimeoutValue" SG_ 1188 ADC_DTC 0;
BA_ "Remark" SG_ 1188 ADC_DTC "";
BA_ "EventCommandSignal" SG_ 969 ADAS_RemoterParkingOnlineOrNot 0;
BA_ "GatewayedSignals" SG_ 969 ADAS_RemoterParkingOnlineOrNot 0;
BA_ "GenSigInactiveValue" SG_ 969 ADAS_RemoterParkingOnlineOrNot 0;
BA_ "GenSigInvalidValue" SG_ 969 ADAS_RemoterParkingOnlineOrNot 0;
BA_ "GenSigSendType" SG_ 969 ADAS_RemoterParkingOnlineOrNot 1;
BA_ "GenSigStartValue" SG_ 969 ADAS_RemoterParkingOnlineOrNot 0;
BA_ "GenSigTimeoutValue" SG_ 969 ADAS_RemoterParkingOnlineOrNot 0;
BA_ "Remark" SG_ 969 ADAS_RemoterParkingOnlineOrNot "";
BA_ "EventCommandSignal" SG_ 969 ADC_RpaParkAuthn 0;
BA_ "GatewayedSignals" SG_ 969 ADC_RpaParkAuthn 0;
BA_ "GenSigInactiveValue" SG_ 969 ADC_RpaParkAuthn 0;
BA_ "GenSigInvalidValue" SG_ 969 ADC_RpaParkAuthn 0;
BA_ "GenSigSendType" SG_ 969 ADC_RpaParkAuthn 1;
BA_ "GenSigStartValue" SG_ 969 ADC_RpaParkAuthn 0;
BA_ "GenSigTimeoutValue" SG_ 969 ADC_RpaParkAuthn 0;
BA_ "Remark" SG_ 969 ADC_RpaParkAuthn "";
BA_ "EventCommandSignal" SG_ 969 ADC_RemParkPatSel 0;
BA_ "GatewayedSignals" SG_ 969 ADC_RemParkPatSel 0;
BA_ "GenSigInactiveValue" SG_ 969 ADC_RemParkPatSel 0;
BA_ "GenSigInvalidValue" SG_ 969 ADC_RemParkPatSel 0;
BA_ "GenSigSendType" SG_ 969 ADC_RemParkPatSel 1;
BA_ "GenSigStartValue" SG_ 969 ADC_RemParkPatSel 0;
BA_ "GenSigTimeoutValue" SG_ 969 ADC_RemParkPatSel 0;
BA_ "Remark" SG_ 969 ADC_RemParkPatSel "";
BA_ "EventCommandSignal" SG_ 969 ADC_ParkDirCfm 0;
BA_ "GatewayedSignals" SG_ 969 ADC_ParkDirCfm 0;
BA_ "GenSigInactiveValue" SG_ 969 ADC_ParkDirCfm 0;
BA_ "GenSigInvalidValue" SG_ 969 ADC_ParkDirCfm 0;
BA_ "GenSigSendType" SG_ 969 ADC_ParkDirCfm 1;
BA_ "GenSigStartValue" SG_ 969 ADC_ParkDirCfm 0;
BA_ "GenSigTimeoutValue" SG_ 969 ADC_ParkDirCfm 0;
BA_ "Remark" SG_ 969 ADC_ParkDirCfm "";
BA_ "EventCommandSignal" SG_ 969 ADC_ParkStMac 0;
BA_ "GatewayedSignals" SG_ 969 ADC_ParkStMac 0;
BA_ "GenSigInactiveValue" SG_ 969 ADC_ParkStMac 0;
BA_ "GenSigInvalidValue" SG_ 969 ADC_ParkStMac 0;
BA_ "GenSigSendType" SG_ 969 ADC_ParkStMac 1;
BA_ "GenSigStartValue" SG_ 969 ADC_ParkStMac 0;
BA_ "GenSigTimeoutValue" SG_ 969 ADC_ParkStMac 0;
BA_ "Remark" SG_ 969 ADC_ParkStMac "";
BA_ "EventCommandSignal" SG_ 969 ADC_PwrOnOffReq 0;
BA_ "GatewayedSignals" SG_ 969 ADC_PwrOnOffReq 0;
BA_ "GenSigInactiveValue" SG_ 969 ADC_PwrOnOffReq 0;
BA_ "GenSigInvalidValue" SG_ 969 ADC_PwrOnOffReq 0;
BA_ "GenSigSendType" SG_ 969 ADC_PwrOnOffReq 1;
BA_ "GenSigStartValue" SG_ 969 ADC_PwrOnOffReq 0;
BA_ "GenSigTimeoutValue" SG_ 969 ADC_PwrOnOffReq 0;
BA_ "Remark" SG_ 969 ADC_PwrOnOffReq "";
BA_ "EventCommandSignal" SG_ 969 ADC_ParkOutDir_ParaLe 0;
BA_ "GatewayedSignals" SG_ 969 ADC_ParkOutDir_ParaLe 0;
BA_ "GenSigInactiveValue" SG_ 969 ADC_ParkOutDir_ParaLe 0;
BA_ "GenSigInvalidValue" SG_ 969 ADC_ParkOutDir_ParaLe 0;
BA_ "GenSigSendType" SG_ 969 ADC_ParkOutDir_ParaLe 1;
BA_ "GenSigStartValue" SG_ 969 ADC_ParkOutDir_ParaLe 0;
BA_ "GenSigTimeoutValue" SG_ 969 ADC_ParkOutDir_ParaLe 0;
BA_ "Remark" SG_ 969 ADC_ParkOutDir_ParaLe "";
BA_ "EventCommandSignal" SG_ 969 ADC_ParkOutDir_ParaRi 0;
BA_ "GatewayedSignals" SG_ 969 ADC_ParkOutDir_ParaRi 0;
BA_ "GenSigInactiveValue" SG_ 969 ADC_ParkOutDir_ParaRi 0;
BA_ "GenSigInvalidValue" SG_ 969 ADC_ParkOutDir_ParaRi 0;
BA_ "GenSigSendType" SG_ 969 ADC_ParkOutDir_ParaRi 1;
BA_ "GenSigStartValue" SG_ 969 ADC_ParkOutDir_ParaRi 0;
BA_ "GenSigTimeoutValue" SG_ 969 ADC_ParkOutDir_ParaRi 0;
BA_ "Remark" SG_ 969 ADC_ParkOutDir_ParaRi "";
BA_ "EventCommandSignal" SG_ 969 ADC_ParkOutDir_PerpFwd 0;
BA_ "GatewayedSignals" SG_ 969 ADC_ParkOutDir_PerpFwd 0;
BA_ "GenSigInactiveValue" SG_ 969 ADC_ParkOutDir_PerpFwd 0;
BA_ "GenSigInvalidValue" SG_ 969 ADC_ParkOutDir_PerpFwd 0;
BA_ "GenSigSendType" SG_ 969 ADC_ParkOutDir_PerpFwd 1;
BA_ "GenSigStartValue" SG_ 969 ADC_ParkOutDir_PerpFwd 0;
BA_ "GenSigTimeoutValue" SG_ 969 ADC_ParkOutDir_PerpFwd 0;
BA_ "Remark" SG_ 969 ADC_ParkOutDir_PerpFwd "";
BA_ "EventCommandSignal" SG_ 969 ADC_ParkOutDir_PerpLeFwd 0;
BA_ "GatewayedSignals" SG_ 969 ADC_ParkOutDir_PerpLeFwd 0;
BA_ "GenSigInactiveValue" SG_ 969 ADC_ParkOutDir_PerpLeFwd 0;
BA_ "GenSigInvalidValue" SG_ 969 ADC_ParkOutDir_PerpLeFwd 0;
BA_ "GenSigSendType" SG_ 969 ADC_ParkOutDir_PerpLeFwd 1;
BA_ "GenSigStartValue" SG_ 969 ADC_ParkOutDir_PerpLeFwd 0;
BA_ "GenSigTimeoutValue" SG_ 969 ADC_ParkOutDir_PerpLeFwd 0;
BA_ "Remark" SG_ 969 ADC_ParkOutDir_PerpLeFwd "";
BA_ "EventCommandSignal" SG_ 969 ADC_ParkOutDir_PerpRiFwd 0;
BA_ "GatewayedSignals" SG_ 969 ADC_ParkOutDir_PerpRiFwd 0;
BA_ "GenSigInactiveValue" SG_ 969 ADC_ParkOutDir_PerpRiFwd 0;
BA_ "GenSigInvalidValue" SG_ 969 ADC_ParkOutDir_PerpRiFwd 0;
BA_ "GenSigSendType" SG_ 969 ADC_ParkOutDir_PerpRiFwd 1;
BA_ "GenSigStartValue" SG_ 969 ADC_ParkOutDir_PerpRiFwd 0;
BA_ "GenSigTimeoutValue" SG_ 969 ADC_ParkOutDir_PerpRiFwd 0;
BA_ "Remark" SG_ 969 ADC_ParkOutDir_PerpRiFwd "";
BA_ "EventCommandSignal" SG_ 969 ADC_ParkOutDir_PerpLeBack 0;
BA_ "GatewayedSignals" SG_ 969 ADC_ParkOutDir_PerpLeBack 0;
BA_ "GenSigInactiveValue" SG_ 969 ADC_ParkOutDir_PerpLeBack 0;
BA_ "GenSigInvalidValue" SG_ 969 ADC_ParkOutDir_PerpLeBack 0;
BA_ "GenSigSendType" SG_ 969 ADC_ParkOutDir_PerpLeBack 1;
BA_ "GenSigStartValue" SG_ 969 ADC_ParkOutDir_PerpLeBack 0;
BA_ "GenSigTimeoutValue" SG_ 969 ADC_ParkOutDir_PerpLeBack 0;
BA_ "Remark" SG_ 969 ADC_ParkOutDir_PerpLeBack "";
BA_ "EventCommandSignal" SG_ 969 ADC_ParkOutDir_PerpRiBack 0;
BA_ "GatewayedSignals" SG_ 969 ADC_ParkOutDir_PerpRiBack 0;
BA_ "GenSigInactiveValue" SG_ 969 ADC_ParkOutDir_PerpRiBack 0;
BA_ "GenSigInvalidValue" SG_ 969 ADC_ParkOutDir_PerpRiBack 0;
BA_ "GenSigSendType" SG_ 969 ADC_ParkOutDir_PerpRiBack 1;
BA_ "GenSigStartValue" SG_ 969 ADC_ParkOutDir_PerpRiBack 0;
BA_ "GenSigTimeoutValue" SG_ 969 ADC_ParkOutDir_PerpRiBack 0;
BA_ "Remark" SG_ 969 ADC_ParkOutDir_PerpRiBack "";
BA_ "EventCommandSignal" SG_ 969 ADC_ParkOutDir_PerpBack 0;
BA_ "GatewayedSignals" SG_ 969 ADC_ParkOutDir_PerpBack 0;
BA_ "GenSigInactiveValue" SG_ 969 ADC_ParkOutDir_PerpBack 0;
BA_ "GenSigInvalidValue" SG_ 969 ADC_ParkOutDir_PerpBack 0;
BA_ "GenSigSendType" SG_ 969 ADC_ParkOutDir_PerpBack 1;
BA_ "GenSigStartValue" SG_ 969 ADC_ParkOutDir_PerpBack 0;
BA_ "GenSigTimeoutValue" SG_ 969 ADC_ParkOutDir_PerpBack 0;
BA_ "Remark" SG_ 969 ADC_ParkOutDir_PerpBack "";
BA_ "EventCommandSignal" SG_ 969 ADC_APA_RPAFctUnavlMsg1 0;
BA_ "GatewayedSignals" SG_ 969 ADC_APA_RPAFctUnavlMsg1 0;
BA_ "GenSigInactiveValue" SG_ 969 ADC_APA_RPAFctUnavlMsg1 0;
BA_ "GenSigInvalidValue" SG_ 969 ADC_APA_RPAFctUnavlMsg1 0;
BA_ "GenSigSendType" SG_ 969 ADC_APA_RPAFctUnavlMsg1 1;
BA_ "GenSigStartValue" SG_ 969 ADC_APA_RPAFctUnavlMsg1 0;
BA_ "GenSigTimeoutValue" SG_ 969 ADC_APA_RPAFctUnavlMsg1 0;
BA_ "Remark" SG_ 969 ADC_APA_RPAFctUnavlMsg1 "";
BA_ "EventCommandSignal" SG_ 969 ADC_APA_RPAFctUnavlMsg2 0;
BA_ "GatewayedSignals" SG_ 969 ADC_APA_RPAFctUnavlMsg2 0;
BA_ "GenSigInactiveValue" SG_ 969 ADC_APA_RPAFctUnavlMsg2 0;
BA_ "GenSigInvalidValue" SG_ 969 ADC_APA_RPAFctUnavlMsg2 0;
BA_ "GenSigSendType" SG_ 969 ADC_APA_RPAFctUnavlMsg2 1;
BA_ "GenSigStartValue" SG_ 969 ADC_APA_RPAFctUnavlMsg2 0;
BA_ "GenSigTimeoutValue" SG_ 969 ADC_APA_RPAFctUnavlMsg2 0;
BA_ "Remark" SG_ 969 ADC_APA_RPAFctUnavlMsg2 "";
BA_ "EventCommandSignal" SG_ 969 ADC_APA_RPAFctUnavlMsg3 0;
BA_ "GatewayedSignals" SG_ 969 ADC_APA_RPAFctUnavlMsg3 0;
BA_ "GenSigInactiveValue" SG_ 969 ADC_APA_RPAFctUnavlMsg3 0;
BA_ "GenSigInvalidValue" SG_ 969 ADC_APA_RPAFctUnavlMsg3 0;
BA_ "GenSigSendType" SG_ 969 ADC_APA_RPAFctUnavlMsg3 1;
BA_ "GenSigStartValue" SG_ 969 ADC_APA_RPAFctUnavlMsg3 0;
BA_ "GenSigTimeoutValue" SG_ 969 ADC_APA_RPAFctUnavlMsg3 0;
BA_ "Remark" SG_ 969 ADC_APA_RPAFctUnavlMsg3 "";
BA_ "EventCommandSignal" SG_ 969 ADC_APA_RPAFctUnavlMsg4 0;
BA_ "GatewayedSignals" SG_ 969 ADC_APA_RPAFctUnavlMsg4 0;
BA_ "GenSigInactiveValue" SG_ 969 ADC_APA_RPAFctUnavlMsg4 0;
BA_ "GenSigInvalidValue" SG_ 969 ADC_APA_RPAFctUnavlMsg4 0;
BA_ "GenSigSendType" SG_ 969 ADC_APA_RPAFctUnavlMsg4 1;
BA_ "GenSigStartValue" SG_ 969 ADC_APA_RPAFctUnavlMsg4 0;
BA_ "GenSigTimeoutValue" SG_ 969 ADC_APA_RPAFctUnavlMsg4 0;
BA_ "Remark" SG_ 969 ADC_APA_RPAFctUnavlMsg4 "";
BA_ "EventCommandSignal" SG_ 969 ADC_APA_RPAFctUnavlMsg5 0;
BA_ "GatewayedSignals" SG_ 969 ADC_APA_RPAFctUnavlMsg5 0;
BA_ "GenSigInactiveValue" SG_ 969 ADC_APA_RPAFctUnavlMsg5 0;
BA_ "GenSigInvalidValue" SG_ 969 ADC_APA_RPAFctUnavlMsg5 0;
BA_ "GenSigSendType" SG_ 969 ADC_APA_RPAFctUnavlMsg5 1;
BA_ "GenSigStartValue" SG_ 969 ADC_APA_RPAFctUnavlMsg5 0;
BA_ "GenSigTimeoutValue" SG_ 969 ADC_APA_RPAFctUnavlMsg5 0;
BA_ "Remark" SG_ 969 ADC_APA_RPAFctUnavlMsg5 "";
BA_ "EventCommandSignal" SG_ 969 ADC_APA_RPAFctUnavlMsg6 0;
BA_ "GatewayedSignals" SG_ 969 ADC_APA_RPAFctUnavlMsg6 0;
BA_ "GenSigInactiveValue" SG_ 969 ADC_APA_RPAFctUnavlMsg6 0;
BA_ "GenSigInvalidValue" SG_ 969 ADC_APA_RPAFctUnavlMsg6 0;
BA_ "GenSigSendType" SG_ 969 ADC_APA_RPAFctUnavlMsg6 1;
BA_ "GenSigStartValue" SG_ 969 ADC_APA_RPAFctUnavlMsg6 0;
BA_ "GenSigTimeoutValue" SG_ 969 ADC_APA_RPAFctUnavlMsg6 0;
BA_ "Remark" SG_ 969 ADC_APA_RPAFctUnavlMsg6 "";
BA_ "EventCommandSignal" SG_ 969 ADC_APA_RPAFctUnavlMsg7 0;
BA_ "GatewayedSignals" SG_ 969 ADC_APA_RPAFctUnavlMsg7 0;
BA_ "GenSigInactiveValue" SG_ 969 ADC_APA_RPAFctUnavlMsg7 0;
BA_ "GenSigInvalidValue" SG_ 969 ADC_APA_RPAFctUnavlMsg7 0;
BA_ "GenSigSendType" SG_ 969 ADC_APA_RPAFctUnavlMsg7 1;
BA_ "GenSigStartValue" SG_ 969 ADC_APA_RPAFctUnavlMsg7 0;
BA_ "GenSigTimeoutValue" SG_ 969 ADC_APA_RPAFctUnavlMsg7 0;
BA_ "Remark" SG_ 969 ADC_APA_RPAFctUnavlMsg7 "";
BA_ "EventCommandSignal" SG_ 969 ADC_APA_RPAFctUnavlMsg8 0;
BA_ "GatewayedSignals" SG_ 969 ADC_APA_RPAFctUnavlMsg8 0;
BA_ "GenSigInactiveValue" SG_ 969 ADC_APA_RPAFctUnavlMsg8 0;
BA_ "GenSigInvalidValue" SG_ 969 ADC_APA_RPAFctUnavlMsg8 0;
BA_ "GenSigSendType" SG_ 969 ADC_APA_RPAFctUnavlMsg8 1;
BA_ "GenSigStartValue" SG_ 969 ADC_APA_RPAFctUnavlMsg8 0;
BA_ "GenSigTimeoutValue" SG_ 969 ADC_APA_RPAFctUnavlMsg8 0;
BA_ "Remark" SG_ 969 ADC_APA_RPAFctUnavlMsg8 "";
BA_ "EventCommandSignal" SG_ 969 ADC_APA_RPAFctUnavlMsg9 0;
BA_ "GatewayedSignals" SG_ 969 ADC_APA_RPAFctUnavlMsg9 0;
BA_ "GenSigInactiveValue" SG_ 969 ADC_APA_RPAFctUnavlMsg9 0;
BA_ "GenSigInvalidValue" SG_ 969 ADC_APA_RPAFctUnavlMsg9 0;
BA_ "GenSigSendType" SG_ 969 ADC_APA_RPAFctUnavlMsg9 1;
BA_ "GenSigStartValue" SG_ 969 ADC_APA_RPAFctUnavlMsg9 0;
BA_ "GenSigTimeoutValue" SG_ 969 ADC_APA_RPAFctUnavlMsg9 0;
BA_ "Remark" SG_ 969 ADC_APA_RPAFctUnavlMsg9 "";
BA_ "EventCommandSignal" SG_ 969 ADC_APA_RPAFctUnavlMsg10 0;
BA_ "GatewayedSignals" SG_ 969 ADC_APA_RPAFctUnavlMsg10 0;
BA_ "GenSigInactiveValue" SG_ 969 ADC_APA_RPAFctUnavlMsg10 0;
BA_ "GenSigInvalidValue" SG_ 969 ADC_APA_RPAFctUnavlMsg10 0;
BA_ "GenSigSendType" SG_ 969 ADC_APA_RPAFctUnavlMsg10 1;
BA_ "GenSigStartValue" SG_ 969 ADC_APA_RPAFctUnavlMsg10 0;
BA_ "GenSigTimeoutValue" SG_ 969 ADC_APA_RPAFctUnavlMsg10 0;
BA_ "Remark" SG_ 969 ADC_APA_RPAFctUnavlMsg10 "";
BA_ "EventCommandSignal" SG_ 969 ADC_APA_RPAFctUnavlMsg11 0;
BA_ "GatewayedSignals" SG_ 969 ADC_APA_RPAFctUnavlMsg11 0;
BA_ "GenSigInactiveValue" SG_ 969 ADC_APA_RPAFctUnavlMsg11 0;
BA_ "GenSigInvalidValue" SG_ 969 ADC_APA_RPAFctUnavlMsg11 0;
BA_ "GenSigSendType" SG_ 969 ADC_APA_RPAFctUnavlMsg11 1;
BA_ "GenSigStartValue" SG_ 969 ADC_APA_RPAFctUnavlMsg11 0;
BA_ "GenSigTimeoutValue" SG_ 969 ADC_APA_RPAFctUnavlMsg11 0;
BA_ "Remark" SG_ 969 ADC_APA_RPAFctUnavlMsg11 "";
BA_ "EventCommandSignal" SG_ 969 ADC_APA_RPAFctUnavlMsg12 0;
BA_ "GatewayedSignals" SG_ 969 ADC_APA_RPAFctUnavlMsg12 0;
BA_ "GenSigInactiveValue" SG_ 969 ADC_APA_RPAFctUnavlMsg12 0;
BA_ "GenSigInvalidValue" SG_ 969 ADC_APA_RPAFctUnavlMsg12 0;
BA_ "GenSigSendType" SG_ 969 ADC_APA_RPAFctUnavlMsg12 1;
BA_ "GenSigStartValue" SG_ 969 ADC_APA_RPAFctUnavlMsg12 0;
BA_ "GenSigTimeoutValue" SG_ 969 ADC_APA_RPAFctUnavlMsg12 0;
BA_ "Remark" SG_ 969 ADC_APA_RPAFctUnavlMsg12 "";
BA_ "EventCommandSignal" SG_ 969 ADC_APA_RPAFctUnavlMsg13 0;
BA_ "GatewayedSignals" SG_ 969 ADC_APA_RPAFctUnavlMsg13 0;
BA_ "GenSigInactiveValue" SG_ 969 ADC_APA_RPAFctUnavlMsg13 0;
BA_ "GenSigInvalidValue" SG_ 969 ADC_APA_RPAFctUnavlMsg13 0;
BA_ "GenSigSendType" SG_ 969 ADC_APA_RPAFctUnavlMsg13 1;
BA_ "GenSigStartValue" SG_ 969 ADC_APA_RPAFctUnavlMsg13 0;
BA_ "GenSigTimeoutValue" SG_ 969 ADC_APA_RPAFctUnavlMsg13 0;
BA_ "Remark" SG_ 969 ADC_APA_RPAFctUnavlMsg13 "";
BA_ "EventCommandSignal" SG_ 969 ADC_APA_RPAFctUnavlMsg14 0;
BA_ "GatewayedSignals" SG_ 969 ADC_APA_RPAFctUnavlMsg14 0;
BA_ "GenSigInactiveValue" SG_ 969 ADC_APA_RPAFctUnavlMsg14 0;
BA_ "GenSigInvalidValue" SG_ 969 ADC_APA_RPAFctUnavlMsg14 0;
BA_ "GenSigSendType" SG_ 969 ADC_APA_RPAFctUnavlMsg14 1;
BA_ "GenSigStartValue" SG_ 969 ADC_APA_RPAFctUnavlMsg14 0;
BA_ "GenSigTimeoutValue" SG_ 969 ADC_APA_RPAFctUnavlMsg14 0;
BA_ "Remark" SG_ 969 ADC_APA_RPAFctUnavlMsg14 "";
BA_ "EventCommandSignal" SG_ 969 ADC_APA_RPAFctUnavlMsg15 0;
BA_ "GatewayedSignals" SG_ 969 ADC_APA_RPAFctUnavlMsg15 0;
BA_ "GenSigInactiveValue" SG_ 969 ADC_APA_RPAFctUnavlMsg15 0;
BA_ "GenSigInvalidValue" SG_ 969 ADC_APA_RPAFctUnavlMsg15 0;
BA_ "GenSigSendType" SG_ 969 ADC_APA_RPAFctUnavlMsg15 1;
BA_ "GenSigStartValue" SG_ 969 ADC_APA_RPAFctUnavlMsg15 0;
BA_ "GenSigTimeoutValue" SG_ 969 ADC_APA_RPAFctUnavlMsg15 0;
BA_ "Remark" SG_ 969 ADC_APA_RPAFctUnavlMsg15 "";
BA_ "EventCommandSignal" SG_ 969 ADC_APA_RPAFctUnavlMsg16 0;
BA_ "GatewayedSignals" SG_ 969 ADC_APA_RPAFctUnavlMsg16 0;
BA_ "GenSigInactiveValue" SG_ 969 ADC_APA_RPAFctUnavlMsg16 0;
BA_ "GenSigInvalidValue" SG_ 969 ADC_APA_RPAFctUnavlMsg16 0;
BA_ "GenSigSendType" SG_ 969 ADC_APA_RPAFctUnavlMsg16 1;
BA_ "GenSigStartValue" SG_ 969 ADC_APA_RPAFctUnavlMsg16 0;
BA_ "GenSigTimeoutValue" SG_ 969 ADC_APA_RPAFctUnavlMsg16 0;
BA_ "Remark" SG_ 969 ADC_APA_RPAFctUnavlMsg16 "";
BA_ "EventCommandSignal" SG_ 969 ADC_APA_RPAFctUnavlMsg17 0;
BA_ "GatewayedSignals" SG_ 969 ADC_APA_RPAFctUnavlMsg17 0;
BA_ "GenSigInactiveValue" SG_ 969 ADC_APA_RPAFctUnavlMsg17 0;
BA_ "GenSigInvalidValue" SG_ 969 ADC_APA_RPAFctUnavlMsg17 0;
BA_ "GenSigSendType" SG_ 969 ADC_APA_RPAFctUnavlMsg17 1;
BA_ "GenSigStartValue" SG_ 969 ADC_APA_RPAFctUnavlMsg17 0;
BA_ "GenSigTimeoutValue" SG_ 969 ADC_APA_RPAFctUnavlMsg17 0;
BA_ "Remark" SG_ 969 ADC_APA_RPAFctUnavlMsg17 "";
BA_ "EventCommandSignal" SG_ 969 ADC_APA_RPAFctUnavlMsg18 0;
BA_ "GatewayedSignals" SG_ 969 ADC_APA_RPAFctUnavlMsg18 0;
BA_ "GenSigInactiveValue" SG_ 969 ADC_APA_RPAFctUnavlMsg18 0;
BA_ "GenSigInvalidValue" SG_ 969 ADC_APA_RPAFctUnavlMsg18 0;
BA_ "GenSigSendType" SG_ 969 ADC_APA_RPAFctUnavlMsg18 1;
BA_ "GenSigStartValue" SG_ 969 ADC_APA_RPAFctUnavlMsg18 0;
BA_ "GenSigTimeoutValue" SG_ 969 ADC_APA_RPAFctUnavlMsg18 0;
BA_ "Remark" SG_ 969 ADC_APA_RPAFctUnavlMsg18 "";
BA_ "EventCommandSignal" SG_ 969 ADC_APA_RPAFctUnavlMsg19 0;
BA_ "GatewayedSignals" SG_ 969 ADC_APA_RPAFctUnavlMsg19 0;
BA_ "GenSigInactiveValue" SG_ 969 ADC_APA_RPAFctUnavlMsg19 0;
BA_ "GenSigInvalidValue" SG_ 969 ADC_APA_RPAFctUnavlMsg19 0;
BA_ "GenSigSendType" SG_ 969 ADC_APA_RPAFctUnavlMsg19 1;
BA_ "GenSigStartValue" SG_ 969 ADC_APA_RPAFctUnavlMsg19 0;
BA_ "GenSigTimeoutValue" SG_ 969 ADC_APA_RPAFctUnavlMsg19 0;
BA_ "Remark" SG_ 969 ADC_APA_RPAFctUnavlMsg19 "";
BA_ "EventCommandSignal" SG_ 969 ADC_APA_RPAFctUnavlMsg20 0;
BA_ "GatewayedSignals" SG_ 969 ADC_APA_RPAFctUnavlMsg20 0;
BA_ "GenSigInactiveValue" SG_ 969 ADC_APA_RPAFctUnavlMsg20 0;
BA_ "GenSigInvalidValue" SG_ 969 ADC_APA_RPAFctUnavlMsg20 0;
BA_ "GenSigSendType" SG_ 969 ADC_APA_RPAFctUnavlMsg20 1;
BA_ "GenSigStartValue" SG_ 969 ADC_APA_RPAFctUnavlMsg20 0;
BA_ "GenSigTimeoutValue" SG_ 969 ADC_APA_RPAFctUnavlMsg20 0;
BA_ "Remark" SG_ 969 ADC_APA_RPAFctUnavlMsg20 "";
BA_ "EventCommandSignal" SG_ 969 ADC_APA_RPAFctUnavlMsg21 0;
BA_ "GatewayedSignals" SG_ 969 ADC_APA_RPAFctUnavlMsg21 0;
BA_ "GenSigInactiveValue" SG_ 969 ADC_APA_RPAFctUnavlMsg21 0;
BA_ "GenSigInvalidValue" SG_ 969 ADC_APA_RPAFctUnavlMsg21 0;
BA_ "GenSigSendType" SG_ 969 ADC_APA_RPAFctUnavlMsg21 1;
BA_ "GenSigStartValue" SG_ 969 ADC_APA_RPAFctUnavlMsg21 0;
BA_ "GenSigTimeoutValue" SG_ 969 ADC_APA_RPAFctUnavlMsg21 0;
BA_ "Remark" SG_ 969 ADC_APA_RPAFctUnavlMsg21 "";
BA_ "EventCommandSignal" SG_ 969 ADC_APA_RPAFctUnavlMsg22 0;
BA_ "GatewayedSignals" SG_ 969 ADC_APA_RPAFctUnavlMsg22 0;
BA_ "GenSigInactiveValue" SG_ 969 ADC_APA_RPAFctUnavlMsg22 0;
BA_ "GenSigInvalidValue" SG_ 969 ADC_APA_RPAFctUnavlMsg22 0;
BA_ "GenSigSendType" SG_ 969 ADC_APA_RPAFctUnavlMsg22 1;
BA_ "GenSigStartValue" SG_ 969 ADC_APA_RPAFctUnavlMsg22 0;
BA_ "GenSigTimeoutValue" SG_ 969 ADC_APA_RPAFctUnavlMsg22 0;
BA_ "Remark" SG_ 969 ADC_APA_RPAFctUnavlMsg22 "";
BA_ "EventCommandSignal" SG_ 969 ADC_APA_RPAFctUnavlMsg23 0;
BA_ "GatewayedSignals" SG_ 969 ADC_APA_RPAFctUnavlMsg23 0;
BA_ "GenSigInactiveValue" SG_ 969 ADC_APA_RPAFctUnavlMsg23 0;
BA_ "GenSigInvalidValue" SG_ 969 ADC_APA_RPAFctUnavlMsg23 0;
BA_ "GenSigSendType" SG_ 969 ADC_APA_RPAFctUnavlMsg23 1;
BA_ "GenSigStartValue" SG_ 969 ADC_APA_RPAFctUnavlMsg23 0;
BA_ "GenSigTimeoutValue" SG_ 969 ADC_APA_RPAFctUnavlMsg23 0;
BA_ "Remark" SG_ 969 ADC_APA_RPAFctUnavlMsg23 "";
BA_ "EventCommandSignal" SG_ 969 ADC_APA_RPAFctUnavlMsg24 0;
BA_ "GatewayedSignals" SG_ 969 ADC_APA_RPAFctUnavlMsg24 0;
BA_ "GenSigInactiveValue" SG_ 969 ADC_APA_RPAFctUnavlMsg24 0;
BA_ "GenSigInvalidValue" SG_ 969 ADC_APA_RPAFctUnavlMsg24 0;
BA_ "GenSigSendType" SG_ 969 ADC_APA_RPAFctUnavlMsg24 1;
BA_ "GenSigStartValue" SG_ 969 ADC_APA_RPAFctUnavlMsg24 0;
BA_ "GenSigTimeoutValue" SG_ 969 ADC_APA_RPAFctUnavlMsg24 0;
BA_ "Remark" SG_ 969 ADC_APA_RPAFctUnavlMsg24 "";
BA_ "EventCommandSignal" SG_ 969 ADC_APA_RPAFctUnavlMsg25 0;
BA_ "GatewayedSignals" SG_ 969 ADC_APA_RPAFctUnavlMsg25 0;
BA_ "GenSigInactiveValue" SG_ 969 ADC_APA_RPAFctUnavlMsg25 0;
BA_ "GenSigInvalidValue" SG_ 969 ADC_APA_RPAFctUnavlMsg25 0;
BA_ "GenSigSendType" SG_ 969 ADC_APA_RPAFctUnavlMsg25 1;
BA_ "GenSigStartValue" SG_ 969 ADC_APA_RPAFctUnavlMsg25 0;
BA_ "GenSigTimeoutValue" SG_ 969 ADC_APA_RPAFctUnavlMsg25 0;
BA_ "Remark" SG_ 969 ADC_APA_RPAFctUnavlMsg25 "";
BA_ "EventCommandSignal" SG_ 969 ADC_APA_RPACnclMsg1 0;
BA_ "GatewayedSignals" SG_ 969 ADC_APA_RPACnclMsg1 0;
BA_ "GenSigInactiveValue" SG_ 969 ADC_APA_RPACnclMsg1 0;
BA_ "GenSigInvalidValue" SG_ 969 ADC_APA_RPACnclMsg1 0;
BA_ "GenSigSendType" SG_ 969 ADC_APA_RPACnclMsg1 1;
BA_ "GenSigStartValue" SG_ 969 ADC_APA_RPACnclMsg1 0;
BA_ "GenSigTimeoutValue" SG_ 969 ADC_APA_RPACnclMsg1 0;
BA_ "Remark" SG_ 969 ADC_APA_RPACnclMsg1 "";
BA_ "EventCommandSignal" SG_ 969 ADC_APA_RPACnclMsg2 0;
BA_ "GatewayedSignals" SG_ 969 ADC_APA_RPACnclMsg2 0;
BA_ "GenSigInactiveValue" SG_ 969 ADC_APA_RPACnclMsg2 0;
BA_ "GenSigInvalidValue" SG_ 969 ADC_APA_RPACnclMsg2 0;
BA_ "GenSigSendType" SG_ 969 ADC_APA_RPACnclMsg2 1;
BA_ "GenSigStartValue" SG_ 969 ADC_APA_RPACnclMsg2 0;
BA_ "GenSigTimeoutValue" SG_ 969 ADC_APA_RPACnclMsg2 0;
BA_ "Remark" SG_ 969 ADC_APA_RPACnclMsg2 "";
BA_ "EventCommandSignal" SG_ 969 ADC_APA_RPACnclMsg3 0;
BA_ "GatewayedSignals" SG_ 969 ADC_APA_RPACnclMsg3 0;
BA_ "GenSigInactiveValue" SG_ 969 ADC_APA_RPACnclMsg3 0;
BA_ "GenSigInvalidValue" SG_ 969 ADC_APA_RPACnclMsg3 0;
BA_ "GenSigSendType" SG_ 969 ADC_APA_RPACnclMsg3 1;
BA_ "GenSigStartValue" SG_ 969 ADC_APA_RPACnclMsg3 0;
BA_ "GenSigTimeoutValue" SG_ 969 ADC_APA_RPACnclMsg3 0;
BA_ "Remark" SG_ 969 ADC_APA_RPACnclMsg3 "";
BA_ "EventCommandSignal" SG_ 969 ADC_APA_RPACnclMsg4 0;
BA_ "GatewayedSignals" SG_ 969 ADC_APA_RPACnclMsg4 0;
BA_ "GenSigInactiveValue" SG_ 969 ADC_APA_RPACnclMsg4 0;
BA_ "GenSigInvalidValue" SG_ 969 ADC_APA_RPACnclMsg4 0;
BA_ "GenSigSendType" SG_ 969 ADC_APA_RPACnclMsg4 1;
BA_ "GenSigStartValue" SG_ 969 ADC_APA_RPACnclMsg4 0;
BA_ "GenSigTimeoutValue" SG_ 969 ADC_APA_RPACnclMsg4 0;
BA_ "Remark" SG_ 969 ADC_APA_RPACnclMsg4 "";
BA_ "EventCommandSignal" SG_ 969 ADC_APA_RPACnclMsg5 0;
BA_ "GatewayedSignals" SG_ 969 ADC_APA_RPACnclMsg5 0;
BA_ "GenSigInactiveValue" SG_ 969 ADC_APA_RPACnclMsg5 0;
BA_ "GenSigInvalidValue" SG_ 969 ADC_APA_RPACnclMsg5 0;
BA_ "GenSigSendType" SG_ 969 ADC_APA_RPACnclMsg5 1;
BA_ "GenSigStartValue" SG_ 969 ADC_APA_RPACnclMsg5 0;
BA_ "GenSigTimeoutValue" SG_ 969 ADC_APA_RPACnclMsg5 0;
BA_ "Remark" SG_ 969 ADC_APA_RPACnclMsg5 "";
BA_ "EventCommandSignal" SG_ 969 ADC_APA_RPACnclMsg6 0;
BA_ "GatewayedSignals" SG_ 969 ADC_APA_RPACnclMsg6 0;
BA_ "GenSigInactiveValue" SG_ 969 ADC_APA_RPACnclMsg6 0;
BA_ "GenSigInvalidValue" SG_ 969 ADC_APA_RPACnclMsg6 0;
BA_ "GenSigSendType" SG_ 969 ADC_APA_RPACnclMsg6 1;
BA_ "GenSigStartValue" SG_ 969 ADC_APA_RPACnclMsg6 0;
BA_ "GenSigTimeoutValue" SG_ 969 ADC_APA_RPACnclMsg6 0;
BA_ "Remark" SG_ 969 ADC_APA_RPACnclMsg6 "";
BA_ "EventCommandSignal" SG_ 969 ADC_APA_RPACnclMsg7 0;
BA_ "GatewayedSignals" SG_ 969 ADC_APA_RPACnclMsg7 0;
BA_ "GenSigInactiveValue" SG_ 969 ADC_APA_RPACnclMsg7 0;
BA_ "GenSigInvalidValue" SG_ 969 ADC_APA_RPACnclMsg7 0;
BA_ "GenSigSendType" SG_ 969 ADC_APA_RPACnclMsg7 1;
BA_ "GenSigStartValue" SG_ 969 ADC_APA_RPACnclMsg7 0;
BA_ "GenSigTimeoutValue" SG_ 969 ADC_APA_RPACnclMsg7 0;
BA_ "Remark" SG_ 969 ADC_APA_RPACnclMsg7 "";
BA_ "EventCommandSignal" SG_ 969 ADC_APA_RPACnclMsg8 0;
BA_ "GatewayedSignals" SG_ 969 ADC_APA_RPACnclMsg8 0;
BA_ "GenSigInactiveValue" SG_ 969 ADC_APA_RPACnclMsg8 0;
BA_ "GenSigInvalidValue" SG_ 969 ADC_APA_RPACnclMsg8 0;
BA_ "GenSigSendType" SG_ 969 ADC_APA_RPACnclMsg8 1;
BA_ "GenSigStartValue" SG_ 969 ADC_APA_RPACnclMsg8 0;
BA_ "GenSigTimeoutValue" SG_ 969 ADC_APA_RPACnclMsg8 0;
BA_ "Remark" SG_ 969 ADC_APA_RPACnclMsg8 "";
BA_ "EventCommandSignal" SG_ 969 ADC_APA_RPACnclMsg9 0;
BA_ "GatewayedSignals" SG_ 969 ADC_APA_RPACnclMsg9 0;
BA_ "GenSigInactiveValue" SG_ 969 ADC_APA_RPACnclMsg9 0;
BA_ "GenSigInvalidValue" SG_ 969 ADC_APA_RPACnclMsg9 0;
BA_ "GenSigSendType" SG_ 969 ADC_APA_RPACnclMsg9 1;
BA_ "GenSigStartValue" SG_ 969 ADC_APA_RPACnclMsg9 0;
BA_ "GenSigTimeoutValue" SG_ 969 ADC_APA_RPACnclMsg9 0;
BA_ "Remark" SG_ 969 ADC_APA_RPACnclMsg9 "";
BA_ "EventCommandSignal" SG_ 969 ADC_APA_RPACnclMsg10 0;
BA_ "GatewayedSignals" SG_ 969 ADC_APA_RPACnclMsg10 0;
BA_ "GenSigInactiveValue" SG_ 969 ADC_APA_RPACnclMsg10 0;
BA_ "GenSigInvalidValue" SG_ 969 ADC_APA_RPACnclMsg10 0;
BA_ "GenSigSendType" SG_ 969 ADC_APA_RPACnclMsg10 1;
BA_ "GenSigStartValue" SG_ 969 ADC_APA_RPACnclMsg10 0;
BA_ "GenSigTimeoutValue" SG_ 969 ADC_APA_RPACnclMsg10 0;
BA_ "Remark" SG_ 969 ADC_APA_RPACnclMsg10 "";
BA_ "EventCommandSignal" SG_ 969 ADC_APA_RPACnclMsg11 0;
BA_ "GatewayedSignals" SG_ 969 ADC_APA_RPACnclMsg11 0;
BA_ "GenSigInactiveValue" SG_ 969 ADC_APA_RPACnclMsg11 0;
BA_ "GenSigInvalidValue" SG_ 969 ADC_APA_RPACnclMsg11 0;
BA_ "GenSigSendType" SG_ 969 ADC_APA_RPACnclMsg11 1;
BA_ "GenSigStartValue" SG_ 969 ADC_APA_RPACnclMsg11 0;
BA_ "GenSigTimeoutValue" SG_ 969 ADC_APA_RPACnclMsg11 0;
BA_ "Remark" SG_ 969 ADC_APA_RPACnclMsg11 "";
BA_ "EventCommandSignal" SG_ 969 ADC_APA_RPACnclMsg12 0;
BA_ "GatewayedSignals" SG_ 969 ADC_APA_RPACnclMsg12 0;
BA_ "GenSigInactiveValue" SG_ 969 ADC_APA_RPACnclMsg12 0;
BA_ "GenSigInvalidValue" SG_ 969 ADC_APA_RPACnclMsg12 0;
BA_ "GenSigSendType" SG_ 969 ADC_APA_RPACnclMsg12 1;
BA_ "GenSigStartValue" SG_ 969 ADC_APA_RPACnclMsg12 0;
BA_ "GenSigTimeoutValue" SG_ 969 ADC_APA_RPACnclMsg12 0;
BA_ "Remark" SG_ 969 ADC_APA_RPACnclMsg12 "";
BA_ "EventCommandSignal" SG_ 969 ADC_APA_RPACnclMsg13 0;
BA_ "GatewayedSignals" SG_ 969 ADC_APA_RPACnclMsg13 0;
BA_ "GenSigInactiveValue" SG_ 969 ADC_APA_RPACnclMsg13 0;
BA_ "GenSigInvalidValue" SG_ 969 ADC_APA_RPACnclMsg13 0;
BA_ "GenSigSendType" SG_ 969 ADC_APA_RPACnclMsg13 1;
BA_ "GenSigStartValue" SG_ 969 ADC_APA_RPACnclMsg13 0;
BA_ "GenSigTimeoutValue" SG_ 969 ADC_APA_RPACnclMsg13 0;
BA_ "Remark" SG_ 969 ADC_APA_RPACnclMsg13 "";
BA_ "EventCommandSignal" SG_ 969 ADC_APA_RPACnclMsg14 0;
BA_ "GatewayedSignals" SG_ 969 ADC_APA_RPACnclMsg14 0;
BA_ "GenSigInactiveValue" SG_ 969 ADC_APA_RPACnclMsg14 0;
BA_ "GenSigInvalidValue" SG_ 969 ADC_APA_RPACnclMsg14 0;
BA_ "GenSigSendType" SG_ 969 ADC_APA_RPACnclMsg14 1;
BA_ "GenSigStartValue" SG_ 969 ADC_APA_RPACnclMsg14 0;
BA_ "GenSigTimeoutValue" SG_ 969 ADC_APA_RPACnclMsg14 0;
BA_ "Remark" SG_ 969 ADC_APA_RPACnclMsg14 "";
BA_ "EventCommandSignal" SG_ 969 ADC_APA_RPACnclMsg15 0;
BA_ "GatewayedSignals" SG_ 969 ADC_APA_RPACnclMsg15 0;
BA_ "GenSigInactiveValue" SG_ 969 ADC_APA_RPACnclMsg15 0;
BA_ "GenSigInvalidValue" SG_ 969 ADC_APA_RPACnclMsg15 0;
BA_ "GenSigSendType" SG_ 969 ADC_APA_RPACnclMsg15 1;
BA_ "GenSigStartValue" SG_ 969 ADC_APA_RPACnclMsg15 0;
BA_ "GenSigTimeoutValue" SG_ 969 ADC_APA_RPACnclMsg15 0;
BA_ "Remark" SG_ 969 ADC_APA_RPACnclMsg15 "";
BA_ "EventCommandSignal" SG_ 969 ADC_APA_RPACnclMsg16 0;
BA_ "GatewayedSignals" SG_ 969 ADC_APA_RPACnclMsg16 0;
BA_ "GenSigInactiveValue" SG_ 969 ADC_APA_RPACnclMsg16 0;
BA_ "GenSigInvalidValue" SG_ 969 ADC_APA_RPACnclMsg16 0;
BA_ "GenSigSendType" SG_ 969 ADC_APA_RPACnclMsg16 1;
BA_ "GenSigStartValue" SG_ 969 ADC_APA_RPACnclMsg16 0;
BA_ "GenSigTimeoutValue" SG_ 969 ADC_APA_RPACnclMsg16 0;
BA_ "Remark" SG_ 969 ADC_APA_RPACnclMsg16 "";
BA_ "EventCommandSignal" SG_ 969 ADC_APA_RPACnclMsg17 0;
BA_ "GatewayedSignals" SG_ 969 ADC_APA_RPACnclMsg17 0;
BA_ "GenSigInactiveValue" SG_ 969 ADC_APA_RPACnclMsg17 0;
BA_ "GenSigInvalidValue" SG_ 969 ADC_APA_RPACnclMsg17 0;
BA_ "GenSigSendType" SG_ 969 ADC_APA_RPACnclMsg17 1;
BA_ "GenSigStartValue" SG_ 969 ADC_APA_RPACnclMsg17 0;
BA_ "GenSigTimeoutValue" SG_ 969 ADC_APA_RPACnclMsg17 0;
BA_ "Remark" SG_ 969 ADC_APA_RPACnclMsg17 "";
BA_ "EventCommandSignal" SG_ 969 ADC_APA_RPACnclMsg18 0;
BA_ "GatewayedSignals" SG_ 969 ADC_APA_RPACnclMsg18 0;
BA_ "GenSigInactiveValue" SG_ 969 ADC_APA_RPACnclMsg18 0;
BA_ "GenSigInvalidValue" SG_ 969 ADC_APA_RPACnclMsg18 0;
BA_ "GenSigSendType" SG_ 969 ADC_APA_RPACnclMsg18 1;
BA_ "GenSigStartValue" SG_ 969 ADC_APA_RPACnclMsg18 0;
BA_ "GenSigTimeoutValue" SG_ 969 ADC_APA_RPACnclMsg18 0;
BA_ "Remark" SG_ 969 ADC_APA_RPACnclMsg18 "";
BA_ "EventCommandSignal" SG_ 969 ADC_APA_RPACnclMsg19 0;
BA_ "GatewayedSignals" SG_ 969 ADC_APA_RPACnclMsg19 0;
BA_ "GenSigInactiveValue" SG_ 969 ADC_APA_RPACnclMsg19 0;
BA_ "GenSigInvalidValue" SG_ 969 ADC_APA_RPACnclMsg19 0;
BA_ "GenSigSendType" SG_ 969 ADC_APA_RPACnclMsg19 1;
BA_ "GenSigStartValue" SG_ 969 ADC_APA_RPACnclMsg19 0;
BA_ "GenSigTimeoutValue" SG_ 969 ADC_APA_RPACnclMsg19 0;
BA_ "Remark" SG_ 969 ADC_APA_RPACnclMsg19 "";
BA_ "EventCommandSignal" SG_ 969 ADC_APA_RPACnclMsg20 0;
BA_ "GatewayedSignals" SG_ 969 ADC_APA_RPACnclMsg20 0;
BA_ "GenSigInactiveValue" SG_ 969 ADC_APA_RPACnclMsg20 0;
BA_ "GenSigInvalidValue" SG_ 969 ADC_APA_RPACnclMsg20 0;
BA_ "GenSigSendType" SG_ 969 ADC_APA_RPACnclMsg20 1;
BA_ "GenSigStartValue" SG_ 969 ADC_APA_RPACnclMsg20 0;
BA_ "GenSigTimeoutValue" SG_ 969 ADC_APA_RPACnclMsg20 0;
BA_ "Remark" SG_ 969 ADC_APA_RPACnclMsg20 "";
BA_ "EventCommandSignal" SG_ 969 ADC_APA_RPAPauseMsg1 0;
BA_ "GatewayedSignals" SG_ 969 ADC_APA_RPAPauseMsg1 0;
BA_ "GenSigInactiveValue" SG_ 969 ADC_APA_RPAPauseMsg1 0;
BA_ "GenSigInvalidValue" SG_ 969 ADC_APA_RPAPauseMsg1 0;
BA_ "GenSigSendType" SG_ 969 ADC_APA_RPAPauseMsg1 1;
BA_ "GenSigStartValue" SG_ 969 ADC_APA_RPAPauseMsg1 0;
BA_ "GenSigTimeoutValue" SG_ 969 ADC_APA_RPAPauseMsg1 0;
BA_ "Remark" SG_ 969 ADC_APA_RPAPauseMsg1 "";
BA_ "EventCommandSignal" SG_ 969 ADC_APA_RPAPauseMsg2 0;
BA_ "GatewayedSignals" SG_ 969 ADC_APA_RPAPauseMsg2 0;
BA_ "GenSigInactiveValue" SG_ 969 ADC_APA_RPAPauseMsg2 0;
BA_ "GenSigInvalidValue" SG_ 969 ADC_APA_RPAPauseMsg2 0;
BA_ "GenSigSendType" SG_ 969 ADC_APA_RPAPauseMsg2 1;
BA_ "GenSigStartValue" SG_ 969 ADC_APA_RPAPauseMsg2 0;
BA_ "GenSigTimeoutValue" SG_ 969 ADC_APA_RPAPauseMsg2 0;
BA_ "Remark" SG_ 969 ADC_APA_RPAPauseMsg2 "";
BA_ "EventCommandSignal" SG_ 969 ADC_APA_RPAPauseMsg3 0;
BA_ "GatewayedSignals" SG_ 969 ADC_APA_RPAPauseMsg3 0;
BA_ "GenSigInactiveValue" SG_ 969 ADC_APA_RPAPauseMsg3 0;
BA_ "GenSigInvalidValue" SG_ 969 ADC_APA_RPAPauseMsg3 0;
BA_ "GenSigSendType" SG_ 969 ADC_APA_RPAPauseMsg3 1;
BA_ "GenSigStartValue" SG_ 969 ADC_APA_RPAPauseMsg3 0;
BA_ "GenSigTimeoutValue" SG_ 969 ADC_APA_RPAPauseMsg3 0;
BA_ "Remark" SG_ 969 ADC_APA_RPAPauseMsg3 "";
BA_ "EventCommandSignal" SG_ 969 ADC_APA_RPAPauseMsg4 0;
BA_ "GatewayedSignals" SG_ 969 ADC_APA_RPAPauseMsg4 0;
BA_ "GenSigInactiveValue" SG_ 969 ADC_APA_RPAPauseMsg4 0;
BA_ "GenSigInvalidValue" SG_ 969 ADC_APA_RPAPauseMsg4 0;
BA_ "GenSigSendType" SG_ 969 ADC_APA_RPAPauseMsg4 1;
BA_ "GenSigStartValue" SG_ 969 ADC_APA_RPAPauseMsg4 0;
BA_ "GenSigTimeoutValue" SG_ 969 ADC_APA_RPAPauseMsg4 0;
BA_ "Remark" SG_ 969 ADC_APA_RPAPauseMsg4 "";
BA_ "EventCommandSignal" SG_ 969 ADC_APA_RPAPauseMsg5 0;
BA_ "GatewayedSignals" SG_ 969 ADC_APA_RPAPauseMsg5 0;
BA_ "GenSigInactiveValue" SG_ 969 ADC_APA_RPAPauseMsg5 0;
BA_ "GenSigInvalidValue" SG_ 969 ADC_APA_RPAPauseMsg5 0;
BA_ "GenSigSendType" SG_ 969 ADC_APA_RPAPauseMsg5 1;
BA_ "GenSigStartValue" SG_ 969 ADC_APA_RPAPauseMsg5 0;
BA_ "GenSigTimeoutValue" SG_ 969 ADC_APA_RPAPauseMsg5 0;
BA_ "Remark" SG_ 969 ADC_APA_RPAPauseMsg5 "";
BA_ "EventCommandSignal" SG_ 969 ADC_APA_RPAPauseMsg6 0;
BA_ "GatewayedSignals" SG_ 969 ADC_APA_RPAPauseMsg6 0;
BA_ "GenSigInactiveValue" SG_ 969 ADC_APA_RPAPauseMsg6 0;
BA_ "GenSigInvalidValue" SG_ 969 ADC_APA_RPAPauseMsg6 0;
BA_ "GenSigSendType" SG_ 969 ADC_APA_RPAPauseMsg6 1;
BA_ "GenSigStartValue" SG_ 969 ADC_APA_RPAPauseMsg6 0;
BA_ "GenSigTimeoutValue" SG_ 969 ADC_APA_RPAPauseMsg6 0;
BA_ "Remark" SG_ 969 ADC_APA_RPAPauseMsg6 "";
BA_ "EventCommandSignal" SG_ 969 ADC_APA_RPAPauseMsg7 0;
BA_ "GatewayedSignals" SG_ 969 ADC_APA_RPAPauseMsg7 0;
BA_ "GenSigInactiveValue" SG_ 969 ADC_APA_RPAPauseMsg7 0;
BA_ "GenSigInvalidValue" SG_ 969 ADC_APA_RPAPauseMsg7 0;
BA_ "GenSigSendType" SG_ 969 ADC_APA_RPAPauseMsg7 1;
BA_ "GenSigStartValue" SG_ 969 ADC_APA_RPAPauseMsg7 0;
BA_ "GenSigTimeoutValue" SG_ 969 ADC_APA_RPAPauseMsg7 0;
BA_ "Remark" SG_ 969 ADC_APA_RPAPauseMsg7 "";
BA_ "EventCommandSignal" SG_ 969 ADC_APA_RPAPauseMsg8 0;
BA_ "GatewayedSignals" SG_ 969 ADC_APA_RPAPauseMsg8 0;
BA_ "GenSigInactiveValue" SG_ 969 ADC_APA_RPAPauseMsg8 0;
BA_ "GenSigInvalidValue" SG_ 969 ADC_APA_RPAPauseMsg8 0;
BA_ "GenSigSendType" SG_ 969 ADC_APA_RPAPauseMsg8 1;
BA_ "GenSigStartValue" SG_ 969 ADC_APA_RPAPauseMsg8 0;
BA_ "GenSigTimeoutValue" SG_ 969 ADC_APA_RPAPauseMsg8 0;
BA_ "Remark" SG_ 969 ADC_APA_RPAPauseMsg8 "";
BA_ "EventCommandSignal" SG_ 969 ADC_APA_RPAPauseMsg9 0;
BA_ "GatewayedSignals" SG_ 969 ADC_APA_RPAPauseMsg9 0;
BA_ "GenSigInactiveValue" SG_ 969 ADC_APA_RPAPauseMsg9 0;
BA_ "GenSigInvalidValue" SG_ 969 ADC_APA_RPAPauseMsg9 0;
BA_ "GenSigSendType" SG_ 969 ADC_APA_RPAPauseMsg9 1;
BA_ "GenSigStartValue" SG_ 969 ADC_APA_RPAPauseMsg9 0;
BA_ "GenSigTimeoutValue" SG_ 969 ADC_APA_RPAPauseMsg9 0;
BA_ "Remark" SG_ 969 ADC_APA_RPAPauseMsg9 "";
BA_ "EventCommandSignal" SG_ 969 ADC_APA_RPAPauseMsg10 0;
BA_ "GatewayedSignals" SG_ 969 ADC_APA_RPAPauseMsg10 0;
BA_ "GenSigInactiveValue" SG_ 969 ADC_APA_RPAPauseMsg10 0;
BA_ "GenSigInvalidValue" SG_ 969 ADC_APA_RPAPauseMsg10 0;
BA_ "GenSigSendType" SG_ 969 ADC_APA_RPAPauseMsg10 1;
BA_ "GenSigStartValue" SG_ 969 ADC_APA_RPAPauseMsg10 0;
BA_ "GenSigTimeoutValue" SG_ 969 ADC_APA_RPAPauseMsg10 0;
BA_ "Remark" SG_ 969 ADC_APA_RPAPauseMsg10 "";
BA_ "EventCommandSignal" SG_ 969 ADC_PathPlanPos1X 0;
BA_ "GatewayedSignals" SG_ 969 ADC_PathPlanPos1X 0;
BA_ "GenSigInactiveValue" SG_ 969 ADC_PathPlanPos1X 0;
BA_ "GenSigInvalidValue" SG_ 969 ADC_PathPlanPos1X 0;
BA_ "GenSigSendType" SG_ 969 ADC_PathPlanPos1X 1;
BA_ "GenSigStartValue" SG_ 969 ADC_PathPlanPos1X 0;
BA_ "GenSigTimeoutValue" SG_ 969 ADC_PathPlanPos1X 0;
BA_ "Remark" SG_ 969 ADC_PathPlanPos1X "";
BA_ "EventCommandSignal" SG_ 969 ADC_PathPlanPos1Y 0;
BA_ "GatewayedSignals" SG_ 969 ADC_PathPlanPos1Y 0;
BA_ "GenSigInactiveValue" SG_ 969 ADC_PathPlanPos1Y 0;
BA_ "GenSigInvalidValue" SG_ 969 ADC_PathPlanPos1Y 0;
BA_ "GenSigSendType" SG_ 969 ADC_PathPlanPos1Y 1;
BA_ "GenSigStartValue" SG_ 969 ADC_PathPlanPos1Y 0;
BA_ "GenSigTimeoutValue" SG_ 969 ADC_PathPlanPos1Y 0;
BA_ "Remark" SG_ 969 ADC_PathPlanPos1Y "";
BA_ "EventCommandSignal" SG_ 969 ADC_PathPlanPos2X 0;
BA_ "GatewayedSignals" SG_ 969 ADC_PathPlanPos2X 0;
BA_ "GenSigInactiveValue" SG_ 969 ADC_PathPlanPos2X 0;
BA_ "GenSigInvalidValue" SG_ 969 ADC_PathPlanPos2X 0;
BA_ "GenSigSendType" SG_ 969 ADC_PathPlanPos2X 1;
BA_ "GenSigStartValue" SG_ 969 ADC_PathPlanPos2X 0;
BA_ "GenSigTimeoutValue" SG_ 969 ADC_PathPlanPos2X 0;
BA_ "Remark" SG_ 969 ADC_PathPlanPos2X "";
BA_ "EventCommandSignal" SG_ 969 ADC_PathPlanPos2Y 0;
BA_ "GatewayedSignals" SG_ 969 ADC_PathPlanPos2Y 0;
BA_ "GenSigInactiveValue" SG_ 969 ADC_PathPlanPos2Y 0;
BA_ "GenSigInvalidValue" SG_ 969 ADC_PathPlanPos2Y 0;
BA_ "GenSigSendType" SG_ 969 ADC_PathPlanPos2Y 1;
BA_ "GenSigStartValue" SG_ 969 ADC_PathPlanPos2Y 0;
BA_ "GenSigTimeoutValue" SG_ 969 ADC_PathPlanPos2Y 0;
BA_ "Remark" SG_ 969 ADC_PathPlanPos2Y "";
BA_ "EventCommandSignal" SG_ 969 ADC_PathPlanPos3X 0;
BA_ "GatewayedSignals" SG_ 969 ADC_PathPlanPos3X 0;
BA_ "GenSigInactiveValue" SG_ 969 ADC_PathPlanPos3X 0;
BA_ "GenSigInvalidValue" SG_ 969 ADC_PathPlanPos3X 0;
BA_ "GenSigSendType" SG_ 969 ADC_PathPlanPos3X 1;
BA_ "GenSigStartValue" SG_ 969 ADC_PathPlanPos3X 0;
BA_ "GenSigTimeoutValue" SG_ 969 ADC_PathPlanPos3X 0;
BA_ "Remark" SG_ 969 ADC_PathPlanPos3X "";
BA_ "EventCommandSignal" SG_ 969 ADC_PathPlanPos3Y 0;
BA_ "GatewayedSignals" SG_ 969 ADC_PathPlanPos3Y 0;
BA_ "GenSigInactiveValue" SG_ 969 ADC_PathPlanPos3Y 0;
BA_ "GenSigInvalidValue" SG_ 969 ADC_PathPlanPos3Y 0;
BA_ "GenSigSendType" SG_ 969 ADC_PathPlanPos3Y 1;
BA_ "GenSigStartValue" SG_ 969 ADC_PathPlanPos3Y 0;
BA_ "GenSigTimeoutValue" SG_ 969 ADC_PathPlanPos3Y 0;
BA_ "Remark" SG_ 969 ADC_PathPlanPos3Y "";
BA_ "EventCommandSignal" SG_ 969 ADC_PathPlanPos4X 0;
BA_ "GatewayedSignals" SG_ 969 ADC_PathPlanPos4X 0;
BA_ "GenSigInactiveValue" SG_ 969 ADC_PathPlanPos4X 0;
BA_ "GenSigInvalidValue" SG_ 969 ADC_PathPlanPos4X 0;
BA_ "GenSigSendType" SG_ 969 ADC_PathPlanPos4X 1;
BA_ "GenSigStartValue" SG_ 969 ADC_PathPlanPos4X 0;
BA_ "GenSigTimeoutValue" SG_ 969 ADC_PathPlanPos4X 0;
BA_ "Remark" SG_ 969 ADC_PathPlanPos4X "";
BA_ "EventCommandSignal" SG_ 969 ADC_PathPlanPos4Y 0;
BA_ "GatewayedSignals" SG_ 969 ADC_PathPlanPos4Y 0;
BA_ "GenSigInactiveValue" SG_ 969 ADC_PathPlanPos4Y 0;
BA_ "GenSigInvalidValue" SG_ 969 ADC_PathPlanPos4Y 0;
BA_ "GenSigSendType" SG_ 969 ADC_PathPlanPos4Y 1;
BA_ "GenSigStartValue" SG_ 969 ADC_PathPlanPos4Y 0;
BA_ "GenSigTimeoutValue" SG_ 969 ADC_PathPlanPos4Y 0;
BA_ "Remark" SG_ 969 ADC_PathPlanPos4Y "";
BA_ "EventCommandSignal" SG_ 969 ADC_PathPlanPos5X 0;
BA_ "GatewayedSignals" SG_ 969 ADC_PathPlanPos5X 0;
BA_ "GenSigInactiveValue" SG_ 969 ADC_PathPlanPos5X 0;
BA_ "GenSigInvalidValue" SG_ 969 ADC_PathPlanPos5X 0;
BA_ "GenSigSendType" SG_ 969 ADC_PathPlanPos5X 1;
BA_ "GenSigStartValue" SG_ 969 ADC_PathPlanPos5X 0;
BA_ "GenSigTimeoutValue" SG_ 969 ADC_PathPlanPos5X 0;
BA_ "Remark" SG_ 969 ADC_PathPlanPos5X "";
BA_ "EventCommandSignal" SG_ 969 ADC_PathPlanPos5Y 0;
BA_ "GatewayedSignals" SG_ 969 ADC_PathPlanPos5Y 0;
BA_ "GenSigInactiveValue" SG_ 969 ADC_PathPlanPos5Y 0;
BA_ "GenSigInvalidValue" SG_ 969 ADC_PathPlanPos5Y 0;
BA_ "GenSigSendType" SG_ 969 ADC_PathPlanPos5Y 1;
BA_ "GenSigStartValue" SG_ 969 ADC_PathPlanPos5Y 0;
BA_ "GenSigTimeoutValue" SG_ 969 ADC_PathPlanPos5Y 0;
BA_ "Remark" SG_ 969 ADC_PathPlanPos5Y "";
BA_ "EventCommandSignal" SG_ 969 ADC_PathPlanPos6X 0;
BA_ "GatewayedSignals" SG_ 969 ADC_PathPlanPos6X 0;
BA_ "GenSigInactiveValue" SG_ 969 ADC_PathPlanPos6X 0;
BA_ "GenSigInvalidValue" SG_ 969 ADC_PathPlanPos6X 0;
BA_ "GenSigSendType" SG_ 969 ADC_PathPlanPos6X 1;
BA_ "GenSigStartValue" SG_ 969 ADC_PathPlanPos6X 0;
BA_ "GenSigTimeoutValue" SG_ 969 ADC_PathPlanPos6X 0;
BA_ "Remark" SG_ 969 ADC_PathPlanPos6X "";
BA_ "EventCommandSignal" SG_ 969 ADC_PathPlanPos6Y 0;
BA_ "GatewayedSignals" SG_ 969 ADC_PathPlanPos6Y 0;
BA_ "GenSigInactiveValue" SG_ 969 ADC_PathPlanPos6Y 0;
BA_ "GenSigInvalidValue" SG_ 969 ADC_PathPlanPos6Y 0;
BA_ "GenSigSendType" SG_ 969 ADC_PathPlanPos6Y 1;
BA_ "GenSigStartValue" SG_ 969 ADC_PathPlanPos6Y 0;
BA_ "GenSigTimeoutValue" SG_ 969 ADC_PathPlanPos6Y 0;
BA_ "Remark" SG_ 969 ADC_PathPlanPos6Y "";
BA_ "EventCommandSignal" SG_ 969 ADC_PathPlanPos7X 0;
BA_ "GatewayedSignals" SG_ 969 ADC_PathPlanPos7X 0;
BA_ "GenSigInactiveValue" SG_ 969 ADC_PathPlanPos7X 0;
BA_ "GenSigInvalidValue" SG_ 969 ADC_PathPlanPos7X 0;
BA_ "GenSigSendType" SG_ 969 ADC_PathPlanPos7X 1;
BA_ "GenSigStartValue" SG_ 969 ADC_PathPlanPos7X 0;
BA_ "GenSigTimeoutValue" SG_ 969 ADC_PathPlanPos7X 0;
BA_ "Remark" SG_ 969 ADC_PathPlanPos7X "";
BA_ "EventCommandSignal" SG_ 969 ADC_PathPlanPos7Y 0;
BA_ "GatewayedSignals" SG_ 969 ADC_PathPlanPos7Y 0;
BA_ "GenSigInactiveValue" SG_ 969 ADC_PathPlanPos7Y 0;
BA_ "GenSigInvalidValue" SG_ 969 ADC_PathPlanPos7Y 0;
BA_ "GenSigSendType" SG_ 969 ADC_PathPlanPos7Y 1;
BA_ "GenSigStartValue" SG_ 969 ADC_PathPlanPos7Y 0;
BA_ "GenSigTimeoutValue" SG_ 969 ADC_PathPlanPos7Y 0;
BA_ "Remark" SG_ 969 ADC_PathPlanPos7Y "";
BA_ "EventCommandSignal" SG_ 969 ADC_PathPlanPos8X 0;
BA_ "GatewayedSignals" SG_ 969 ADC_PathPlanPos8X 0;
BA_ "GenSigInactiveValue" SG_ 969 ADC_PathPlanPos8X 0;
BA_ "GenSigInvalidValue" SG_ 969 ADC_PathPlanPos8X 0;
BA_ "GenSigSendType" SG_ 969 ADC_PathPlanPos8X 1;
BA_ "GenSigStartValue" SG_ 969 ADC_PathPlanPos8X 0;
BA_ "GenSigTimeoutValue" SG_ 969 ADC_PathPlanPos8X 0;
BA_ "Remark" SG_ 969 ADC_PathPlanPos8X "";
BA_ "EventCommandSignal" SG_ 969 ADC_PathPlanPos8Y 0;
BA_ "GatewayedSignals" SG_ 969 ADC_PathPlanPos8Y 0;
BA_ "GenSigInactiveValue" SG_ 969 ADC_PathPlanPos8Y 0;
BA_ "GenSigInvalidValue" SG_ 969 ADC_PathPlanPos8Y 0;
BA_ "GenSigSendType" SG_ 969 ADC_PathPlanPos8Y 1;
BA_ "GenSigStartValue" SG_ 969 ADC_PathPlanPos8Y 0;
BA_ "GenSigTimeoutValue" SG_ 969 ADC_PathPlanPos8Y 0;
BA_ "Remark" SG_ 969 ADC_PathPlanPos8Y "";
BA_ "EventCommandSignal" SG_ 969 ADC_PathPlanPos9X 0;
BA_ "GatewayedSignals" SG_ 969 ADC_PathPlanPos9X 0;
BA_ "GenSigInactiveValue" SG_ 969 ADC_PathPlanPos9X 0;
BA_ "GenSigInvalidValue" SG_ 969 ADC_PathPlanPos9X 0;
BA_ "GenSigSendType" SG_ 969 ADC_PathPlanPos9X 1;
BA_ "GenSigStartValue" SG_ 969 ADC_PathPlanPos9X 0;
BA_ "GenSigTimeoutValue" SG_ 969 ADC_PathPlanPos9X 0;
BA_ "Remark" SG_ 969 ADC_PathPlanPos9X "";
BA_ "EventCommandSignal" SG_ 969 ADC_PathPlanPos9Y 0;
BA_ "GatewayedSignals" SG_ 969 ADC_PathPlanPos9Y 0;
BA_ "GenSigInactiveValue" SG_ 969 ADC_PathPlanPos9Y 0;
BA_ "GenSigInvalidValue" SG_ 969 ADC_PathPlanPos9Y 0;
BA_ "GenSigSendType" SG_ 969 ADC_PathPlanPos9Y 1;
BA_ "GenSigStartValue" SG_ 969 ADC_PathPlanPos9Y 0;
BA_ "GenSigTimeoutValue" SG_ 969 ADC_PathPlanPos9Y 0;
BA_ "Remark" SG_ 969 ADC_PathPlanPos9Y "";
BA_ "EventCommandSignal" SG_ 969 ADC_PathPlanPos10X 0;
BA_ "GatewayedSignals" SG_ 969 ADC_PathPlanPos10X 0;
BA_ "GenSigInactiveValue" SG_ 969 ADC_PathPlanPos10X 0;
BA_ "GenSigInvalidValue" SG_ 969 ADC_PathPlanPos10X 0;
BA_ "GenSigSendType" SG_ 969 ADC_PathPlanPos10X 1;
BA_ "GenSigStartValue" SG_ 969 ADC_PathPlanPos10X 0;
BA_ "GenSigTimeoutValue" SG_ 969 ADC_PathPlanPos10X 0;
BA_ "Remark" SG_ 969 ADC_PathPlanPos10X "";
BA_ "EventCommandSignal" SG_ 969 ADC_PathPlanPos10Y 0;
BA_ "GatewayedSignals" SG_ 969 ADC_PathPlanPos10Y 0;
BA_ "GenSigInactiveValue" SG_ 969 ADC_PathPlanPos10Y 0;
BA_ "GenSigInvalidValue" SG_ 969 ADC_PathPlanPos10Y 0;
BA_ "GenSigSendType" SG_ 969 ADC_PathPlanPos10Y 1;
BA_ "GenSigStartValue" SG_ 969 ADC_PathPlanPos10Y 0;
BA_ "GenSigTimeoutValue" SG_ 969 ADC_PathPlanPos10Y 0;
BA_ "Remark" SG_ 969 ADC_PathPlanPos10Y "";
BA_ "EventCommandSignal" SG_ 969 ADC_PathPlanPos11X 0;
BA_ "GatewayedSignals" SG_ 969 ADC_PathPlanPos11X 0;
BA_ "GenSigInactiveValue" SG_ 969 ADC_PathPlanPos11X 0;
BA_ "GenSigInvalidValue" SG_ 969 ADC_PathPlanPos11X 0;
BA_ "GenSigSendType" SG_ 969 ADC_PathPlanPos11X 1;
BA_ "GenSigStartValue" SG_ 969 ADC_PathPlanPos11X 0;
BA_ "GenSigTimeoutValue" SG_ 969 ADC_PathPlanPos11X 0;
BA_ "Remark" SG_ 969 ADC_PathPlanPos11X "";
BA_ "EventCommandSignal" SG_ 969 ADC_PathPlanPos11Y 0;
BA_ "GatewayedSignals" SG_ 969 ADC_PathPlanPos11Y 0;
BA_ "GenSigInactiveValue" SG_ 969 ADC_PathPlanPos11Y 0;
BA_ "GenSigInvalidValue" SG_ 969 ADC_PathPlanPos11Y 0;
BA_ "GenSigSendType" SG_ 969 ADC_PathPlanPos11Y 1;
BA_ "GenSigStartValue" SG_ 969 ADC_PathPlanPos11Y 0;
BA_ "GenSigTimeoutValue" SG_ 969 ADC_PathPlanPos11Y 0;
BA_ "Remark" SG_ 969 ADC_PathPlanPos11Y "";
BA_ "EventCommandSignal" SG_ 969 ADC_PathPlanPos12X 0;
BA_ "GatewayedSignals" SG_ 969 ADC_PathPlanPos12X 0;
BA_ "GenSigInactiveValue" SG_ 969 ADC_PathPlanPos12X 0;
BA_ "GenSigInvalidValue" SG_ 969 ADC_PathPlanPos12X 0;
BA_ "GenSigSendType" SG_ 969 ADC_PathPlanPos12X 1;
BA_ "GenSigStartValue" SG_ 969 ADC_PathPlanPos12X 0;
BA_ "GenSigTimeoutValue" SG_ 969 ADC_PathPlanPos12X 0;
BA_ "Remark" SG_ 969 ADC_PathPlanPos12X "";
BA_ "EventCommandSignal" SG_ 969 ADC_PathPlanPos12Y 0;
BA_ "GatewayedSignals" SG_ 969 ADC_PathPlanPos12Y 0;
BA_ "GenSigInactiveValue" SG_ 969 ADC_PathPlanPos12Y 0;
BA_ "GenSigInvalidValue" SG_ 969 ADC_PathPlanPos12Y 0;
BA_ "GenSigSendType" SG_ 969 ADC_PathPlanPos12Y 1;
BA_ "GenSigStartValue" SG_ 969 ADC_PathPlanPos12Y 0;
BA_ "GenSigTimeoutValue" SG_ 969 ADC_PathPlanPos12Y 0;
BA_ "Remark" SG_ 969 ADC_PathPlanPos12Y "";
BA_ "EventCommandSignal" SG_ 969 ADC_PathPlanPos13X 0;
BA_ "GatewayedSignals" SG_ 969 ADC_PathPlanPos13X 0;
BA_ "GenSigInactiveValue" SG_ 969 ADC_PathPlanPos13X 0;
BA_ "GenSigInvalidValue" SG_ 969 ADC_PathPlanPos13X 0;
BA_ "GenSigSendType" SG_ 969 ADC_PathPlanPos13X 1;
BA_ "GenSigStartValue" SG_ 969 ADC_PathPlanPos13X 0;
BA_ "GenSigTimeoutValue" SG_ 969 ADC_PathPlanPos13X 0;
BA_ "Remark" SG_ 969 ADC_PathPlanPos13X "";
BA_ "EventCommandSignal" SG_ 969 ADC_PathPlanPos13Y 0;
BA_ "GatewayedSignals" SG_ 969 ADC_PathPlanPos13Y 0;
BA_ "GenSigInactiveValue" SG_ 969 ADC_PathPlanPos13Y 0;
BA_ "GenSigInvalidValue" SG_ 969 ADC_PathPlanPos13Y 0;
BA_ "GenSigSendType" SG_ 969 ADC_PathPlanPos13Y 1;
BA_ "GenSigStartValue" SG_ 969 ADC_PathPlanPos13Y 0;
BA_ "GenSigTimeoutValue" SG_ 969 ADC_PathPlanPos13Y 0;
BA_ "Remark" SG_ 969 ADC_PathPlanPos13Y "";
BA_ "EventCommandSignal" SG_ 969 ADC_PathPlanPos14X 0;
BA_ "GatewayedSignals" SG_ 969 ADC_PathPlanPos14X 0;
BA_ "GenSigInactiveValue" SG_ 969 ADC_PathPlanPos14X 0;
BA_ "GenSigInvalidValue" SG_ 969 ADC_PathPlanPos14X 0;
BA_ "GenSigSendType" SG_ 969 ADC_PathPlanPos14X 1;
BA_ "GenSigStartValue" SG_ 969 ADC_PathPlanPos14X 0;
BA_ "GenSigTimeoutValue" SG_ 969 ADC_PathPlanPos14X 0;
BA_ "Remark" SG_ 969 ADC_PathPlanPos14X "";
BA_ "EventCommandSignal" SG_ 969 ADC_PathPlanPos14Y 0;
BA_ "GatewayedSignals" SG_ 969 ADC_PathPlanPos14Y 0;
BA_ "GenSigInactiveValue" SG_ 969 ADC_PathPlanPos14Y 0;
BA_ "GenSigInvalidValue" SG_ 969 ADC_PathPlanPos14Y 0;
BA_ "GenSigSendType" SG_ 969 ADC_PathPlanPos14Y 1;
BA_ "GenSigStartValue" SG_ 969 ADC_PathPlanPos14Y 0;
BA_ "GenSigTimeoutValue" SG_ 969 ADC_PathPlanPos14Y 0;
BA_ "Remark" SG_ 969 ADC_PathPlanPos14Y "";
BA_ "EventCommandSignal" SG_ 969 ADC_PathPlanPos15X 0;
BA_ "GatewayedSignals" SG_ 969 ADC_PathPlanPos15X 0;
BA_ "GenSigInactiveValue" SG_ 969 ADC_PathPlanPos15X 0;
BA_ "GenSigInvalidValue" SG_ 969 ADC_PathPlanPos15X 0;
BA_ "GenSigSendType" SG_ 969 ADC_PathPlanPos15X 1;
BA_ "GenSigStartValue" SG_ 969 ADC_PathPlanPos15X 0;
BA_ "GenSigTimeoutValue" SG_ 969 ADC_PathPlanPos15X 0;
BA_ "Remark" SG_ 969 ADC_PathPlanPos15X "";
BA_ "EventCommandSignal" SG_ 969 ADC_PathPlanPos15Y 0;
BA_ "GatewayedSignals" SG_ 969 ADC_PathPlanPos15Y 0;
BA_ "GenSigInactiveValue" SG_ 969 ADC_PathPlanPos15Y 0;
BA_ "GenSigInvalidValue" SG_ 969 ADC_PathPlanPos15Y 0;
BA_ "GenSigSendType" SG_ 969 ADC_PathPlanPos15Y 1;
BA_ "GenSigStartValue" SG_ 969 ADC_PathPlanPos15Y 0;
BA_ "GenSigTimeoutValue" SG_ 969 ADC_PathPlanPos15Y 0;
BA_ "Remark" SG_ 969 ADC_PathPlanPos15Y "";
BA_ "EventCommandSignal" SG_ 969 ADC_PathPlanPos16X 0;
BA_ "GatewayedSignals" SG_ 969 ADC_PathPlanPos16X 0;
BA_ "GenSigInactiveValue" SG_ 969 ADC_PathPlanPos16X 0;
BA_ "GenSigInvalidValue" SG_ 969 ADC_PathPlanPos16X 0;
BA_ "GenSigSendType" SG_ 969 ADC_PathPlanPos16X 1;
BA_ "GenSigStartValue" SG_ 969 ADC_PathPlanPos16X 0;
BA_ "GenSigTimeoutValue" SG_ 969 ADC_PathPlanPos16X 0;
BA_ "Remark" SG_ 969 ADC_PathPlanPos16X "";
BA_ "EventCommandSignal" SG_ 969 ADC_PathPlanPos16Y 0;
BA_ "GatewayedSignals" SG_ 969 ADC_PathPlanPos16Y 0;
BA_ "GenSigInactiveValue" SG_ 969 ADC_PathPlanPos16Y 0;
BA_ "GenSigInvalidValue" SG_ 969 ADC_PathPlanPos16Y 0;
BA_ "GenSigSendType" SG_ 969 ADC_PathPlanPos16Y 1;
BA_ "GenSigStartValue" SG_ 969 ADC_PathPlanPos16Y 0;
BA_ "GenSigTimeoutValue" SG_ 969 ADC_PathPlanPos16Y 0;
BA_ "Remark" SG_ 969 ADC_PathPlanPos16Y "";
BA_ "EventCommandSignal" SG_ 969 ADC_PathPlanPos17X 0;
BA_ "GatewayedSignals" SG_ 969 ADC_PathPlanPos17X 0;
BA_ "GenSigInactiveValue" SG_ 969 ADC_PathPlanPos17X 0;
BA_ "GenSigInvalidValue" SG_ 969 ADC_PathPlanPos17X 0;
BA_ "GenSigSendType" SG_ 969 ADC_PathPlanPos17X 1;
BA_ "GenSigStartValue" SG_ 969 ADC_PathPlanPos17X 0;
BA_ "GenSigTimeoutValue" SG_ 969 ADC_PathPlanPos17X 0;
BA_ "Remark" SG_ 969 ADC_PathPlanPos17X "";
BA_ "EventCommandSignal" SG_ 969 ADC_PathPlanPos17Y 0;
BA_ "GatewayedSignals" SG_ 969 ADC_PathPlanPos17Y 0;
BA_ "GenSigInactiveValue" SG_ 969 ADC_PathPlanPos17Y 0;
BA_ "GenSigInvalidValue" SG_ 969 ADC_PathPlanPos17Y 0;
BA_ "GenSigSendType" SG_ 969 ADC_PathPlanPos17Y 1;
BA_ "GenSigStartValue" SG_ 969 ADC_PathPlanPos17Y 0;
BA_ "GenSigTimeoutValue" SG_ 969 ADC_PathPlanPos17Y 0;
BA_ "Remark" SG_ 969 ADC_PathPlanPos17Y "";
BA_ "EventCommandSignal" SG_ 969 ADC_PathPlanPos18X 0;
BA_ "GatewayedSignals" SG_ 969 ADC_PathPlanPos18X 0;
BA_ "GenSigInactiveValue" SG_ 969 ADC_PathPlanPos18X 0;
BA_ "GenSigInvalidValue" SG_ 969 ADC_PathPlanPos18X 0;
BA_ "GenSigSendType" SG_ 969 ADC_PathPlanPos18X 1;
BA_ "GenSigStartValue" SG_ 969 ADC_PathPlanPos18X 0;
BA_ "GenSigTimeoutValue" SG_ 969 ADC_PathPlanPos18X 0;
BA_ "Remark" SG_ 969 ADC_PathPlanPos18X "";
BA_ "EventCommandSignal" SG_ 969 ADC_PathPlanPos18Y 0;
BA_ "GatewayedSignals" SG_ 969 ADC_PathPlanPos18Y 0;
BA_ "GenSigInactiveValue" SG_ 969 ADC_PathPlanPos18Y 0;
BA_ "GenSigInvalidValue" SG_ 969 ADC_PathPlanPos18Y 0;
BA_ "GenSigSendType" SG_ 969 ADC_PathPlanPos18Y 1;
BA_ "GenSigStartValue" SG_ 969 ADC_PathPlanPos18Y 0;
BA_ "GenSigTimeoutValue" SG_ 969 ADC_PathPlanPos18Y 0;
BA_ "Remark" SG_ 969 ADC_PathPlanPos18Y "";
BA_ "EventCommandSignal" SG_ 969 ADC_PathPlanPos19X 0;
BA_ "GatewayedSignals" SG_ 969 ADC_PathPlanPos19X 0;
BA_ "GenSigInactiveValue" SG_ 969 ADC_PathPlanPos19X 0;
BA_ "GenSigInvalidValue" SG_ 969 ADC_PathPlanPos19X 0;
BA_ "GenSigSendType" SG_ 969 ADC_PathPlanPos19X 1;
BA_ "GenSigStartValue" SG_ 969 ADC_PathPlanPos19X 0;
BA_ "GenSigTimeoutValue" SG_ 969 ADC_PathPlanPos19X 0;
BA_ "Remark" SG_ 969 ADC_PathPlanPos19X "";
BA_ "EventCommandSignal" SG_ 969 ADC_PathPlanPos19Y 0;
BA_ "GatewayedSignals" SG_ 969 ADC_PathPlanPos19Y 0;
BA_ "GenSigInactiveValue" SG_ 969 ADC_PathPlanPos19Y 0;
BA_ "GenSigInvalidValue" SG_ 969 ADC_PathPlanPos19Y 0;
BA_ "GenSigSendType" SG_ 969 ADC_PathPlanPos19Y 1;
BA_ "GenSigStartValue" SG_ 969 ADC_PathPlanPos19Y 0;
BA_ "GenSigTimeoutValue" SG_ 969 ADC_PathPlanPos19Y 0;
BA_ "Remark" SG_ 969 ADC_PathPlanPos19Y "";
BA_ "EventCommandSignal" SG_ 969 ADC_PathPlanPos20X 0;
BA_ "GatewayedSignals" SG_ 969 ADC_PathPlanPos20X 0;
BA_ "GenSigInactiveValue" SG_ 969 ADC_PathPlanPos20X 0;
BA_ "GenSigInvalidValue" SG_ 969 ADC_PathPlanPos20X 0;
BA_ "GenSigSendType" SG_ 969 ADC_PathPlanPos20X 1;
BA_ "GenSigStartValue" SG_ 969 ADC_PathPlanPos20X 0;
BA_ "GenSigTimeoutValue" SG_ 969 ADC_PathPlanPos20X 0;
BA_ "Remark" SG_ 969 ADC_PathPlanPos20X "";
BA_ "EventCommandSignal" SG_ 969 ADC_PathPlanPos20Y 0;
BA_ "GatewayedSignals" SG_ 969 ADC_PathPlanPos20Y 0;
BA_ "GenSigInactiveValue" SG_ 969 ADC_PathPlanPos20Y 0;
BA_ "GenSigInvalidValue" SG_ 969 ADC_PathPlanPos20Y 0;
BA_ "GenSigSendType" SG_ 969 ADC_PathPlanPos20Y 1;
BA_ "GenSigStartValue" SG_ 969 ADC_PathPlanPos20Y 0;
BA_ "GenSigTimeoutValue" SG_ 969 ADC_PathPlanPos20Y 0;
BA_ "Remark" SG_ 969 ADC_PathPlanPos20Y "";
BA_ "EventCommandSignal" SG_ 970 ADC_AutEve 0;
BA_ "GatewayedSignals" SG_ 970 ADC_AutEve 0;
BA_ "GenSigInactiveValue" SG_ 970 ADC_AutEve 0;
BA_ "GenSigInvalidValue" SG_ 970 ADC_AutEve 0;
BA_ "GenSigSendType" SG_ 970 ADC_AutEve 1;
BA_ "GenSigStartValue" SG_ 970 ADC_AutEve 0;
BA_ "GenSigTimeoutValue" SG_ 970 ADC_AutEve 0;
BA_ "Remark" SG_ 970 ADC_AutEve "";
BA_ "EventCommandSignal" SG_ 970 ADC_SeldParkID 0;
BA_ "GatewayedSignals" SG_ 970 ADC_SeldParkID 0;
BA_ "GenSigInactiveValue" SG_ 970 ADC_SeldParkID 0;
BA_ "GenSigInvalidValue" SG_ 970 ADC_SeldParkID 0;
BA_ "GenSigSendType" SG_ 970 ADC_SeldParkID 1;
BA_ "GenSigStartValue" SG_ 970 ADC_SeldParkID 0;
BA_ "GenSigTimeoutValue" SG_ 970 ADC_SeldParkID 0;
BA_ "Remark" SG_ 970 ADC_SeldParkID "";
BA_ "EventCommandSignal" SG_ 970 ADC_VehParkMod 0;
BA_ "GatewayedSignals" SG_ 970 ADC_VehParkMod 0;
BA_ "GenSigInactiveValue" SG_ 970 ADC_VehParkMod 0;
BA_ "GenSigInvalidValue" SG_ 970 ADC_VehParkMod 0;
BA_ "GenSigSendType" SG_ 970 ADC_VehParkMod 1;
BA_ "GenSigStartValue" SG_ 970 ADC_VehParkMod 0;
BA_ "GenSigTimeoutValue" SG_ 970 ADC_VehParkMod 0;
BA_ "Remark" SG_ 970 ADC_VehParkMod "";
BA_ "EventCommandSignal" SG_ 970 ADC_ParkProgs 0;
BA_ "GatewayedSignals" SG_ 970 ADC_ParkProgs 0;
BA_ "GenSigInactiveValue" SG_ 970 ADC_ParkProgs 0;
BA_ "GenSigInvalidValue" SG_ 970 ADC_ParkProgs 0;
BA_ "GenSigSendType" SG_ 970 ADC_ParkProgs 1;
BA_ "GenSigStartValue" SG_ 970 ADC_ParkProgs 0;
BA_ "GenSigTimeoutValue" SG_ 970 ADC_ParkProgs 0;
BA_ "Remark" SG_ 970 ADC_ParkProgs "";
BA_ "EventCommandSignal" SG_ 970 ADC_ParkRmngDst 0;
BA_ "GatewayedSignals" SG_ 970 ADC_ParkRmngDst 0;
BA_ "GenSigInactiveValue" SG_ 970 ADC_ParkRmngDst 0;
BA_ "GenSigInvalidValue" SG_ 970 ADC_ParkRmngDst 0;
BA_ "GenSigSendType" SG_ 970 ADC_ParkRmngDst 1;
BA_ "GenSigStartValue" SG_ 970 ADC_ParkRmngDst 0;
BA_ "GenSigTimeoutValue" SG_ 970 ADC_ParkRmngDst 0;
BA_ "Remark" SG_ 970 ADC_ParkRmngDst "";
BA_ "EventCommandSignal" SG_ 970 ADC_ObstclDst 0;
BA_ "GatewayedSignals" SG_ 970 ADC_ObstclDst 0;
BA_ "GenSigInactiveValue" SG_ 970 ADC_ObstclDst 0;
BA_ "GenSigInvalidValue" SG_ 970 ADC_ObstclDst 0;
BA_ "GenSigSendType" SG_ 970 ADC_ObstclDst 1;
BA_ "GenSigStartValue" SG_ 970 ADC_ObstclDst 0;
BA_ "GenSigTimeoutValue" SG_ 970 ADC_ObstclDst 0;
BA_ "Remark" SG_ 970 ADC_ObstclDst "";
BA_ "EventCommandSignal" SG_ 970 ADC_parkInterruptDuration 0;
BA_ "GatewayedSignals" SG_ 970 ADC_parkInterruptDuration 0;
BA_ "GenSigInactiveValue" SG_ 970 ADC_parkInterruptDuration 0;
BA_ "GenSigInvalidValue" SG_ 970 ADC_parkInterruptDuration 0;
BA_ "GenSigSendType" SG_ 970 ADC_parkInterruptDuration 1;
BA_ "GenSigStartValue" SG_ 970 ADC_parkInterruptDuration 0;
BA_ "GenSigTimeoutValue" SG_ 970 ADC_parkInterruptDuration 0;
BA_ "Remark" SG_ 970 ADC_parkInterruptDuration "";
BA_ "EventCommandSignal" SG_ 970 ADC_EPS_SteeringAngle 0;
BA_ "GatewayedSignals" SG_ 970 ADC_EPS_SteeringAngle 0;
BA_ "GenSigInactiveValue" SG_ 970 ADC_EPS_SteeringAngle 0;
BA_ "GenSigInvalidValue" SG_ 970 ADC_EPS_SteeringAngle 0;
BA_ "GenSigSendType" SG_ 970 ADC_EPS_SteeringAngle 1;
BA_ "GenSigStartValue" SG_ 970 ADC_EPS_SteeringAngle 0;
BA_ "GenSigTimeoutValue" SG_ 970 ADC_EPS_SteeringAngle 0;
BA_ "Remark" SG_ 970 ADC_EPS_SteeringAngle "";
BA_ "EventCommandSignal" SG_ 970 ADC_FrontEndParkInAvl 0;
BA_ "GatewayedSignals" SG_ 970 ADC_FrontEndParkInAvl 0;
BA_ "GenSigInactiveValue" SG_ 970 ADC_FrontEndParkInAvl 0;
BA_ "GenSigInvalidValue" SG_ 970 ADC_FrontEndParkInAvl 0;
BA_ "GenSigSendType" SG_ 970 ADC_FrontEndParkInAvl 1;
BA_ "GenSigStartValue" SG_ 970 ADC_FrontEndParkInAvl 0;
BA_ "GenSigTimeoutValue" SG_ 970 ADC_FrontEndParkInAvl 0;
BA_ "Remark" SG_ 970 ADC_FrontEndParkInAvl "";
BA_ "EventCommandSignal" SG_ 970 ADC_RPAobscancelCfm 0;
BA_ "GatewayedSignals" SG_ 970 ADC_RPAobscancelCfm 0;
BA_ "GenSigInactiveValue" SG_ 970 ADC_RPAobscancelCfm 0;
BA_ "GenSigInvalidValue" SG_ 970 ADC_RPAobscancelCfm 0;
BA_ "GenSigSendType" SG_ 970 ADC_RPAobscancelCfm 1;
BA_ "GenSigStartValue" SG_ 970 ADC_RPAobscancelCfm 0;
BA_ "GenSigTimeoutValue" SG_ 970 ADC_RPAobscancelCfm 0;
BA_ "Remark" SG_ 970 ADC_RPAobscancelCfm "";
VAL_ 947 ADC_LowBeamReq 0 "No Request" 1 "turn on" 2 "turn off"  ;
VAL_ 947 ADC_IHBC_HighBeamReq 0 "No Request" 1 "Request"  ;
VAL_ 947 ADC_FlashReq 0 "No Request" 1 "turn on" 2 "turn off"  ;
VAL_ 947 ADC_PositionLampReq 0 "No Request" 1 "turn on" 2 "turn off"  ;
VAL_ 947 ADC_SunroofOpenCloseReq 0 "No request" 1 "Request close sunroof" 2 "Request open sunroof" 3 "Not used"  ;
VAL_ 947 ADC_SOCWakeupHVReq 0 "No Request" 1 "Request"  ;
VAL_ 947 ADC_HVACCtrlReq 0 "No Requset" 1 "Requset Open"  ;
VAL_ 947 ADC_FFogLightReq 0 "No Request" 1 "turn on" 2 "turn off"  ;
VAL_ 947 ADC_RFogLightReq 0 "No Request" 1 "turn on" 2 "turn off"  ;
VAL_ 947 ADC_HornReq 0 "No Request" 1 "Continuous On 1" 2 "Continuous On 2" 3 "Off" 4 "Remind" 5 "Alarm"  ;
VAL_ 947 ADC_FWiperReq 0 "No Request" 1 "MIST" 2 "Continuous slow" 3 "Continuous fast" 4 "turn off Wiper" 5 "Auto Control"  ;
VAL_ 947 ADC_RWiperReq 0 "No Request" 1 "MIST" 2 "Continuous slow" 3 "Continuous fast" 4 "turn off Wiper"  ;
VAL_ 947 ADC_FWaterSprayReq 0 "No Request" 1 "On" 2 "Off"  ;
VAL_ 947 ADC_RWaterSprayReq 0 "No Request" 1 "On" 2 "Off"  ;
VAL_ 947 ADC_CCUReqVD 0 "not valid" 1 "valid"  ;
VAL_ 947 ADC_WindowOpenReq 0 "No request" 1 "Request open all windows"  ;
VAL_ 947 ADC_WindowCloseReq 0 "No request" 1 "Request Close all windows"  ;
VAL_ 947 ADC_PLGMOpenReq 0 "No request" 1 "Request"  ;
VAL_ 947 ADC_PLGMCloseReq 0 "No request" 1 "Request"  ;
VAL_ 947 ADC_FDemistReq 0 "No Request" 1 "On" 2 "Off"  ;
VAL_ 947 ADC_RDemistReq 0 "No Request" 1 "On" 2 "Off"  ;
VAL_ 947 ADC_ThmPostRun 0 "TMS is not required to respond to ADC cooling flow request" 1 "TMS is required to respind to ADC cooling flow request"  ;
VAL_ 947 ADC_DriverFaceWindReq 0 "No Request" 1 "On" 2 "Off"  ;
VAL_ 947 ADC_EcallReq 0 "Not Request" 1 "Request"  ;
VAL_ 947 ADC_FlowReq 0 "0      L/min" 1 "0.25 L/min" 2 "0.5   L/min" 3 "0.75 L/min" 4 "1      L/min" 5 "1.25 L/min" 6 "1.5   L/min" 7 "1.75 L/min" 8 "2      L/min" 9 "2.25 L/min" 10 "2.5   L/min" 11 "2.75 L/min" 12 "3      L/min" 13 "3.25 L/min" 14 "3.5   L/min" 15 "3.75  L/min" 16 "4      L/min"  ;
VAL_ 947 ADC_DriverSeatBeltPretightenReq 0 "Not Request" 1 "Request"  ;
VAL_ 947 ADC_LockReq 0 "No Request" 1 "Lock" 2 "Unlock" 3 "LockandArm" 4 "UnlockandDisarm" 5 "Reserved" 6 "Reserved" 7 "Reserved"  ;
VAL_ 947 ADC_HoldLockReq 0 "No Request" 1 "HoldLock" 2 "HoldUnlock" 3 "HoldShield"  ;
VAL_ 947 ADC_RearMirrorReq 0 "No?Request" 1 "Unfold" 2 "Fold" 3 "Reserved"  ;
VAL_ 947 ADC_HoldRearMirrorReq 0 "No?Request" 1 "Hold Unfold" 2 "Hold Fold" 3 "Reserved"  ;
VAL_ 947 ADC_ADSLightReq 0 "No request" 1 "Blue continue" 2 "Off" 3 "Reserved" 4 "Reserved" 5 "Reserved" 6 "Reserved" 7 "Reserved"  ;
VAL_ 947 ADC_DriverSeatBeltVibrWarnReq 0 "No Request" 1 "Mode 1" 2 "Mode 2" 3 "Mode 3" 4 "Reserved" 5 "Reserved" 6 "Reserved" 7 "Reserved"  ;
VAL_ 947 ADC_FrtWindshildHeatReq 0 "No Request" 1 "On" 2 "Off" 3 "reserve"  ;
VAL_ 947 ADC_BeamSwReq 0 "No request" 1 "Auto_mode" 2 "Position_light (reserve)" 3 "Low_beam (reserve)"  ;
VAL_ 947 IFC_SysCalibrationSt 0 "Calibration Success" 1 "Calibration In Process" 2 "Calibration Failed" 3 "Not used"  ;
VAL_ 947 ADC_ADBIHBCEnableReq 0 "No Request" 1 "Turn on" 2 "Reserved" 3 "Reserved"  ;
VAL_ 947 ADC_LowPowerReqVD_A 0 "Not valid" 1 "Valid"  ;
VAL_ 947 ADC_LowPowerReq_A 0 "Not Request" 1 "Low Power"  ;
VAL_ 947 ADC_MachineStatus 0 "default" 1 "Modechanging" 2 "Active Mode" 3 "PartialActive Mode"  ;
VAL_ 947 ADC_LowPowerFailReason 0 "Default" 1 "ADS Function Active" 2 "Machine is not available" 3 "OTA"  ;
VAL_ 947 ADC_LightbarReq 0 "No request;" 1 "White;" 2 "Blue;" 3 "Orange;" 4 "Red;" 5 "Reserved;" 6 "Reserved;" 7 "Reserved;" 8 "Reserved;" 9 "Reserved;" 10 "Reserved;" 11 "Reserved;" 12 "Reserved;" 13 "Reserved;" 14 "Reserved;" 15 "Invalid;"  ;
VAL_ 947 ADC_ChgPortControlReq 0 "No Request" 1 "Close" 2 "Open" 3 "Reserved"  ;
VAL_ 947 ADC_ChgPortHoldControlReq 0 "No Request" 1 "HoldClose" 2 "HoldOpen" 3 "HoldShield"  ;
VAL_ 947 ADC_ChargHoldReq 0 "No Request" 1 "HoldStart" 2 "HoldStop" 3 "HoldShield"  ;
VAL_ 947 ADC_ChargReq 0 "No Request" 1 "Start" 2 "Stop" 3 "Reserved"  ;
VAL_ 947 ADC_ChargGunHoldReq 0 "No Request" 1 "HoldClose" 2 "HoldOpen" 3 "HoldShield"  ;
VAL_ 947 ADC_ChargGunReq 0 "No Request" 1 "Close" 2 "Open" 3 "Reserved"  ;
VAL_ 947 ADC_InteractLightReq 0 "norequest" 1 "Mode1" 2 "Mode2" 3 "Mode3" 4 "Mode4" 5 "Mode5" 6 "Mode6" 7 "Mode7" 8 "Mode8" 9 "Mode9" 10 "Mode10" 11 "Mode11" 12 "Mode12" 13 "Mode13" 14 "Mode14" 15 "Mode15" 16 "Mode16" 17 "Mode17" 18 "Mode18" 19 "Mode19" 20 "Mode20" 21 "Mode21" 22 "reserved" 23 "reserved" 24 "reserved" 25 "reserved" 26 "reserved" 27 "reserved" 28 "reserved" 29 "reserved" 30 "reserved" 31 "reserved"  ;
VAL_ 175 ADC_PAAChallengeReceive 0 "No Receive" 1 "Receive"  ;
VAL_ 175 ADC_APAActPushSt 0 "Not Push" 1 "SenslesEtyParkingPush"  ;
VAL_ 175 PAA_DVRTriggerId 0 "Real time Video Request" 1 "AEB Trigger" 2 "FCW Trigger" 3 "ABP Request" 4 "Crash happen" 5 "LongAccel Over limit" 6 "APA Terminated" 7 "HWA ILCLeft Trigger" 8 "HWA ILCRight Trigger" 9 "HWA TakeOver Trigger" 10 "HWA SafeStop" 11 "RAEB Active" 12 "Parking Real time Video Request" 13 "Reserve" 14 "Reserve" 15 "Reserve" 16 "Reserve" 17 "Reserve" 18 "Reserve" 19 "Reserve" 20 "Reserve" 21 "Reserve" 22 "Reserve" 23 "Reserve" 24 "Reserve" 25 "Reserve" 26 "Reserve" 27 "Reserve" 28 "Reserve" 29 "Reserve" 30 "Reserve" 31 "Reserve"  ;
VAL_ 175 PAA_DVRTrigger 0 "No trigger" 1 "Trigger"  ;
VAL_ 175 ADC_LCAEnableSt 0 "Off" 1 "On" 2 "Failure" 3 "reserved"  ;
VAL_ 127 ADC_IMMO 0 "Matching succeeded (saving pin and ESK succeeded)" 1 "Matching timeout (timeout for saving pin or ESK)）" 2 "Consistent pin and inconsistent ESK" 3 "Inconsistent pin and consistent ESK" 4 "Inconsistent pin and inconsistent ESK"  ;
VAL_ 1294 ADC_NMCBV 0 "Node has not woken up the    network(passive wakeup);" 1 "Node has woken up the network(active wakeup)" 0 "NM PDU contains no Partial Network request information" 1 "NM PDU contains Partial Network request information"  ;
VAL_ 1294 ADC_NMWakeupOrigin 1 "NM Message wakeup              2"  ;
VAL_ 1294 ADC_PNCInformation0 0 "No request" 1 "Request" 0 "No request" 1 "Request" 0 "No request" 1 "Request" 0 "No request" 1 "Request" 1 "Request" 0 "No request" 1 "Request" 0 "No request" 1 "Request"  ;
VAL_ 1294 ADC_PNCInformation1 0 "No request" 1 "Request" 0 "No request" 1 "Request"  ;
VAL_ 969 ADAS_RemoterParkingOnlineOrNot 0 "None" 1 "rolling counter" 2 "rolling counter" 3 "rolling counter" 4 "rolling counter" 5 "rolling counter" 6 "rolling counter" 7 "rolling counter" 8 "rolling counter" 9 "rolling counter" 10 "rolling counter" 11 "rolling counter" 12 "rolling counter" 13 "rolling counter" 14 "rolling counter" 15 "rolling counter" 16 "rolling counter" 17 "rolling counter" 18 "rolling counter" 19 "rolling counter" 20 "rolling counter" 21 "rolling counter" 22 "rolling counter" 23 "rolling counter" 24 "rolling counter" 25 "rolling counter" 26 "rolling counter" 27 "rolling counter" 28 "rolling counter" 29 "rolling counter" 30 "rolling counter" 31 "rolling counter" 32 "rolling counter" 33 "rolling counter" 34 "rolling counter" 35 "rolling counter" 36 "rolling counter" 37 "rolling counter" 38 "rolling counter" 39 "rolling counter" 40 "rolling counter" 41 "rolling counter" 42 "rolling counter" 43 "rolling counter" 44 "rolling counter" 45 "rolling counter" 46 "rolling counter" 47 "rolling counter" 48 "rolling counter" 49 "rolling counter" 50 "rolling counter" 51 "rolling counter" 52 "rolling counter" 53 "rolling counter" 54 "rolling counter" 55 "rolling counter" 56 "rolling counter" 57 "rolling counter" 58 "rolling counter" 59 "rolling counter" 60 "rolling counter" 61 "rolling counter" 62 "rolling counter" 63 "rolling counter" 64 "rolling counter" 65 "rolling counter" 66 "rolling counter" 67 "rolling counter" 68 "rolling counter" 69 "rolling counter" 70 "rolling counter" 71 "rolling counter" 72 "rolling counter" 73 "rolling counter" 74 "rolling counter" 75 "rolling counter" 76 "rolling counter" 77 "rolling counter" 78 "rolling counter" 79 "rolling counter" 80 "rolling counter" 81 "rolling counter" 82 "rolling counter" 83 "rolling counter" 84 "rolling counter" 85 "rolling counter" 86 "rolling counter" 87 "rolling counter" 88 "rolling counter" 89 "rolling counter" 90 "rolling counter" 91 "rolling counter" 92 "rolling counter" 93 "rolling counter" 94 "rolling counter" 95 "rolling counter" 96 "rolling counter" 97 "rolling counter" 98 "rolling counter" 99 "rolling counter" 100 "rolling counter" 101 "rolling counter" 102 "rolling counter" 103 "rolling counter" 104 "rolling counter" 105 "rolling counter" 106 "rolling counter" 107 "rolling counter" 108 "rolling counter" 109 "rolling counter" 110 "rolling counter" 111 "rolling counter" 112 "rolling counter" 113 "rolling counter" 114 "rolling counter" 115 "rolling counter" 116 "rolling counter" 117 "rolling counter" 118 "rolling counter" 119 "rolling counter" 120 "rolling counter" 121 "rolling counter" 122 "rolling counter" 123 "rolling counter" 124 "rolling counter" 125 "rolling counter" 126 "rolling counter" 127 "rolling counter" 128 "rolling counter" 129 "rolling counter" 130 "rolling counter" 131 "rolling counter" 132 "rolling counter" 133 "rolling counter" 134 "rolling counter" 135 "rolling counter" 136 "rolling counter" 137 "rolling counter" 138 "rolling counter" 139 "rolling counter" 140 "rolling counter" 141 "rolling counter" 142 "rolling counter" 143 "rolling counter" 144 "rolling counter" 145 "rolling counter" 146 "rolling counter" 147 "rolling counter" 148 "rolling counter" 149 "rolling counter" 150 "rolling counter" 151 "rolling counter" 152 "rolling counter" 153 "rolling counter" 154 "rolling counter" 155 "rolling counter" 156 "rolling counter" 157 "rolling counter" 158 "rolling counter" 159 "rolling counter" 160 "rolling counter" 161 "rolling counter" 162 "rolling counter" 163 "rolling counter" 164 "rolling counter" 165 "rolling counter" 166 "rolling counter" 167 "rolling counter" 168 "rolling counter" 169 "rolling counter" 170 "rolling counter" 171 "rolling counter" 172 "rolling counter" 173 "rolling counter" 174 "rolling counter" 175 "rolling counter" 176 "rolling counter" 177 "rolling counter" 178 "rolling counter" 179 "rolling counter" 180 "rolling counter" 181 "rolling counter" 182 "rolling counter" 183 "rolling counter" 184 "rolling counter" 185 "rolling counter" 186 "rolling counter" 187 "rolling counter" 188 "rolling counter" 189 "rolling counter" 190 "rolling counter" 191 "rolling counter" 192 "rolling counter" 193 "rolling counter" 194 "rolling counter" 195 "rolling counter" 196 "rolling counter" 197 "rolling counter" 198 "rolling counter" 199 "rolling counter" 200 "rolling counter" 201 "rolling counter" 202 "rolling counter" 203 "rolling counter" 204 "rolling counter" 205 "rolling counter" 206 "rolling counter" 207 "rolling counter" 208 "rolling counter" 209 "rolling counter" 210 "rolling counter" 211 "rolling counter" 212 "rolling counter" 213 "rolling counter" 214 "rolling counter" 215 "rolling counter" 216 "rolling counter" 217 "rolling counter" 218 "rolling counter" 219 "rolling counter" 220 "rolling counter" 221 "rolling counter" 222 "rolling counter" 223 "rolling counter" 224 "rolling counter" 225 "rolling counter" 226 "rolling counter" 227 "rolling counter" 228 "rolling counter" 229 "rolling counter" 230 "rolling counter" 231 "rolling counter" 232 "rolling counter" 233 "rolling counter" 234 "rolling counter" 235 "rolling counter" 236 "rolling counter" 237 "rolling counter" 238 "rolling counter" 239 "rolling counter" 240 "rolling counter" 241 "rolling counter" 242 "rolling counter" 243 "rolling counter" 244 "rolling counter" 245 "rolling counter" 246 "rolling counter" 247 "rolling counter" 248 "rolling counter" 249 "rolling counter" 250 "rolling counter" 251 "rolling counter" 252 "rolling counter" 253 "rolling counter" 254 "rolling counter" 255 "rolling counter"  ;
VAL_ 969 ADC_RpaParkAuthn 0 "phone_authorized_unconfirm" 1 "phone_authorized_confirm" 2 "reserve_1" 3 "reserve_2"  ;
VAL_ 969 ADC_RemParkPatSel 0 "NONE" 1 "PARK_IN_REQUEST_CONFIRMED" 2 "PARK_OUT_REQUEST_CONFIRMED" 3 "RESERVED"  ;
VAL_ 969 ADC_ParkDirCfm 0 "None" 1 "ParallelLeft_confirm" 2 "ParallelRight_confirm" 3 "PerpendicularForward_confirm" 4 "PerpendicularLeftForward_confirm" 5 "PerpendicularRightForward_confirm" 6 "PerpendicularLeftBack_confirm" 7 "PerpendicularRightBack_confirm" 8 "PerpendicularBack_confirm" 9 "Reserved" 10 "Reserved" 11 "Reserved" 12 "Reserved" 13 "Reserved" 14 "Reserved" 15 "Reserved"  ;
VAL_ 969 ADC_ParkStMac 0 "STATE_OFF" 1 "STATE_RDA_FORWARD" 2 "STATE_RDA_BACK" 3 "STATE_RDA_ABORT" 4 "STATE_RDA_FINISH" 5 "STATE_CRUISE_FINISH" 6 "STATE_APA_SUSPEND" 7 "STATE_APA_SEARCH" 8 "STATE_APA_STANDBY" 9 "STATE_PARK_OUT" 10 "STATE_PARK_IN" 11 "STATE_APA_FINISH" 12 "STATE_PAUSE" 13 "STATE_OVERRIDE" 14 "Reserved" 15 "Reserved"  ;
VAL_ 969 ADC_PwrOnOffReq 0 "None" 1 "Power on & Enter Ready" 2 "Power off & Lock car" 3 "Enter the ready state" 4 "Exit ready state (maintain high voltage)" 5 "Power off only" 6 "Reserved" 7 "Reserved"  ;
VAL_ 969 ADC_ParkOutDir_ParaLe 0 "Not available" 1 "Available"  ;
VAL_ 969 ADC_ParkOutDir_ParaRi 0 "Not available" 1 "Available"  ;
VAL_ 969 ADC_ParkOutDir_PerpFwd 0 "Not available" 1 "Available"  ;
VAL_ 969 ADC_ParkOutDir_PerpLeFwd 0 "Not available" 1 "Available"  ;
VAL_ 969 ADC_ParkOutDir_PerpRiFwd 0 "Not available" 1 "Available"  ;
VAL_ 969 ADC_ParkOutDir_PerpLeBack 0 "Not available" 1 "Available"  ;
VAL_ 969 ADC_ParkOutDir_PerpRiBack 0 "Not available" 1 "Available"  ;
VAL_ 969 ADC_ParkOutDir_PerpBack 0 "Not available" 1 "Available"  ;
VAL_ 969 ADC_APA_RPAFctUnavlMsg1 0 "none" 1 "happened"  ;
VAL_ 969 ADC_APA_RPAFctUnavlMsg2 0 "none" 1 "happened"  ;
VAL_ 969 ADC_APA_RPAFctUnavlMsg3 0 "none" 1 "happened"  ;
VAL_ 969 ADC_APA_RPAFctUnavlMsg4 0 "none" 1 "happened"  ;
VAL_ 969 ADC_APA_RPAFctUnavlMsg5 0 "none" 1 "happened"  ;
VAL_ 969 ADC_APA_RPAFctUnavlMsg6 0 "none" 1 "happened"  ;
VAL_ 969 ADC_APA_RPAFctUnavlMsg7 0 "none" 1 "happened"  ;
VAL_ 969 ADC_APA_RPAFctUnavlMsg8 0 "none" 1 "happened"  ;
VAL_ 969 ADC_APA_RPAFctUnavlMsg9 0 "none" 1 "happened"  ;
VAL_ 969 ADC_APA_RPAFctUnavlMsg10 0 "none" 1 "happened"  ;
VAL_ 969 ADC_APA_RPAFctUnavlMsg11 0 "none" 1 "happened"  ;
VAL_ 969 ADC_APA_RPAFctUnavlMsg12 0 "none" 1 "happened"  ;
VAL_ 969 ADC_APA_RPAFctUnavlMsg13 0 "none" 1 "happened"  ;
VAL_ 969 ADC_APA_RPAFctUnavlMsg14 0 "none" 1 "happened"  ;
VAL_ 969 ADC_APA_RPAFctUnavlMsg15 0 "none" 1 "happened"  ;
VAL_ 969 ADC_APA_RPAFctUnavlMsg16 0 "none" 1 "happened"  ;
VAL_ 969 ADC_APA_RPAFctUnavlMsg17 0 "none" 1 "happened"  ;
VAL_ 969 ADC_APA_RPAFctUnavlMsg18 0 "none" 1 "happened"  ;
VAL_ 969 ADC_APA_RPAFctUnavlMsg19 0 "none" 1 "happened"  ;
VAL_ 969 ADC_APA_RPAFctUnavlMsg20 0 "none" 1 "happened"  ;
VAL_ 969 ADC_APA_RPAFctUnavlMsg21 0 "none" 1 "happened"  ;
VAL_ 969 ADC_APA_RPAFctUnavlMsg22 0 "none" 1 "happened"  ;
VAL_ 969 ADC_APA_RPAFctUnavlMsg23 0 "none" 1 "happened"  ;
VAL_ 969 ADC_APA_RPAFctUnavlMsg24 0 "none" 1 "happened"  ;
VAL_ 969 ADC_APA_RPAFctUnavlMsg25 0 "none" 1 "happened"  ;
VAL_ 969 ADC_APA_RPACnclMsg1 0 "none" 1 "happened"  ;
VAL_ 969 ADC_APA_RPACnclMsg2 0 "none" 1 "happened"  ;
VAL_ 969 ADC_APA_RPACnclMsg3 0 "none" 1 "happened"  ;
VAL_ 969 ADC_APA_RPACnclMsg4 0 "none" 1 "happened"  ;
VAL_ 969 ADC_APA_RPACnclMsg5 0 "none" 1 "happened"  ;
VAL_ 969 ADC_APA_RPACnclMsg6 0 "none" 1 "happened"  ;
VAL_ 969 ADC_APA_RPACnclMsg7 0 "none" 1 "happened"  ;
VAL_ 969 ADC_APA_RPACnclMsg8 0 "none" 1 "happened"  ;
VAL_ 969 ADC_APA_RPACnclMsg9 0 "none" 1 "happened"  ;
VAL_ 969 ADC_APA_RPACnclMsg10 0 "none" 1 "happened"  ;
VAL_ 969 ADC_APA_RPACnclMsg11 0 "none" 1 "happened"  ;
VAL_ 969 ADC_APA_RPACnclMsg12 0 "none" 1 "happened"  ;
VAL_ 969 ADC_APA_RPACnclMsg13 0 "none" 1 "happened"  ;
VAL_ 969 ADC_APA_RPACnclMsg14 0 "none" 1 "happened"  ;
VAL_ 969 ADC_APA_RPACnclMsg15 0 "none" 1 "happened"  ;
VAL_ 969 ADC_APA_RPACnclMsg16 0 "none" 1 "happened"  ;
VAL_ 969 ADC_APA_RPACnclMsg17 0 "none" 1 "happened"  ;
VAL_ 969 ADC_APA_RPACnclMsg18 0 "none" 1 "happened"  ;
VAL_ 969 ADC_APA_RPACnclMsg19 0 "none" 1 "happened"  ;
VAL_ 969 ADC_APA_RPACnclMsg20 0 "none" 1 "happened"  ;
VAL_ 969 ADC_APA_RPAPauseMsg1 0 "none" 1 "happened"  ;
VAL_ 969 ADC_APA_RPAPauseMsg2 0 "none" 1 "happened"  ;
VAL_ 969 ADC_APA_RPAPauseMsg3 0 "none" 1 "happened"  ;
VAL_ 969 ADC_APA_RPAPauseMsg4 0 "none" 1 "happened"  ;
VAL_ 969 ADC_APA_RPAPauseMsg5 0 "none" 1 "happened"  ;
VAL_ 969 ADC_APA_RPAPauseMsg6 0 "none" 1 "happened"  ;
VAL_ 969 ADC_APA_RPAPauseMsg7 0 "none" 1 "happened"  ;
VAL_ 969 ADC_APA_RPAPauseMsg8 0 "none" 1 "happened"  ;
VAL_ 969 ADC_APA_RPAPauseMsg9 0 "none" 1 "happened"  ;
VAL_ 969 ADC_APA_RPAPauseMsg10 0 "none" 1 "happened"  ;
VAL_ 970 ADC_AutEve 1 "MOP_HMI_NULL" 2 "MOP_HMI_CRUISE" 3 "MOP_HMI_BYPASS" 4 "MOP_HMI_STOP_MAN" 5 "MOP_HMI_STOP_CAR" 6 "MOP_HMI_FOLLOW" 7 "MOP_HMI_MEET" 8 "MOP_HMI_TIME_OUT" 9 "Reserved" 10 "Reserved" 11 "Reserved" 12 "Reserved" 13 "Reserved" 14 "Reserved" 15 "Reserved"  ;
VAL_ 970 ADC_VehParkMod 0 "None" 1 "Head parkin" 2 "Tail parkin" 3 "reserve_1" 4 "reserver_2"  ;
VAL_ 970 ADC_ObstclDst 0 "None" 1 "FLOBSDistance_Level1" 2 "FLOBSDistance_Level2" 3 "FLOBSDistance_Level3" 4 "FMidOBSDistance_Level1" 5 "FMidOBSDistance_Level2" 6 "FMidOBSDistance_Level3" 7 "FROBSDistance_Level1" 8 "FROBSDistance_Level2" 9 "FROBSDistance_Level3" 10 "RLOBSDistance_Level1" 11 "RLOBSDistanceLevel2" 12 "RLOBSDistanceLevel3" 13 "RMidOBSDistance_Level1" 14 "RMidOBSDistance_Level2" 15 "RMidOBSDistance_Level3" 16 "RROBSDistance_Level1" 17 "RROBSDistance_Level2" 18 "RROBSDistance_Level3" 19 "Reserved" 20 "Reserved" 21 "Reserved" 22 "Reserved" 23 "Reserved" 24 "Reserved" 25 "Reserved" 26 "Reserved" 27 "Reserved" 28 "Reserved" 29 "Reserved" 30 "Reserved" 31 "Reserved"  ;
VAL_ 970 ADC_parkInterruptDuration 0 "None" 1 "1~30" 2 "1~30" 3 "1~30" 4 "1~30" 5 "1~30" 6 "1~30" 7 "1~30" 8 "1~30" 9 "1~30" 10 "1~30" 11 "1~30" 12 "1~30" 13 "1~30" 14 "1~30" 15 "1~30" 16 "1~30" 17 "1~30" 18 "1~30" 19 "1~30" 20 "1~30" 21 "1~30" 22 "1~30" 23 "1~30" 24 "1~30" 25 "1~30" 26 "1~30" 27 "1~30" 28 "1~30" 29 "1~30" 30 "1~30" 49 "Reserved" 50 "Reserved" 51 "Reserved" 52 "Reserved" 53 "Reserved" 54 "Reserved" 55 "Reserved" 56 "Reserved" 57 "Reserved" 58 "Reserved" 59 "Reserved" 60 "Reserved" 61 "Reserved" 62 "Reserved" 63 "Reserved" 64 "Reserved" 65 "Reserved" 66 "Reserved" 67 "Reserved" 68 "Reserved" 69 "Reserved" 70 "Reserved" 71 "Reserved" 72 "Reserved" 73 "Reserved" 74 "Reserved" 75 "Reserved" 76 "Reserved" 77 "Reserved" 78 "Reserved" 79 "Reserved" 80 "Reserved" 81 "Reserved" 82 "Reserved" 83 "Reserved" 84 "Reserved" 85 "Reserved" 86 "Reserved" 87 "Reserved" 88 "Reserved" 89 "Reserved" 90 "Reserved" 91 "Reserved" 92 "Reserved" 93 "Reserved" 94 "Reserved" 95 "Reserved" 96 "Reserved" 97 "Reserved" 98 "Reserved" 99 "Reserved" 100 "Reserved" 101 "Reserved" 102 "Reserved" 103 "Reserved" 104 "Reserved" 105 "Reserved" 106 "Reserved" 107 "Reserved" 108 "Reserved" 109 "Reserved" 110 "Reserved" 111 "Reserved" 112 "Reserved" 113 "Reserved" 114 "Reserved" 115 "Reserved" 116 "Reserved" 117 "Reserved" 118 "Reserved" 119 "Reserved" 120 "Reserved" 121 "Reserved" 122 "Reserved" 123 "Reserved" 124 "Reserved" 125 "Reserved" 126 "Reserved" 127 "Reserved" 128 "Reserved" 129 "Reserved" 130 "Reserved" 131 "Reserved" 132 "Reserved" 133 "Reserved" 134 "Reserved" 135 "Reserved" 136 "Reserved" 137 "Reserved" 138 "Reserved" 139 "Reserved" 140 "Reserved" 141 "Reserved" 142 "Reserved" 143 "Reserved" 144 "Reserved" 145 "Reserved" 146 "Reserved" 147 "Reserved" 148 "Reserved" 149 "Reserved" 150 "Reserved" 151 "Reserved" 152 "Reserved" 153 "Reserved" 154 "Reserved" 155 "Reserved" 156 "Reserved" 157 "Reserved" 158 "Reserved" 159 "Reserved" 160 "Reserved" 161 "Reserved" 162 "Reserved" 163 "Reserved" 164 "Reserved" 165 "Reserved" 166 "Reserved" 167 "Reserved" 168 "Reserved" 169 "Reserved" 170 "Reserved" 171 "Reserved" 172 "Reserved" 173 "Reserved" 174 "Reserved" 175 "Reserved" 176 "Reserved" 177 "Reserved" 178 "Reserved" 179 "Reserved" 180 "Reserved" 181 "Reserved" 182 "Reserved" 183 "Reserved" 184 "Reserved" 185 "Reserved" 186 "Reserved" 187 "Reserved" 188 "Reserved" 189 "Reserved" 190 "Reserved" 191 "Reserved" 192 "Reserved" 193 "Reserved" 194 "Reserved" 195 "Reserved" 196 "Reserved" 197 "Reserved" 198 "Reserved" 199 "Reserved" 200 "Reserved" 201 "Reserved" 202 "Reserved" 203 "Reserved" 204 "Reserved" 205 "Reserved" 206 "Reserved" 207 "Reserved" 208 "Reserved" 209 "Reserved" 210 "Reserved" 211 "Reserved" 212 "Reserved" 213 "Reserved" 214 "Reserved" 215 "Reserved" 216 "Reserved" 217 "Reserved" 218 "Reserved" 219 "Reserved" 220 "Reserved" 221 "Reserved" 222 "Reserved" 223 "Reserved" 224 "Reserved" 225 "Reserved" 226 "Reserved" 227 "Reserved" 228 "Reserved" 229 "Reserved" 230 "Reserved" 231 "Reserved" 232 "Reserved" 233 "Reserved" 234 "Reserved" 235 "Reserved" 236 "Reserved" 237 "Reserved" 238 "Reserved" 239 "Reserved" 240 "Reserved" 241 "Reserved" 242 "Reserved" 243 "Reserved" 244 "Reserved" 245 "Reserved" 246 "Reserved" 247 "Reserved" 248 "Reserved" 249 "Reserved" 250 "Reserved" 251 "Reserved" 252 "Reserved" 253 "Reserved" 254 "Reserved" 255 "Reserved"  ;
VAL_ 970 ADC_FrontEndParkInAvl 0 "No available" 1 "Rear-End Available" 2 "Front-End & Rear-End Available" 3 "Only Front-End Available"  ;
VAL_ 970 ADC_RPAobscancelCfm 0 "Obs not cancel" 1 "Obs cancel"  ;
